VERSION ""

NS_ :

BS_:

BU_: HS_TESTER CPM AHU MFD IPC DSP _delete
VAL_TABLE_ _Shared_KeyCount 13 "Thirteen" 12 "Twelve" 11 "Eleven" 10 "Ten" 9 "Nine" 8 "Eight" 7 "Seven" 6 "Six" 5 "Five" 4 "Four" 3 "Three" 2 "Two" 1 "One" 0 "Zero" 15 "Invalid" 14 "Unlimited" ;
VAL_TABLE_ _Shared_LevelLow 3 "Invalid" 2 "Unknown" 1 "Low" 0 "OK" ;
VAL_TABLE_ _Shared_0_Disable_1_Enable 1 "Enable" 0 "Disable" ;
VAL_TABLE_ _Shared_PrkAidStat 3 "Faulted" 2 "Unused" 1 "Enabled" 0 "Disabled" ;
VAL_TABLE_ _Shared_PrkAidZone 15 "Zone_15" 14 "Zone_14" 13 "Zone_13" 12 "Zone_12" 11 "Zone_11" 10 "Zone_10" 9 "Zone_9" 8 "Zone_8" 7 "Zone_7" 6 "Zone_6" 5 "Zone_5" 4 "Zone_4" 3 "Zone_3" 2 "Zone_2" 1 "Zone_1" 0 "Off" ;
VAL_TABLE_ _Shared_PA_Chime 15 "Zone15_Chime" 14 "Zone14_Chime" 13 "Zone13_Chime" 12 "Zone12_Chime" 11 "Zone11_Chime" 10 "Zone10_Chime" 9 "Zone9_Chime" 8 "Zone8_Chime" 7 "Zone7_Chime" 6 "Zone6_Chime" 5 "Zone5_Chime" 4 "Zone4_Chime" 3 "Zone3_Chime" 2 "Zone2_Chime" 1 "Zone1_Chime" 0 "No_Chime" ;
VAL_TABLE_ _Shared_SeatFnChng2 15 "Fault" 14 "Not_Used8" 13 "Not_Used7" 12 "Not_Used6" 11 "Not_Used5" 10 "Not_Used4" 9 "Not_Used3" 8 "Not_Used2" 7 "Not_Used1" 6 "High" 5 "Low" 4 "Off" 3 "Decrease" 2 "Increase" 1 "Not_Used" 0 "Inactive" ;
VAL_TABLE_ _Shared_Chime 63 "Chime_62" 4 "Chime_3" 3 "Chime_2" 2 "Chime_1" 1 "NoChime" 0 "Inactive" ;
VAL_TABLE_ _Shared_AwdRnge 7 "Unknown" 6 "High_Range_2wd" 5 "High_Range_Auto" 4 "High_Range_Locked" 3 "Neutral" 2 "Low_Range_2wd" 1 "Low_Range_Auto" 0 "Low_Range_Locked" ;
VAL_TABLE_ _Shared_Pers 7 "Unused_3" 6 "Unused_2" 5 "Unused_1" 4 "Vehicle" 3 "PERS_4" 2 "PERS_3" 1 "PERS_2" 0 "PERS_1" ;
VAL_TABLE_ _Shared_AR_RUAudioSource_NA 15 "iPod" 14 "USB" 13 "BTAudio" 0 "AmfmRadio" 1 "FrontDisc" 2 "SDARS_DAB" 3 "InDashCdChanger" 4 "VoiceRecogniser" 5 "TelematicUnit" 6 "BluetoothPhone" 7 "RearDisc" 8 "APIM" 9 "FrontAuxInput" 10 "Navigation" 11 "RearAux" 12 "NotReq" ;
VAL_TABLE_ _Shared_PsgrMemory 8 "Recall_4" 7 "Recall_3" 6 "Recall_2" 5 "Recall_1" 4 "Store_4" 3 "Store_3" 2 "Store_2" 1 "Store_1" 0 "Inactive" ;
VAL_TABLE_ _Shared_Stms_Cshn_Lmbr 3 "High" 2 "Low" 1 "Off" 0 "Null" ;
VAL_TABLE_ _Shared_SeatFn_Null 7 "CushionMassage" 6 "LumbarMassage" 5 "UpperBolster" 4 "LowerBolster" 3 "UpperLumbar" 2 "MiddleLumbar" 1 "LowerLumbar" 0 "Null" ;
VAL_TABLE_ _Shared_0_NotUpdating_1_Updating 1 "Updating" 0 "NotUpdating" ;
VAL_TABLE_ _Shared_SeatFn_Inactive 7 "CushionMassage" 6 "LumbarMassage" 5 "UpperBolster" 4 "LowerBolster" 3 "UpperLumbar" 2 "MiddleLumbar" 1 "LowerLumbar" 0 "Inactive" ;
VAL_TABLE_ _Shared_SeatFnChng 2 "Decrease" 1 "Increase" 0 "Inactive" ;
VAL_TABLE_ _Shared_7F_Null 127 "Null" ;
VAL_TABLE_ _Shared_0_Invld_1_Vld 1 "Valid" 0 "Invalid" ;
VAL_TABLE_ _Shared_0_NotAvlble_1_Avlble 1 "Available" 0 "Not_Available" ;
VAL_TABLE_ _Shared_MonthReport 2 "Available" 1 "Unavailable" 0 "No_Data_Exists" ;
VAL_TABLE_ _Shared_0_NoReq_1_Req 1 "Request" 0 "NoRequest" ;
VAL_TABLE_ _Shared_TempDispDigit 2 "_5" 1 "_0" 0 "OFF" ;
VAL_TABLE_ _Shared_BlowInd 15 "Display_Blank" 14 "14_Indicators_On" 13 "13_Indicators_On" 12 "12_Indicators_On" 11 "11_Indicators_On" 10 "10_Indicators_On" 9 "9_Indicators_On" 8 "8_Indicators_On" 7 "7_Indicators_On" 6 "6_Indicators_On" 5 "5_Indicators_On" 4 "4_Indicators_On" 3 "3_Indicators_On" 2 "2_Indicators_On" 1 "1_Indicator_On" 0 "Indicators_Off" ;
VAL_TABLE_ _Shared_TempUnit 2 "Fahrenheit" 1 "Celsius" 0 "Off" ;
VAL_TABLE_ _Shared_CondSeat 7 "Unused" 6 "Level_3_Heating" 5 "Level_2_Heating" 4 "Level_1_Heating" 3 "Level_3_Cooling" 2 "Level_2_Cooling" 1 "Level_1_Cooling" 0 "Off" ;
VAL_TABLE_ _Shared_Btn_Stt 3 "Unused" 2 "Disabled" 1 "Active" 0 "Enabled_Inactive" ;
VAL_TABLE_ _Shared_E_Unlimited_F_NoDatEx 15 "NoDataExist" 14 "Unlimited" ;
VAL_TABLE_ _Shared_Speed 31 "mph90" 30 "mph85" 29 "mph80" 28 "mph75" 27 "mph70" 26 "mph65" 25 "mph60" 24 "mph55" 23 "mph50" 22 "mph45" 21 "mph40" 20 "Kmh165" 19 "Kmh160" 18 "Kmh155" 17 "Kmh150" 16 "Kmh145" 15 "Kmh140" 14 "Kmh135" 13 "Kmh130" 12 "Kmh125" 11 "Kmh120" 10 "Kmh115" 9 "Kmh110" 8 "Kmh105" 7 "Kmh100" 6 "kmh95" 5 "kmh90" 4 "kmh85" 3 "kmh80" 2 "kmh75" 1 "kmh70" 0 "Off" ;
VAL_TABLE_ _Shared_0_NoDatEx_1_Off_2_On_3_R 3 "Reserved" 2 "On" 1 "Off" 0 "NoDataExist" ;
VAL_TABLE_ _Shared_E_Unlimited_F_Inactive 15 "Inactive" 14 "Unlimited" ;
VAL_TABLE_ _Shared_0_No_Dat_Ex_1_Off_2_On 2 "On" 1 "Off" 0 "No_Data_Exists" ;
VAL_TABLE_ _Shared_TirePress 14 "Tires_not_trained" 13 "Training_Complete" 12 "Train_InsideLeftRear_tire" 11 "Train_OutsideLeftRear_tire" 10 "Train_LeftRear_tire" 9 "Train_InsideRtRear__tire" 8 "Train_OutsideRtRear_tire" 7 "Train_RightRear_tire" 6 "Train_RightFront_tire" 5 "Train_LeftFront_tire" 4 "Systm_Activ_Composite_Stat" 3 "Low_Composite_Stat" 2 "Sensr_Fault_Composite_Stat" 1 "Systm_Fault_Composite_Stat" 0 "Unknown_Composite_Stat" ;
VAL_TABLE_ _Shared_0_Inactive_1_Off_2_On 2 "On" 1 "Off" 0 "Inactive" ;
VAL_TABLE_ _Shared_Petal 7 "NoDataExist" 6 "NotUsed" 5 "petal_1_to_5" 4 "petal_1_to_4" 3 "petal_1_to_3" 2 "petal_1_to_2" 1 "petal_1" 0 "all_petals_off" ;
VAL_TABLE_ _Shared_WarningChime 1 "Chime_On" 0 "Chime_Off" ;
VAL_TABLE_ _Shared_0_NoDatEx_1_Off_2_On_3_r 3 "reserved" 2 "On" 1 "Off" 0 "NoDataExist" ;
VAL_TABLE_ _Shared_0_Inactive_1_Off_2_On_3_ 3 "reserved" 2 "On" 1 "Off" 0 "Inactive" ;
VAL_TABLE_ _Shared_0_Inctve_1_Enbl_2_Disbl 2 "Disable" 1 "Enable" 0 "Inactive" ;
VAL_TABLE_ _Shared_FE_Unknown_FF_Invalid 254 "Unknown" 255 "Invalid" ;
VAL_TABLE_ _Shared_1FE_Unknown_1FF_Invalid 511 "Invalid" 510 "Unknown" ;
VAL_TABLE_ _Shared_3FFE_Unknown_3FFF_Invali 16383 "Invalid" 16382 "Unknown" ;
VAL_TABLE_ _Shared_3E_Unknown_3F_Invalid 63 "Invalid" 62 "Unknown" ;
VAL_TABLE_ _Shared_1E_Unknown_1F_Invalid 31 "Invalid" 30 "Unknown" ;
VAL_TABLE_ _Shared_FF__invalid 255 "invalid" ;
VAL_TABLE_ _Shared_Closed_Ajar 1 "Ajar" 0 "Closed" ;
VAL_TABLE_ _Shared_MediaSrc 7 "Status7" 6 "Status6" 5 "Status5" 4 "Status4" 3 "Status3" 2 "Status2" 1 "Status1" 0 "NoDataExists" ;
VAL_TABLE_ _Shared_FF_Invalid 255 "Invalid" ;
VAL_TABLE_ _Shared_OffOnUnknownInvalid 1 "On" 0 "Off" 3 "Invalid" 2 "Unknown" ;
VAL_TABLE_ _Shared_0_Out_1_In 1 "In" 0 "Out" ;
VAL_TABLE_ _Shared_InactiveActive 1 "Active" 0 "Inactive" ;
VAL_TABLE_ _Shared_Off_On 1 "On" 0 "Off" ;
VAL_TABLE_ _Shared_QualityFactor 3 "OK" 2 "Not_Within_Specifications" 1 "No_Data_Exists" 0 "Fault" ;
VAL_TABLE_ _Shared_No_Yes 1 "Yes" 0 "No" ;
VAL_TABLE_ _Shared_1F_Fault 31 "Fault" ;
VAL_TABLE_ _Shared_DrvMde 7 "Faulty" 6 "NotUsed3" 5 "NotUsed2" 4 "NotUsed1" 3 "Track" 2 "Snow_Wet" 1 "Sport" 0 "Normal" ;
VAL_TABLE_ _Shared_3FE_Unknown_3FF_Fault 1023 "Fault" 1022 "Unknown" ;
VAL_TABLE_ _Shared_OffOnFlash 3 "Not_Used" 2 "Flash" 1 "On" 0 "Off" ;
VAL_TABLE_ _Shared_FE_Unknown_FF_Fault 255 "Fault" 254 "Unknown" ;
VAL_TABLE_ _Shared_FFFF_Invalid 65535 "Invalid" ;
VAL_TABLE_ _Shared_OffOn2Flash 3 "Fast_Flash" 2 "Slow_Flash" 1 "On" 0 "Off" ;
VAL_TABLE_ _Shared_FFE_Unknown_FFF_Fault 4095 "Fault" 4094 "Unknown" ;
VAL_TABLE_ _Shared_7E_NoDatExts_7F_Faulty 127 "Faulty" 126 "NoDataExists" ;
VAL_TABLE_ _Shared_F_ModColdBoot 15 "Mod_Cold_Boot" ;
VAL_TABLE_ _Shared_AudioSource 2 "Stereo_SNK" 1 "Mono_SNK" 0 "OFF" ;
VAL_TABLE_ _Shared_0_Discnnct_1_Cnnct 1 "Connect" 0 "Disconnect" ;
VAL_TABLE_ _Shared_0_Denied_1_Granted 1 "Granted" 0 "Denied" ;
VAL_TABLE_ _Shared_FocusBar 7 "Focus_Bar_NA_on_current_Pop_Up" 6 "Focus_Bar_on_List_Item_6" 5 "Focus_Bar_on_List_Item_5" 4 "Focus_Bar_on_List_Item_4" 3 "Focus_Bar_on_List_Item_3" 2 "Focus_Bar_on_List_Item_2" 1 "Focus_Bar_on_List_Item_1" 0 "No_visible_Focus_Bar" ;
VAL_TABLE_ _Shared_PrimaryAudioSource 5 "CPM_Stereo" 4 "CPM_Mono" 1 "Tuner_AM" 0 "OFF" ;
VAL_TABLE_ _Shared_Mute_Unmute 1 "Unmute" 0 "Mute" ;
VAL_TABLE_ _Shared_0_NOP_1_CPM 1 "CPM" 0 "NOP" ;
VAL_TABLE_ _Shared_Released_Pressed 2 "Button_Pressed" 1 "Button_Released" 0 "NOP" ;
VAL_TABLE_ _Shared_FFFE_Unkn_FFFF_Invld 65535 "Invalid" 65534 "Unknown" ;
VAL_TABLE_ _Shared_AR_RURquesterPriority 0 "EmergencyServ" 1 "TelService" 2 "AutoAnswer" 3 "Ta" 4 "PttMutevoice" 5 "NavUserVoiceCmd" 6 "NavSysVoiceCmd" 7 "Radio" 8 "Disc" 9 "Alarm" 10 "Ptynews" 11 "Aux_ExtSource" 12 "BT_BTNavAndTelMute" 13 "ManualAudioMute" 14 "NotReq" ;
VAL_TABLE_ _Shared_ComPlayDigit 15 "Invalid" 14 "CommandNotIssued" 13 "Reserved3" 12 "Reserved2" 11 "Reserved1" 10 "Reserved" ;
VAL_TABLE_ _Shared_ComPlayType 4 "Track" 3 "FordPlaylist" 2 "FordFolder" 1 "CommandNotIssued" 0 "Invalid" ;
VAL_TABLE_ _Shared_ComPlayMode 10 "RepeatOff" 9 "RepeatTrack" 8 "RepeatFolder" 7 "RepeatCD" 6 "ShuffleOff" 5 "ShuffleFolder" 4 "ShuffleList" 3 "ShuffleCD" 2 "ShuffleAll" 1 "CommandNotIssued" 0 "Invalid" ;
VAL_TABLE_ _Shared_ComPlaySource 7 "BTAudio" 6 "iPod" 5 "USB" 4 "SDCard" 3 "CDChanger" 2 "SingleCD" 1 "CommandNotIssued" 0 "Invalid" ;
VAL_TABLE_ _Shared_NoUpdate_Update 1 "Update" 0 "NoUpdate" ;
VAL_TABLE_ _Shared_0_Inactive_1_Cancel 1 "Cancel" 0 "Inactive" ;
VAL_TABLE_ _Shared_IncomingCall 2 "DeclineIncomingCall" 1 "AcceptIncomingCall" 0 "Inactive" ;
VAL_TABLE_ _Shared_MCChannel 7 "MCChannel7" 6 "MCChannel6" 5 "MCChannel5" 4 "MCChannel4" 3 "MCChannel3" 2 "MCChannel2" 1 "MCChannel1" 0 "Inactive" ;
VAL_TABLE_ _Shared_LangUpdate 2 "Language_Not_Supported" 1 "Language_Updated" 0 "Inactive" ;
VAL_TABLE_ _Shared_LangSel 30 "Slovak" 29 "Arabic" 28 "Taiwanese" 27 "Mandarin_Chinese" 26 "Korean" 25 "AU_English" 24 "Japanese" 23 "Braz_Portuguese" 22 "EU_Portuguese" 21 "Finish" 20 "Norwegian" 19 "Danish" 18 "Swedish" 17 "Hungarian" 16 "Greek" 15 "Czech" 14 "Polish" 13 "Flemish" 12 "Dutch" 11 "Russian" 10 "Turkish" 9 "Mex_Spanish" 8 "EU_Spanish" 7 "Cana_French" 6 "EU_French" 5 "Italian" 4 "German" 3 "NA_English" 2 "UK_English" 1 "Unknown" 0 "Invalid" ;
VAL_TABLE_ _Shared_TirePressStat 4 "Alert" 15 "Not_Supported" 3 "Fault" 2 "Low" 1 "Normal" 0 "Unknown" ;
VAL_TABLE_ _Shared_Not_Pressed_Pressed 1 "Pressed" 0 "Not_Pressed" ;
VAL_TABLE_ _Shared_0_Off 0 "Off" ;
VAL_TABLE_ _Shared_Enabled_Active_Disabled 2 "Disabled" 1 "Active" 0 "Enabled_Inactive" ;
VAL_TABLE_ _Shared_RVC_Zoom 7 "Unknown" 6 "Invalid" 5 "Zoom_Level_V" 4 "Zoom_Level_IV" 3 "Zoom_Level_III" 2 "Zoom_Level_II" 1 "Zoom_Level_I" 0 "Off" ;
VAL_TABLE_ _Shared_RVC_HMI 3 "Not_Used" 2 "Inactive" 1 "Active" 0 "Invalid" ;
VAL_TABLE_ _Shared_ButtonNotPressed_Pressed 1 "Button_Pressed" 0 "Button_Not_Pressed" ;
VAL_TABLE_ _Shared_QualityFactor_CMDB 3 "OK" 2 "Not_Within_Specifications" 1 "No_Data_Exists" 0 "Faulty" ;
VAL_TABLE_ _Shared_WhlDir 3 "Failed" 2 "Unknown" 1 "Backward" 0 "Forward" ;
VAL_TABLE_ _Shared_RearSystemMode 4 "Enabled_or_Auto" 3 "Floor" 2 "Panel_Floor" 1 "Panel" 0 "Off" ;
VAL_TABLE_ _Shared_Cond_Seat_Req 3 "RCCM_Is_Master" 2 "Heating_Requested" 1 "Cooling_Requested" 0 "Off" ;
VAL_TABLE_ _Shared_Cond_Seat_Lvl_RCCM 6 "Fault" 5 "Level_5_Most_Conditioning" 4 "Level_4" 3 "Level_3" 2 "Level_2" 1 "Level_1_Least_Conditioning" 0 "Off" ;
VAL_TABLE_ _Shared_Cond_Load_Shed 3 "Automatic_Override" 2 "HMI_Override" 1 "No_HMI_Override" 0 "No_Shed" ;
VAL_TABLE_ _Shared_UpdateBit 1 "Fresh_data" 0 "Unchanged_data" ;
VAL_TABLE_ _Shared_Fan_Bars_Disply 7 "Fan_Symbol__All_bars_ON" 6 "Fan_Symbol__1st_6_bars_ON" 5 "Fan_Symbol__1st_5_bars_ON" 4 "Fan_Symbol__1st_4_bars_ON" 3 "Fan_Symbol__1st_3_bars_ON" 2 "Fan_Symbol__1st_2_bars_ON" 1 "Fan_Symbol__1st_bar_ON" 0 "Fan_Symbol__All_bars_OFF" ;
VAL_TABLE_ _Shared_OpMode 7 "FastRewindSpeed2" 6 "FastRewindSpeed1" 5 "FastForwardSpeed2" 4 "FastForwardSpeed1" 3 "Pause" 2 "Play" 1 "Stop" 0 "Invalid" ;
VAL_TABLE_ _Shared_0_Invld_1_Inactv_2_Actv 0 "Invalid" 2 "Active" 1 "Inactive" ;
VAL_TABLE_ _Shared_MyKeyVolUp 2 "NotUpdated" 1 "Updated" 0 "Invalid" ;
VAL_TABLE_ _Shared_0_No_Req_1_Req 1 "Request" 0 "No_Request" ;
VAL_TABLE_ _Shared_AC_ManReq 2 "No_Man_Req" 1 "Man_Req_On" 0 "Man_Req_Off" ;
VAL_TABLE_ _Shared_Cond_Seat_Lvl 6 "Fault" 5 "Level_5_Most_Conditioning" 4 "Level_4_Most_Conditioning" 3 "Level_3_Most_Conditioning" 2 "Level_2_Most_Conditioning" 1 "Level_1_Most_Conditioning" 0 "Off" ;
VAL_TABLE_ _Shared_SeatSftBtnSt 7 "Disabled" 6 "Cl_Lo_Med_Hi_Ind_En_Active" 5 "Cl_Lo_Med_Ind_En_Active" 4 "Cl_Lo_Ind_En_Active" 3 "Ht_Lo_Med_Hi_Ind_En_Active" 2 "Ht_Lo_Med_Ind_En_Active" 1 "Ht_Lo_Ind_En_Active" 0 "No_Ind_Enabled_Active" ;
VAL_TABLE_ _Shared_0_EnbldInactve_1_Actve 1 "Active" 0 "Enabled_Inactive" ;
VAL_TABLE_ _Shared_ClmtCtrlSeat 128 "H3_High_Heat__MAX" 64 "H2_Medium_Heat" 32 "H1_Low_Heat" 16 "C3_High_Cool__MAX" 8 "C2_Medium_Cool" 4 "C1_Low_Cool" 2 "Off" ;
VAL_TABLE_ _Shared_Attenuation 7 "Unknown" 6 "Attenuation_6" 5 "Attenuation_5" 4 "Attenuation_4" 3 "Attenuation_3" 2 "Attenuation_2" 1 "Attenuation_1" 0 "Inactive" ;
VAL_TABLE_ _Shared_ChimeOccurence 15 "Continuous" 14 "14Repititions" 13 "13Repititions" 12 "12Repititions" 11 "11Repititions" 10 "10Repititions" 9 "9Repititions" 8 "8Repititions" 7 "7Repititions" 6 "6Repititions" 5 "5Repititions" 4 "4Repititions" 3 "3Repititions" 2 "2Repititions" 1 "PlayOnce" 0 "Inactive" ;
VAL_TABLE_ _Shared_ChimeTimeCriticality 2 "Low" 1 "High" 0 "Inactive" ;
VAL_TABLE_ _Shared_Directionality 3 "RearSpeakers" 2 "FrontSpeakers" 1 "ALL" 0 "Inactive" ;
VAL_TABLE_ _Shared_SetVolume 59 "+29Steps" 58 "+28Steps" 57 "+27Steps" 56 "+26Steps" 55 "+25Steps" 54 "+24Steps" 53 "+23Steps" 52 "+22Steps" 51 "+21Steps" 50 "+20Steps" 49 "+19Steps" 48 "+18Steps" 47 "+17Steps" 46 "+16Steps" 45 "+15Steps" 44 "+14Steps" 43 "+13Steps" 42 "+12Steps" 41 "+11Steps" 40 "+10Steps" 39 "+9Steps" 38 "+8Steps" 37 "+7Steps" 36 "+6Steps" 35 "+5Steps" 34 "+4Steps" 28 "-2Steps" 27 "-3Steps" 26 "-4Steps" 25 "-5Steps" 24 "-6Steps" 23 "-7Steps" 22 "-8Steps" 21 "-9Steps" 20 "-10Steps" 19 "-11Steps" 18 "-12Steps" 17 "-13Steps" 16 "-14Steps" 15 "-15Steps" 14 "-16Steps" 13 "-17Steps" 12 "-18Steps" 11 "-19Steps" 10 "-20Steps" 9 "-21Steps" 8 "-22Steps" 7 "-23Steps" 6 "-24Steps" 5 "-25Steps" 4 "-26Steps" 3 "-27Steps" 60 "+30Steps" 33 "+3Steps" 32 "+2Steps" 31 "+1Step" 30 "NotPressed_Inactive" 29 "-1Step" 2 "-28Steps" 1 "-29Steps" 0 "-30Steps" ;
VAL_TABLE_ _Shared_Sound 2 "Surround" 1 "Stereo" 0 "Inactive" ;
VAL_TABLE_ _Shared_SensorDist 1 "SensorDistDataValid" 0 "Invalid" ;
VAL_TABLE_ _Shared_ICIBtn 15 "Idle" 5 "Stuck" 4 "LongEvent" 3 "ShortElapsed" 2 "ShortEvent" 1 "Active" 0 "Inactive" ;
VAL_TABLE_ _Shared_DispUpdate 1 "HasRecentlyChanged" 0 "NoChange" ;
VAL_TABLE_ _Shared_TUPresetArea_Rq 13 "reserved" 12 "GetSAT3PresetData" 11 "GetSAT2PresetData" 15 "reserved_last" 10 "GetSAT1PresetData" 9 "GetDAB2PresetData" 8 "GetDAB1PresetData" 7 "GetDAB3PresetData" 6 "GetAmPresetData" 5 "GetAmAstPresetData" 4 "GetFmAstPresetData" 3 "GetFm3PresetData" 2 "GetFm2PresetData" 1 "GetFm1PresetData" 0 "Inactive" ;
VAL_TABLE_ _Shared_SetCurrTUBand 13 "reserved1" 12 "DAB3" 11 "SAT3" 10 "SAT2" 15 "reserved_last" 9 "SAT1" 8 "DAB2" 7 "DAB1" 6 "AmAst" 5 "Am" 4 "FmAst" 3 "Fm3" 2 "Fm2" 1 "Fm1" 0 "Inactive" ;
VAL_TABLE_ _Shared_TUServiceLink 3 "reserved" 2 "Inactive" 1 "Active" 0 "Invalid" ;
VAL_TABLE_ _Shared_ComTUSIDValid 1 "Validation" 0 "Invalid" ;
VAL_TABLE_ _Shared_0_Inactive_1_GetStatus 1 "Getstatus" 0 "Inactive" ;
VAL_TABLE_ _Shared_BTDeviceIndex 15 "BTDeviceIndex15" 14 "BTDeviceIndex14" 13 "BTDeviceIndex13" 12 "BTDeviceIndex12" 11 "BTDeviceIndex11" 10 "BTDeviceIndex10" 9 "BTDeviceIndex9" 8 "BTDeviceIndex8" 7 "BTDeviceIndex7" 6 "BTDeviceIndex6" 5 "BTDeviceIndex5" 4 "BTDeviceIndex4" 3 "BTDeviceIndex3" 2 "BTDeviceIndex2" 1 "BTDeviceIndex1" 0 "Inactive" ;
VAL_TABLE_ _Shared_BTFeatGroup 15 "Reserved_last" 8 "Reserved" 7 "Office" 6 "Video" 5 "Voice" 4 "MobileCom" 3 "Nav" 2 "MP" 1 "Radio" 0 "ALL" ;
VAL_TABLE_ _Shared_CutItem_Invalid 3 "ThreeQuarterFromTheBeginningOneQ" 2 "End" 1 "Beginning" 0 "Invalid" ;
VAL_TABLE_ _Shared_DB1Filter_10Bit 1023 "All" 1022 "SIIndex_1022" 1 "SIIndex_1" 0 "NotEngaged" ;
VAL_TABLE_ _Shared_DB1Filter_16Bit 65535 "All" 65534 "SIIndex_65534" 1 "SIIndex_1" 0 "NotEngaged" ;
VAL_TABLE_ _Shared_DSP_AlertChannel 3 "Initialized_for_chimes" 2 "Muted" 1 "Reserved" 0 "Inactive" ;
VAL_TABLE_ _Shared_Band 15 "Reserved1" 9 "Reserved" 8 "Amplitude_8" 7 "Amplitude_7" 6 "Amplitude_6" 4 "Amplitude_4" 2 "Amplitude_2" 5 "Amplitude_5" 3 "Amplitude_3" 1 "Amplitude_1" 0 "Amplitude_0" ;
VAL_TABLE_ _Shared_ChimeAlertChan 2 "Reserved" 1 "Mute" 0 "Inactive" ;
VAL_TABLE_ _Shared_ChimeSupprtd 2 "Not_Supported" 1 "Supported" 0 "Inactive" ;
VAL_TABLE_ _Shared_Chime_NotRecgnizd 0 "Inactive" 1 "Chime_Not_Recognized" ;
VAL_TABLE_ _Shared_InfotainmentVer_B 1 "B299" 0 "invalid" ;
VAL_TABLE_ _Shared_NotSupported_Supported 1 "Supported" 0 "Not_Supported" ;
VAL_TABLE_ _Shared_Skip 2 "Decrement" 1 "Increment" 0 "Inactive" ;
VAL_TABLE_ _Shared_IntScan_Shuffle_2 7 "Reserved4" 6 "Reserved3" 5 "Reserved2" 4 "Reserved1" 3 "OnTheFolderSelGroup" 2 "OnTheDevice" 1 "Off" 0 "Inactive" ;
VAL_TABLE_ _Shared_IntScan_Shuffle 3 "OnTheFolderSelGroup" 2 "OnTheDevice" 1 "Off" 0 "Invalid" ;
VAL_TABLE_ _Shared_MicMute 3 "Reserved" 2 "MicrophoneUnmute" 1 "MicrophoneMute" 0 "Inactive" ;
VAL_TABLE_ _Shared_AudioSource2 5 "SDCard" 4 "Reserved" 3 "USB" 2 "BTAudio" 1 "CD" 0 "Inactive" ;
VAL_TABLE_ _Shared_OpMode_0_Inactv 7 "FastRewind20" 6 "FastRewind10" 5 "FastForward20" 4 "FastForward10" 3 "Pause" 2 "Play" 1 "Stop" 0 "Inactive" ;
VAL_TABLE_ _Shared_ErrorSt 8 "NoDataInFolder" 7 "NoRespFromDevice" 6 "UnableToRead" 5 "NoDataOnDevice" 4 "FileSysNotSupported" 3 "DeviceNotSupported" 2 "InvalidFile" 1 "NoError" 0 "Invalid" ;
VAL_TABLE_ _Shared_FunctStatus 7 "Reserved2" 6 "Reserved1" 5 "Reserved" 4 "Reading" 3 "Ready" 2 "Initilization" 1 "Free" 0 "Invalid" ;
VAL_TABLE_ _Shared_OpMode_0_Invld 7 "FastRewind20" 6 "FastRewind10" 5 "FastForward20" 4 "FastForward10" 3 "Pause" 2 "Play" 1 "Stop" 0 "Invalid" ;
VAL_TABLE_ _Shared_Repeat 7 "Reserved2" 6 "Reserved1" 5 "Reserved" 4 "RepeatOnDevice" 3 "RepeatOnFolder" 2 "RepeatOnTrack" 1 "Off" 0 "Invalid" ;
VAL_TABLE_ _Shared_NbrOfItms 1 "OneItem" 0 "Standard" ;
VAL_TABLE_ _Shared_DB1SetConf 31 "UnknownActive" 30 "Reserved_last" 9 "Reserved" 8 "Podcast" 7 "Audiobook" 6 "Composer" 5 "Track" 4 "Genre" 3 "Album" 2 "Artist" 1 "Playlist" 0 "Root" ;
VAL_TABLE_ _Shared_VoiceCommand 2 "NotOk" 1 "Ok" 0 "Invalid" ;
VAL_TABLE_ _Shared_DSPProgram 7 "Reserved2" 6 "Reserved1" 5 "Voice" 4 "Rock" 0 "Invalid" 1 "Normal" 2 "Pop" 3 "Classical" ;
VAL_TABLE_ _Shared_CutItem_Inactive 3 "Inactive" 2 "ThreeQuarterFromTheBeginningOneQ" 1 "End" 0 "Beginning" ;
VAL_TABLE_ _Shared_FolderContent 2 "Inactive" 1 "RequestContentFromParentFolderOf" 0 "RequestContentFromParameterFolde" ;
VAL_TABLE_ _Shared_EndTelService 1 "EndOngoingTelephonyCall" 0 "Inactive" ;
VAL_TABLE_ _Shared_0_Invalid_FF_NoValidPres 255 "NoValidPreset" 0 "Invalid" ;
VAL_TABLE_ _Shared_SetCurrentStatOp 0 "Inactive" 1 "SetCurrentFrequency" 2 "SetCurrentPiCode" 3 "SetCurrentStation" ;
VAL_TABLE_ _Shared_CDSetRepeat 0 "Inactive" 1 "RepeatOnTrack" 2 "Off" 3 "OnFolder" ;
VAL_TABLE_ _Shared_0_Inactive_1_On_2_Off_3_ 0 "Inactive" 1 "On" 2 "Off" 3 "OnFolder" ;
VAL_TABLE_ _Shared_InfotainmentVer_C 0 "Invalid" 1 "C214Cd132My2003" 2 "C307My2004" ;
VAL_TABLE_ _Shared_FunctionStatus 7 "RemoveDisc" 0 "Invalid" 1 "Reading" 2 "Loading" 3 "Loaded" 4 "Insert" 5 "PreparingToEject" 6 "Ejecting" ;
VAL_TABLE_ _Shared_CD_On_Off_OnFolder 0 "Invalid" 1 "On" 2 "Off" 3 "OnFolder" ;
VAL_TABLE_ _Shared_0_Invalid_1_Off_2_On 0 "Invalid" 1 "Off" 2 "On" ;
VAL_TABLE_ _Shared_CDError 0 "Invalid" 1 "NoError" 2 "NoDiscs" 3 "UnableToReadDisc" ;
VAL_TABLE_ _Shared_VRM_ComSt 0 "Invalid" 1 "CommandNotIssued" 2 "On" 3 "Off" ;
VAL_TABLE_ _Shared_TripCompUnit 0 "TripComputer_metric" 1 "TripComputer_imperial" ;
VAL_TABLE_ _Shared_TempUnit2 0 "Temperature_deg_c" 1 "Temperature_deg_f" ;
VAL_TABLE_ _Shared_ModeSelect 3 "NotUsed" 2 "On" 1 "Off" 0 "NoModeSelected" ;
VAL_TABLE_ _Shared_EngExhMdeQuiet 3 "Faulty" 2 "QuietExhaust" 1 "LoudExhaust" 0 "Null" ;
VAL_TABLE_ _Shared_0_Inactive_1_On_2_Off 0 "Inactive" 1 "On" 2 "Off" ;
VAL_TABLE_ _Shared_IncCallOption 0 "Inactive" 1 "RejectAll" 2 "AcceptIncomingCall" 3 "Silent" ;
VAL_TABLE_ _Shared_PhoneIndex 0 "Inactive" 1 "PhoneIndex1" 2 "PhoneIndex2" 3 "PhoneIndex3" 4 "PhoneIndex4" 5 "PhoneIndex5" 6 "PhoneIndex6" ;
VAL_TABLE_ _Shared_ARReqstrSystem 0 "FrontRequester" 1 "RearRequester" ;
VAL_TABLE_ _Shared_AROperationType 0 "Inactive" 1 "Requestaudioresource" 2 "Releaseaudioresource" 3 "Releaseallaudioresouces" 4 "Getresourceupdate" 5 "Getallresourceupdates" ;
VAL_TABLE_ _Shared_SurndSndUpmix 4 "Audience" 3 "On_Stage" 2 "Surround" 1 "Stereo" 0 "Inactive" ;
VAL_TABLE_ _Shared_SidePrkSns 15 "NotUsed" 14 "NotFullyScannedYet" 13 "NoObjectInSector" 12 "Zone12" 11 "Zone11" 10 "Zone10" 9 "Zone9" 8 "Zone8" 7 "Zone7" 6 "Zone6" 5 "Zone5" 4 "Zone4" 3 "Zone3" 2 "Zone2" 1 "Zone1" 0 "Off" ;
VAL_TABLE_ _Shared_VRM_ModeReq 0 "Inactive" 1 "Off" 2 "Reserved" 3 "On" ;

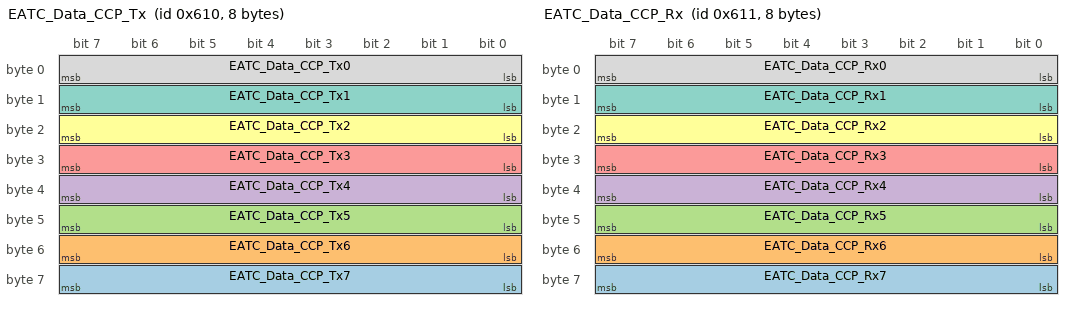
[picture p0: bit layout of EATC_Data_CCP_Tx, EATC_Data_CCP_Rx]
BO_ 1552 EATC_Data_CCP_Tx: 8 MFD
 SG_ EATC_Data_CCP_Tx7 : 63|8@0+ (1,0) [0|255] ""  HS_TESTER
 SG_ EATC_Data_CCP_Tx6 : 55|8@0+ (1,0) [0|255] ""  HS_TESTER
 SG_ EATC_Data_CCP_Tx5 : 47|8@0+ (1,0) [0|255] ""  HS_TESTER
 SG_ EATC_Data_CCP_Tx4 : 39|8@0+ (1,0) [0|255] ""  HS_TESTER
 SG_ EATC_Data_CCP_Tx3 : 31|8@0+ (1,0) [0|255] ""  HS_TESTER
 SG_ EATC_Data_CCP_Tx2 : 23|8@0+ (1,0) [0|255] ""  HS_TESTER
 SG_ EATC_Data_CCP_Tx1 : 15|8@0+ (1,0) [0|255] ""  HS_TESTER
 SG_ EATC_Data_CCP_Tx0 : 7|8@0+ (1,0) [0|255] ""  HS_TESTER

BO_ 1553 EATC_Data_CCP_Rx: 8 HS_TESTER
 SG_ EATC_Data_CCP_Rx7 : 63|8@0+ (1,0) [0|255] ""  MFD
 SG_ EATC_Data_CCP_Rx6 : 55|8@0+ (1,0) [0|255] ""  MFD
 SG_ EATC_Data_CCP_Rx5 : 47|8@0+ (1,0) [0|255] ""  MFD
 SG_ EATC_Data_CCP_Rx4 : 39|8@0+ (1,0) [0|255] ""  MFD
 SG_ EATC_Data_CCP_Rx3 : 31|8@0+ (1,0) [0|255] ""  MFD
 SG_ EATC_Data_CCP_Rx2 : 23|8@0+ (1,0) [0|255] ""  MFD
 SG_ EATC_Data_CCP_Rx1 : 15|8@0+ (1,0) [0|255] ""  MFD
 SG_ EATC_Data_CCP_Rx0 : 7|8@0+ (1,0) [0|255] ""  MFD

BO_ 597 AUDIO_RSE_WORD_Tx: 8 AHU
 SG_ AUDIO_RSE_WORD_Tx : 7|64@0+ (1,0) [0|1.84467440737096E+019] "unitless" Vector__XXX

BO_ 576 AUDIO_RDISP2_WORD_Tx: 8 AHU
 SG_ AUDIO_RDISP2_WORD_Tx : 7|64@0+ (1,0) [0|1.84467440737096E+019] "unitless" Vector__XXX

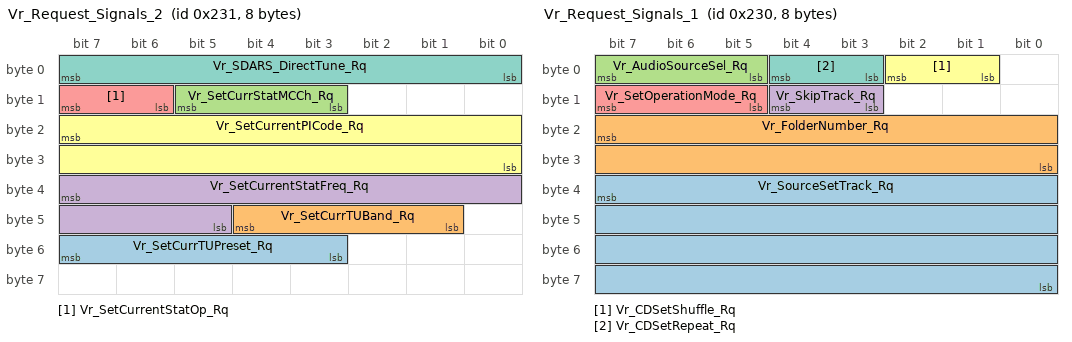
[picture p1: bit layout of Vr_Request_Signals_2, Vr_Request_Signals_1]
BO_ 561 Vr_Request_Signals_2: 8 CPM
 SG_ Vr_SetCurrTUPreset_Rq : 55|5@0+ (1,0) [0|0] "SED"  AHU
 SG_ Vr_SetCurrTUBand_Rq : 44|4@0+ (1,0) [0|0] ""  AHU
 SG_ Vr_SetCurrStatMCCh_Rq : 13|3@0+ (1,0) [0|0] ""  AHU
 SG_ Vr_SetCurrentStatFreq_Rq : 39|11@0+ (1,0) [0|1557] ""  AHU
 SG_ Vr_SetCurrentStatOp_Rq : 15|2@0+ (1,0) [0|0] ""  AHU
 SG_ Vr_SetCurrentPICode_Rq : 23|16@0+ (1,0) [0|65535] ""  AHU
 SG_ Vr_SDARS_DirectTune_Rq : 7|8@0+ (1,0) [0|0] ""  AHU

BO_ 560 Vr_Request_Signals_1: 8 CPM
 SG_ Vr_SourceSetTrack_Rq : 39|32@0+ (1,0) [0|4294967295] ""  AHU
 SG_ Vr_FolderNumber_Rq : 23|16@0+ (1,0) [0|65535] ""  AHU
 SG_ Vr_AudioSourceSel_Rq : 7|3@0+ (1,0) [0|0] ""  AHU
 SG_ Vr_SkipTrack_Rq : 12|2@0+ (1,0) [0|0] ""  AHU
 SG_ Vr_SetOperationMode_Rq : 15|3@0+ (1,0) [0|0] ""  AHU
 SG_ Vr_CDSetShuffle_Rq : 2|2@0+ (1,0) [0|0] ""  AHU
 SG_ Vr_CDSetRepeat_Rq : 4|2@0+ (1,0) [0|0] ""  AHU

BO_ 1210 SDARS_VR_WORD_Tx: 8 AHU
 SG_ SDARS_VR_WORD_Tx : 7|64@0+ (1,0) [0|1.84467440737096E+019] "unitless"  CPM

BO_ 1202 SDARS_VR_WORD_Rx: 8 CPM
 SG_ SDARS_VR_WORD_Rx : 7|64@0+ (1,0) [0|1.84467440737096E+019] "unitless"  AHU

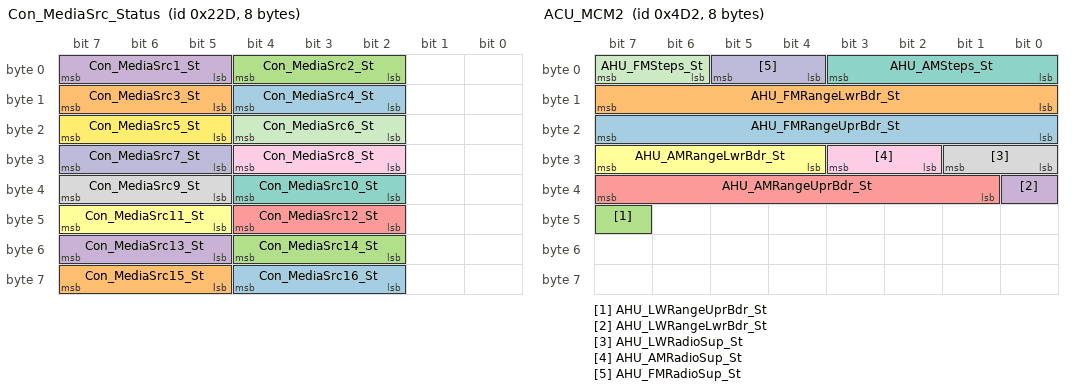
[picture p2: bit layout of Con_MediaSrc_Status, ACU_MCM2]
BO_ 557 Con_MediaSrc_Status: 8 CPM
 SG_ Con_MediaSrc16_St : 60|3@0+ (1,0) [0|0] ""  MFD
 SG_ Con_MediaSrc15_St : 63|3@0+ (1,0) [0|0] ""  MFD
 SG_ Con_MediaSrc14_St : 52|3@0+ (1,0) [0|0] ""  MFD
 SG_ Con_MediaSrc13_St : 55|3@0+ (1,0) [0|0] ""  MFD
 SG_ Con_MediaSrc12_St : 44|3@0+ (1,0) [0|0] ""  MFD
 SG_ Con_MediaSrc11_St : 47|3@0+ (1,0) [0|0] ""  MFD
 SG_ Con_MediaSrc10_St : 36|3@0+ (1,0) [0|0] ""  MFD
 SG_ Con_MediaSrc9_St : 39|3@0+ (1,0) [0|0] ""  MFD
 SG_ Con_MediaSrc8_St : 28|3@0+ (1,0) [0|0] ""  MFD
 SG_ Con_MediaSrc7_St : 31|3@0+ (1,0) [0|0] ""  MFD
 SG_ Con_MediaSrc6_St : 20|3@0+ (1,0) [0|0] ""  MFD
 SG_ Con_MediaSrc5_St : 23|3@0+ (1,0) [0|0] ""  MFD
 SG_ Con_MediaSrc4_St : 12|3@0+ (1,0) [0|0] ""  MFD
 SG_ Con_MediaSrc3_St : 15|3@0+ (1,0) [0|0] ""  MFD
 SG_ Con_MediaSrc2_St : 4|3@0+ (1,0) [0|0] ""  MFD
 SG_ Con_MediaSrc1_St : 7|3@0+ (1,0) [0|0] ""  MFD

BO_ 1234 ACU_MCM2: 8 AHU
 SG_ AHU_FMRangeUprBdr_St : 23|8@0+ (0.1,90) [90|115.5] "MHz"  MFD
 SG_ AHU_FMRangeLwrBdr_St : 15|8@0+ (0.1,76) [76|101.5] "MHz"  MFD
 SG_ AHU_LWRangeUprBdr_St : 47|1@0+ (1,279) [279|280] "kHz"  MFD
 SG_ AHU_LWRangeLwrBdr_St : 32|1@0+ (1,153) [153|154] "kHz"  MFD
 SG_ AHU_AMRangeUprBdr_St : 39|7@0+ (1,1620) [1620|1747] "kHz"  MFD
 SG_ AHU_AMRangeLwrBdr_St : 31|4@0+ (1,522) [522|537] "kHz"  MFD
 SG_ AHU_AMSteps_St : 3|4@0+ (1,0) [0|15] "kHz"  MFD
 SG_ AHU_LWRadioSup_St : 25|2@0+ (1,0) [0|0] "0"  MFD
 SG_ AHU_AMRadioSup_St : 27|2@0+ (1,0) [0|0] ""  MFD
 SG_ AHU_FMRadioSup_St : 5|2@0+ (1,0) [0|0] ""  MFD
 SG_ AHU_FMSteps_St : 7|2@0+ (50,50) [50|200] "kHz"  MFD

BO_ 531 DesiredTorqBrk_HS3: 8 IPC
 SG_ VehStop_D_Stat : 28|2@0+ (1,0) [0|3] "SED" Vector__XXX
 SG_ PrkBrkMsgTxt_D_Rq : 36|4@0+ (1,0) [0|0] "SED" Vector__XXX
 SG_ PrkBrkYwLamp_D_Rq : 38|2@0+ (1,0) [0|0] "SED" Vector__XXX
 SG_ PrkBrkStatus : 26|3@0+ (1,0) [0|0] "" Vector__XXX
 SG_ PrkBrkRedLamp_D_Rq : 30|2@0+ (1,0) [0|0] "SED" Vector__XXX
 SG_ CmbbBrkDis_B_Actl : 56|1@0+ (1,0) [0|0] "" Vector__XXX
 SG_ CmbbBaSensInc_B_Actl : 57|1@0+ (1,0) [0|0] "" Vector__XXX
 SG_ CmbbBrkDecel_B_Actl : 58|1@0+ (1,0) [0|0] "" Vector__XXX
 SG_ CmbbBrkPrchg_B_Actl : 59|1@0+ (1,0) [0|0] "" Vector__XXX
 SG_ CmbbDeny_B_ActlBrk : 60|1@0+ (1,0) [0|0] "" Vector__XXX
 SG_ AccBrkPrchgActv_B_Actl : 61|1@0+ (1,0) [0|0] "" Vector__XXX
 SG_ AccBrkTotTqMn_B_Actl : 62|1@0+ (1,0) [0|0] "" Vector__XXX
 SG_ AccBrkWarm_B_Actl : 63|1@0+ (1,0) [0|0] "" Vector__XXX
 SG_ VehLongOvrGnd_A_Est : 41|10@0+ (0.035,-17.9) [-17.9|17.835] "m/s^2" Vector__XXX
 SG_ AccBrkDeny_B_Actl : 42|1@0+ (1,0) [0|0] "" Vector__XXX
 SG_ AccBrkActv_B_Actl : 43|1@0+ (1,0) [0|0] "" Vector__XXX
 SG_ AccBrkDis_B_Actl : 44|1@0+ (1,0) [0|0] "" Vector__XXX
 SG_ AbsActv_B_Actl : 45|1@0+ (1,0) [0|0] "" Vector__XXX
 SG_ PrplDrgCtlActv_B_Actl : 46|1@0+ (1,0) [0|0] "" Vector__XXX
 SG_ CcDis_B_Cmd : 47|1@0+ (1,0) [0|0] "" Vector__XXX
 SG_ AccDis_B_ActlEpb : 32|1@0+ (1,0) [0|0] "" Vector__XXX
 SG_ VehicleStationary : 39|1@0+ (1,0) [0|0] "" Vector__XXX
 SG_ LscmbBrkPrchg_B_Actl : 16|1@0+ (1,0) [0|0] "" Vector__XXX
 SG_ LscmbbMntr_B_Err : 17|1@0+ (1,0) [0|0] "SED" Vector__XXX
 SG_ LscmbbDeny_B_ActlBrk : 18|1@0+ (1,0) [0|0] "" Vector__XXX
 SG_ LscmbbBrkDis_B_Actl : 19|1@0+ (1,0) [0|0] "" Vector__XXX
 SG_ LscmbbBrkDecel_B_Actl : 20|1@0+ (1,0) [0|0] "" Vector__XXX
 SG_ LscmbbBaSensInc_B_Actl : 21|1@0+ (1,0) [0|0] "" Vector__XXX
 SG_ AccStopActv_B_ActlBrk : 22|1@0+ (1,0) [0|0] "" Vector__XXX
 SG_ StabCtlBrkActv_B_Actl : 23|1@0+ (1,0) [0|0] "" Vector__XXX
 SG_ PrplWhlTot_Tq_RqMx : 7|16@0+ (4,-131072) [-131072|131068] "Nm" Vector__XXX
 SG_ TracCtlPtActv_B_Actl : 31|1@0+ (1,0) [0|0] "SED" Vector__XXX

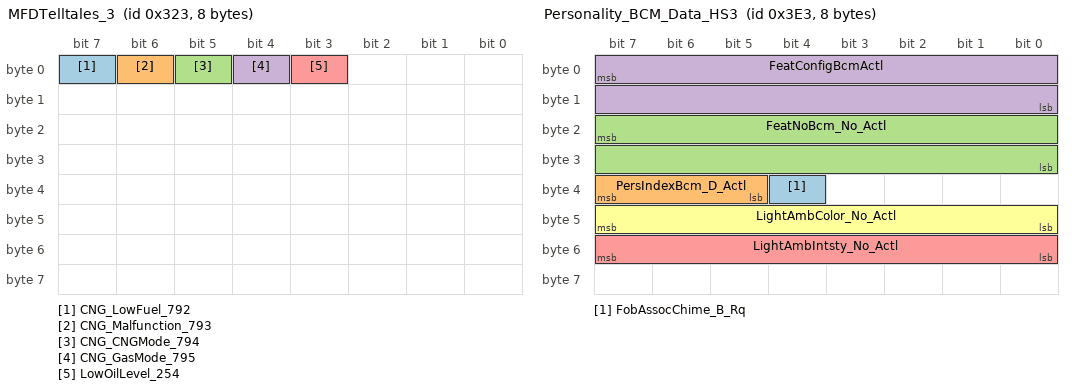
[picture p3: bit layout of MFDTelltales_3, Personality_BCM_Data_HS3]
BO_ 803 MFDTelltales_3: 8 IPC
 SG_ CNG_LowFuel_792 : 7|1@0+ (1,0) [0|0] ""  MFD
 SG_ CNG_Malfunction_793 : 6|1@0+ (1,0) [0|0] ""  MFD
 SG_ CNG_CNGMode_794 : 5|1@0+ (1,0) [0|0] ""  MFD
 SG_ CNG_GasMode_795 : 4|1@0+ (1,0) [0|0] ""  MFD
 SG_ LowOilLevel_254 : 3|1@0+ (1,0) [0|0] ""  MFD

BO_ 1591 DevID_IPC_FrTx2: 8 IPC
 SG_ DevID_IPC_Tx2_i : 7|64@0+ (1,0) [0|1.84467440737096E+019] "unitless" Vector__XXX

BO_ 1499 FCDIM_AutoSar_Network_Mgmt: 8 MFD
 SG_ FCDIM_AutoSar_NetworkMgmt : 7|64@0+ (1,0) [0|1.8446744074E+019] "unitless" Vector__XXX

BO_ 1537 DevID_IPC_FrTx1: 8 IPC
 SG_ DevID_IPC_Tx1_i : 7|64@0+ (1,0) [0|1.84467440737096E+019] "unitless" Vector__XXX

BO_ 697 AUDIO_MC_WORD_Rx: 8 IPC
 SG_ AUDIO_MC_WORD_Rx : 7|64@0+ (1,0) [0|1.84467440737096E+019] "unitless"  AHU

BO_ 995 Personality_BCM_Data_HS3: 8 IPC
 SG_ FobAssocChime_B_Rq : 36|1@0+ (1,0) [0|0] "SED" Vector__XXX
 SG_ PersIndexBcm_D_Actl : 39|3@0+ (1,0) [0|0] "SED" Vector__XXX
 SG_ FeatNoBcm_No_Actl : 23|16@0+ (1,0) [0|65535] "Number" Vector__XXX
 SG_ FeatConfigBcmActl : 7|16@0+ (1,0) [0|65535] "Undefined" Vector__XXX
 SG_ LightAmbIntsty_No_Actl : 55|8@0+ (1,0) [0|255] "unitless"  MFD
 SG_ LightAmbColor_No_Actl : 47|8@0+ (1,0) [0|255] "Discrete"  MFD

BO_ 906 Body_Info_1_HS3: 8 IPC
 SG_ CcdMsgTxt_D_RqDsply_UB : 47|1@0+ (1,0) [0|0] "SED" Vector__XXX
 SG_ CcdMsgTxt_D_RqDsply : 19|4@0+ (1,0) [0|0] "SED" Vector__XXX
 SG_ SlMde_D_RqDsply : 57|2@0+ (1,0) [0|3] "SED" Vector__XXX
 SG_ IsaOffst_D_Stat : 61|4@0+ (1,0) [0|15] "SED" Vector__XXX
 SG_ SlMde_D_Stat : 63|2@0+ (1,0) [0|3] "SED" Vector__XXX
 SG_ SlMde_D_RqDsply_UB : 24|1@0+ (1,0) [0|0] "" Vector__XXX
 SG_ ApaChime_D_Rq_UB : 25|1@0+ (1,0) [0|0] "" Vector__XXX
 SG_ ApaChime_D_Rq : 34|3@0+ (1,0) [0|7] "SED" Vector__XXX
 SG_ MemDrvDeny_B_Stat_UB : 35|1@0+ (1,0) [0|0] "" Vector__XXX
 SG_ MemDrvDeny_B_Stat : 36|1@0+ (1,0) [0|1] "SED" Vector__XXX
 SG_ BrkDrvMde_D_Stat_UB : 22|1@0+ (1,0) [0|0] "" Vector__XXX
 SG_ BrkDrvMde_D_Stat : 15|3@0+ (1,0) [0|7] "SED" Vector__XXX
 SG_ HeadLghtHiOn_B_StatHcm_UB : 12|1@0+ (1,0) [0|0] "" Vector__XXX
 SG_ HeadLghtHiOn_B_StatHcm : 5|1@0+ (1,0) [0|1] "SED" Vector__XXX
 SG_ Running_Board_Stat : 11|2@0+ (1,0) [0|3] "SED" Vector__XXX
 SG_ PrkLckCtlUnlck_D_Stat : 9|2@0+ (1,0) [0|3] "SED" Vector__XXX
 SG_ PrkLckCtlTow_B_Enbl : 4|1@0+ (1,0) [0|1] "SED" Vector__XXX
 SG_ DrTgateChime2_D_Rq : 39|3@0+ (1,0) [0|7] "SED" Vector__XXX
 SG_ TurnLghtSwtch_D_Stat_UB : 40|1@0+ (1,0) [0|1] "SED" Vector__XXX
 SG_ TurnLghtSwtch_D_Stat : 29|2@0+ (1,0) [0|3] "SED" Vector__XXX
 SG_ Adaptive_Hdlmp_Fault_UB : 26|1@0+ (1,0) [0|1] "SED" Vector__XXX
 SG_ Memory_Feedback_Rqst_UB : 21|1@0+ (1,0) [0|1] "SED" Vector__XXX
 SG_ PrkLckCtl_B_Enbl_UB : 42|1@0+ (1,0) [0|1] "SED" Vector__XXX
 SG_ PrkLckCtl_B_Enbl : 43|1@0+ (1,0) [0|1] "SED" Vector__XXX
 SG_ PrkLckCtlMsgTxt_D_Rq_UB : 41|1@0+ (1,0) [0|1] "SED" Vector__XXX
 SG_ PrkLckCtlMsgTxt_D_Rq : 45|2@0+ (1,0) [0|3] "SED" Vector__XXX
 SG_ PrkLckCtlAvail_T_Stat_UB : 46|1@0+ (1,0) [0|1] "SED" Vector__XXX
 SG_ PrkLckCtlAvail_T_Stat : 55|8@0+ (1,0) [0|255] "second" Vector__XXX
 SG_ DrTgateChime2_D_Rq_UB : 23|1@0+ (1,0) [0|1] "SED" Vector__XXX
 SG_ GearLvrPos_D_Actl_UB : 6|1@0+ (1,0) [0|1] "SED" Vector__XXX
 SG_ Power_Liftgate_Mode_Stt_UB : 20|1@0+ (1,0) [0|1] "SED" Vector__XXX
 SG_ Adaptive_Hdlmp_Fault : 27|1@0+ (1,0) [0|1] "SED" Vector__XXX
 SG_ Power_Liftgate_Mode_Stt : 31|2@0+ (1,0) [0|3] "SED" Vector__XXX
 SG_ Memory_Feedback_Rqst : 7|1@0+ (1,0) [0|1] "SED" Vector__XXX
 SG_ GearLvrPos_D_Actl : 3|4@0+ (1,0) [0|0] "SED" Vector__XXX

BO_ 991 Personality_VDM_Data_HS3: 8 IPC
 SG_ PersIndexVdm_D_Actl : 39|3@0+ (1,0) [0|0] "SED" Vector__XXX
 SG_ FeatNoVdmActl : 23|16@0+ (1,0) [0|65535] "Number" Vector__XXX
 SG_ FeatConfigVdmActl : 7|16@0+ (1,0) [0|65535] "Undefined" Vector__XXX

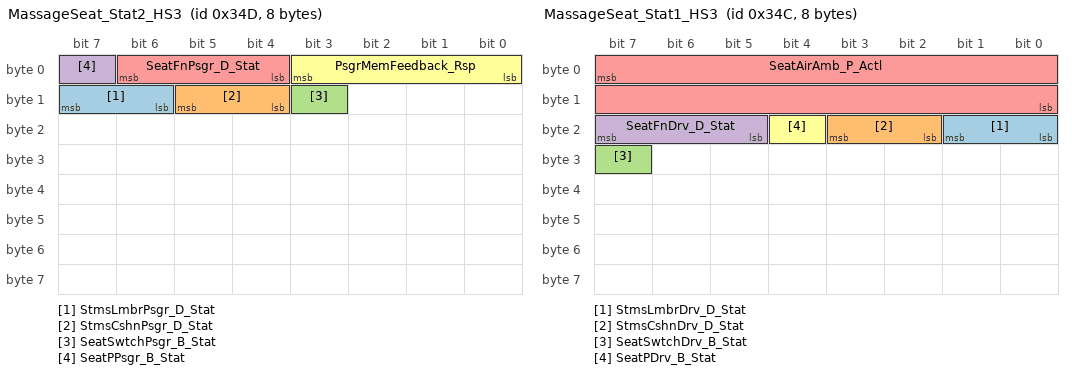
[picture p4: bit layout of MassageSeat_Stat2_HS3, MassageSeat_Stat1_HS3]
BO_ 845 MassageSeat_Stat2_HS3: 8 IPC
 SG_ StmsLmbrPsgr_D_Stat : 15|2@0+ (1,0) [0|0] "SED" Vector__XXX
 SG_ StmsCshnPsgr_D_Stat : 13|2@0+ (1,0) [0|0] "SED" Vector__XXX
 SG_ SeatSwtchPsgr_B_Stat : 11|1@0+ (1,0) [0|0] "SED" Vector__XXX
 SG_ SeatPPsgr_B_Stat : 7|1@0+ (1,0) [0|0] "SED" Vector__XXX
 SG_ SeatFnPsgr_D_Stat : 6|3@0+ (1,0) [0|0] "SED" Vector__XXX
 SG_ PsgrMemFeedback_Rsp : 3|4@0+ (1,0) [0|0] "SED" Vector__XXX

BO_ 844 MassageSeat_Stat1_HS3: 8 IPC
 SG_ StmsLmbrDrv_D_Stat : 17|2@0+ (1,0) [0|0] "SED" Vector__XXX
 SG_ StmsCshnDrv_D_Stat : 19|2@0+ (1,0) [0|0] "SED" Vector__XXX
 SG_ SeatSwtchDrv_B_Stat : 31|1@0+ (1,0) [0|0] "SED" Vector__XXX
 SG_ SeatFnDrv_D_Stat : 23|3@0+ (1,0) [0|0] "SED" Vector__XXX
 SG_ SeatAirAmb_P_Actl : 7|16@0+ (0.01,0) [0|655.35] "KiloPascal" Vector__XXX
 SG_ SeatPDrv_B_Stat : 20|1@0+ (1,0) [0|0] "SED" Vector__XXX

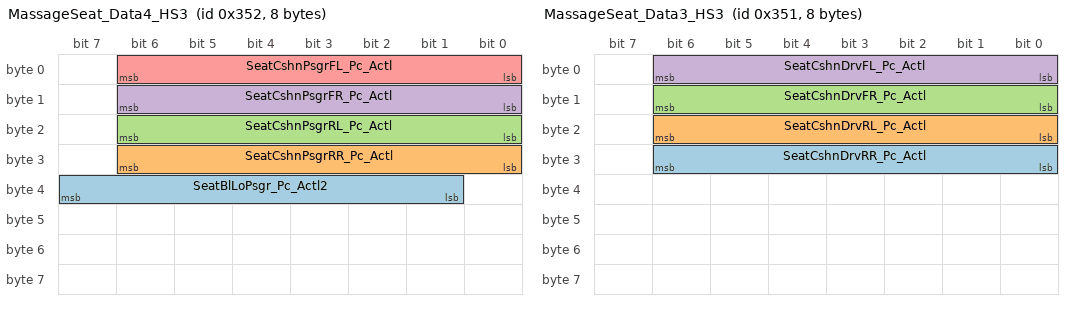
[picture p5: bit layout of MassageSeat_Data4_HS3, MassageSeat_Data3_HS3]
BO_ 850 MassageSeat_Data4_HS3: 8 IPC
 SG_ SeatBlLoPsgr_Pc_Actl2 : 39|7@0+ (1,0) [0|126] "Percent" Vector__XXX
 SG_ SeatCshnPsgrRR_Pc_Actl : 30|7@0+ (1,0) [0|126] "Percent" Vector__XXX
 SG_ SeatCshnPsgrRL_Pc_Actl : 22|7@0+ (1,0) [0|126] "Percent" Vector__XXX
 SG_ SeatCshnPsgrFR_Pc_Actl : 14|7@0+ (1,0) [0|126] "Percent" Vector__XXX
 SG_ SeatCshnPsgrFL_Pc_Actl : 6|7@0+ (1,0) [0|126] "Percent" Vector__XXX

BO_ 849 MassageSeat_Data3_HS3: 8 IPC
 SG_ SeatCshnDrvRR_Pc_Actl : 30|7@0+ (1,0) [0|126] "Percent" Vector__XXX
 SG_ SeatCshnDrvRL_Pc_Actl : 22|7@0+ (1,0) [0|126] "Percent" Vector__XXX
 SG_ SeatCshnDrvFR_Pc_Actl : 14|7@0+ (1,0) [0|126] "Percent" Vector__XXX
 SG_ SeatCshnDrvFL_Pc_Actl : 6|7@0+ (1,0) [0|126] "Percent" Vector__XXX

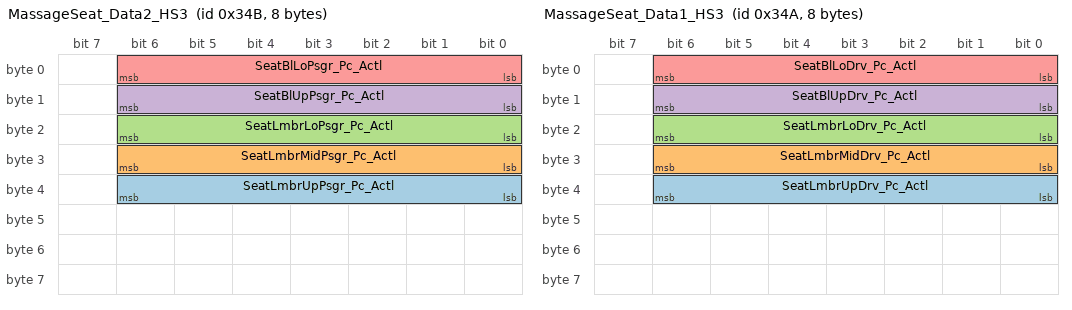
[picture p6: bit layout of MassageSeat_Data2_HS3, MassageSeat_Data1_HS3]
BO_ 843 MassageSeat_Data2_HS3: 8 IPC
 SG_ SeatLmbrUpPsgr_Pc_Actl : 38|7@0+ (1,0) [0|126] "Percent" Vector__XXX
 SG_ SeatLmbrMidPsgr_Pc_Actl : 30|7@0+ (1,0) [0|126] "Percent" Vector__XXX
 SG_ SeatLmbrLoPsgr_Pc_Actl : 22|7@0+ (1,0) [0|126] "Percent" Vector__XXX
 SG_ SeatBlUpPsgr_Pc_Actl : 14|7@0+ (1,0) [0|126] "Percent" Vector__XXX
 SG_ SeatBlLoPsgr_Pc_Actl : 6|7@0+ (1,0) [0|126] "Percent" Vector__XXX

BO_ 842 MassageSeat_Data1_HS3: 8 IPC
 SG_ SeatLmbrUpDrv_Pc_Actl : 38|7@0+ (1,0) [0|126] "Percent" Vector__XXX
 SG_ SeatLmbrMidDrv_Pc_Actl : 30|7@0+ (1,0) [0|126] "Percent" Vector__XXX
 SG_ SeatLmbrLoDrv_Pc_Actl : 22|7@0+ (1,0) [0|126] "Percent" Vector__XXX
 SG_ SeatBlUpDrv_Pc_Actl : 14|7@0+ (1,0) [0|126] "Percent" Vector__XXX
 SG_ SeatBlLoDrv_Pc_Actl : 6|7@0+ (1,0) [0|126] "Percent" Vector__XXX

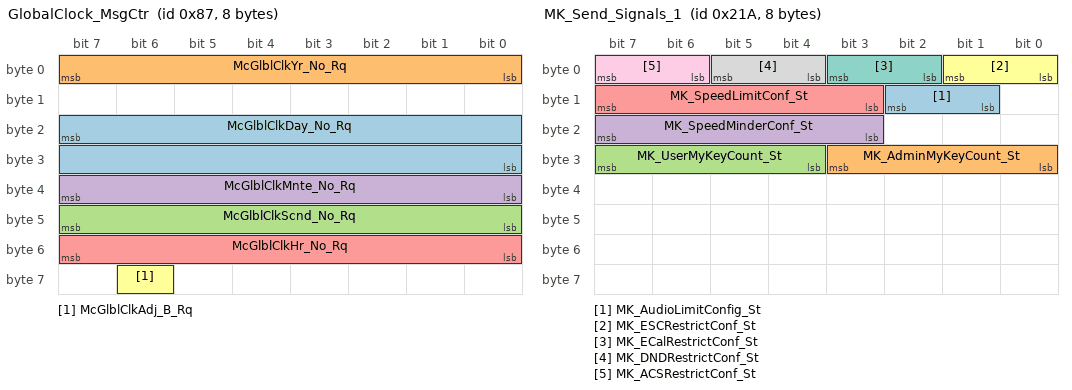
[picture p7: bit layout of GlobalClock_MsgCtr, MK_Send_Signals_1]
BO_ 135 GlobalClock_MsgCtr: 8 IPC
 SG_ McGlblClkDay_No_Rq : 23|16@0+ (1,0) [0|65535] "julian day" Vector__XXX
 SG_ McGlblClkYr_No_Rq : 7|8@0+ (1,2000) [2000|2255] "year" Vector__XXX
 SG_ McGlblClkScnd_No_Rq : 47|8@0+ (1,0) [0|255] "second" Vector__XXX
 SG_ McGlblClkMnte_No_Rq : 39|8@0+ (1,0) [0|255] "minute" Vector__XXX
 SG_ McGlblClkHr_No_Rq : 55|8@0+ (1,0) [0|255] "hour" Vector__XXX
 SG_ McGlblClkAdj_B_Rq : 62|1@0+ (1,0) [0|0] "SED" Vector__XXX

BO_ 1242 DimmingInfraStruct_MCM: 8 IPC
 SG_ DimmerHMISrcStatus : 5|2@0+ (1,0) [0|0] ""  MFD
 SG_ ALSCfgStatus : 7|2@0+ (1,0) [0|0] ""  MFD

BO_ 538 MK_Send_Signals_1: 8 IPC
 SG_ MK_AudioLimitConfig_St : 10|2@0+ (1,0) [0|0] ""  MFD
 SG_ MK_AdminMyKeyCount_St : 27|4@0+ (1,0) [0|13] ""  MFD
 SG_ MK_UserMyKeyCount_St : 31|4@0+ (1,0) [0|13] ""  MFD
 SG_ MK_SpeedMinderConf_St : 23|5@0+ (1,0) [0|0] ""  MFD
 SG_ MK_SpeedLimitConf_St : 15|5@0+ (1,0) [0|0] ""  MFD
 SG_ MK_ESCRestrictConf_St : 1|2@0+ (1,0) [0|0] ""  MFD
 SG_ MK_ECalRestrictConf_St : 3|2@0+ (1,0) [0|0] ""  MFD,CPM
 SG_ MK_DNDRestrictConf_St : 5|2@0+ (1,0) [0|0] ""  CPM,MFD
 SG_ MK_ACSRestrictConf_St : 7|2@0+ (1,0) [0|0] ""  MFD

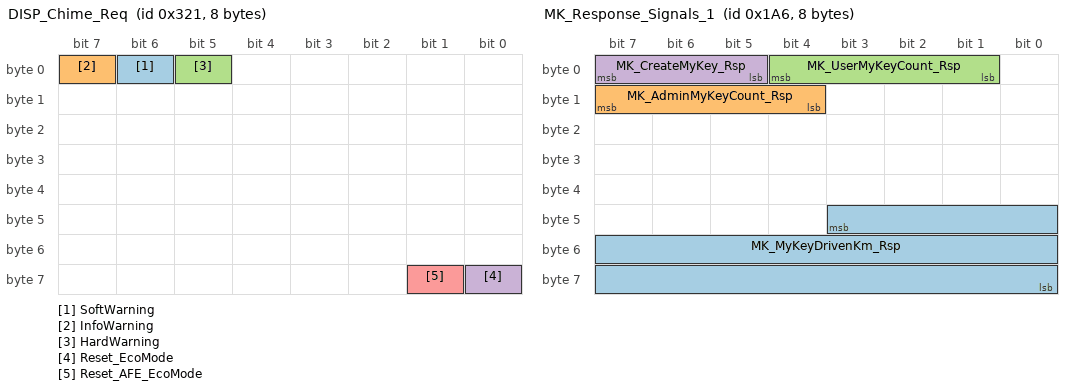
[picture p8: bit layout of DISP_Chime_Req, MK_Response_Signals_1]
BO_ 801 DISP_Chime_Req: 8 MFD
 SG_ SoftWarning : 6|1@0+ (1,0) [0|0] ""  IPC
 SG_ InfoWarning : 7|1@0+ (1,0) [0|0] ""  IPC
 SG_ HardWarning : 5|1@0+ (1,0) [0|0] ""  IPC
 SG_ Reset_EcoMode : 56|1@0+ (1,0) [0|0] ""  IPC
 SG_ Reset_AFE_EcoMode : 57|1@0+ (1,0) [0|0] ""  IPC

BO_ 422 MK_Response_Signals_1: 8 IPC
 SG_ MK_MyKeyDrivenKm_Rsp : 43|20@0+ (1,0) [0|1048574] "km"  MFD
 SG_ MK_AdminMyKeyCount_Rsp : 15|4@0+ (1,0) [0|13] ""  MFD
 SG_ MK_UserMyKeyCount_Rsp : 4|4@0+ (1,0) [0|13] ""  MFD
 SG_ MK_CreateMyKey_Rsp : 7|3@0+ (1,0) [0|0] ""  MFD

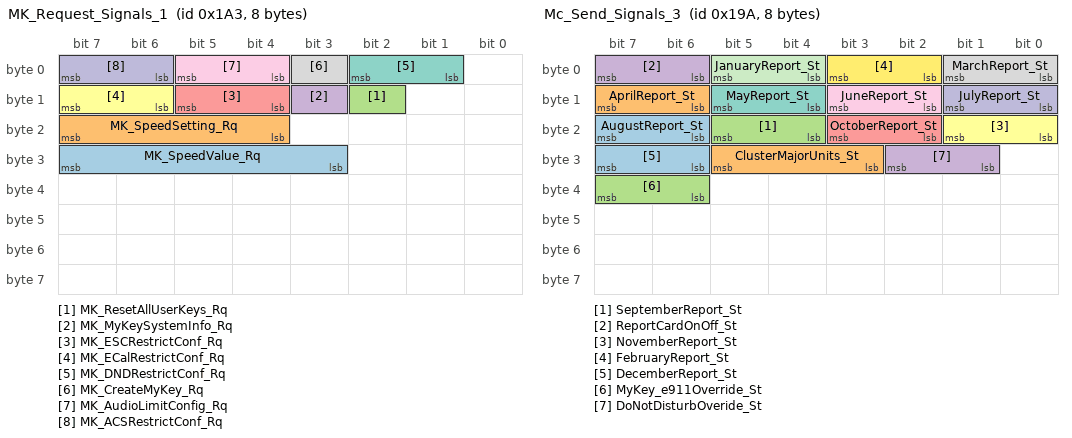
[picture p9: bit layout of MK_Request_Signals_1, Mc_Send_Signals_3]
BO_ 419 MK_Request_Signals_1: 8 MFD
 SG_ MK_SpeedValue_Rq : 31|5@0+ (1,0) [0|0] ""  IPC
 SG_ MK_SpeedSetting_Rq : 23|4@0+ (1,0) [0|0] ""  IPC
 SG_ MK_ResetAllUserKeys_Rq : 10|1@0+ (1,0) [0|0] ""  IPC
 SG_ MK_MyKeySystemInfo_Rq : 11|1@0+ (1,0) [0|0] ""  IPC
 SG_ MK_ESCRestrictConf_Rq : 13|2@0+ (1,0) [0|0] ""  IPC
 SG_ MK_ECalRestrictConf_Rq : 15|2@0+ (1,0) [0|0] ""  IPC
 SG_ MK_DNDRestrictConf_Rq : 2|2@0+ (1,0) [0|0] ""  IPC
 SG_ MK_CreateMyKey_Rq : 3|1@0+ (1,0) [0|0] ""  IPC
 SG_ MK_AudioLimitConfig_Rq : 5|2@0+ (1,0) [0|0] ""  IPC
 SG_ MK_ACSRestrictConf_Rq : 7|2@0+ (1,0) [0|0] ""  IPC

BO_ 410 Mc_Send_Signals_3: 8 IPC
 SG_ AugustReport_St : 23|2@0+ (1,0) [0|0] "" Vector__XXX
 SG_ AprilReport_St : 15|2@0+ (1,0) [0|0] "" Vector__XXX
 SG_ SeptemberReport_St : 21|2@0+ (1,0) [0|0] "" Vector__XXX
 SG_ ReportCardOnOff_St : 7|2@0+ (1,0) [0|0] "" Vector__XXX
 SG_ OctoberReport_St : 19|2@0+ (1,0) [0|0] "" Vector__XXX
 SG_ NovemberReport_St : 17|2@0+ (1,0) [0|0] "" Vector__XXX
 SG_ MayReport_St : 13|2@0+ (1,0) [0|0] "" Vector__XXX
 SG_ MarchReport_St : 1|2@0+ (1,0) [0|0] "" Vector__XXX
 SG_ JuneReport_St : 11|2@0+ (1,0) [0|0] "" Vector__XXX
 SG_ JulyReport_St : 9|2@0+ (1,0) [0|0] "" Vector__XXX
 SG_ JanuaryReport_St : 5|2@0+ (1,0) [0|0] "" Vector__XXX
 SG_ FebruaryReport_St : 3|2@0+ (1,0) [0|0] "" Vector__XXX
 SG_ DecemberReport_St : 31|2@0+ (1,0) [0|0] "" Vector__XXX
 SG_ ClusterMajorUnits_St : 29|3@0+ (1,0) [0|0] "" Vector__XXX
 SG_ MyKey_e911Override_St : 39|2@0+ (1,0) [0|0] ""  MFD,CPM
 SG_ DoNotDisturbOveride_St : 26|2@0+ (1,0) [0|0] ""  MFD

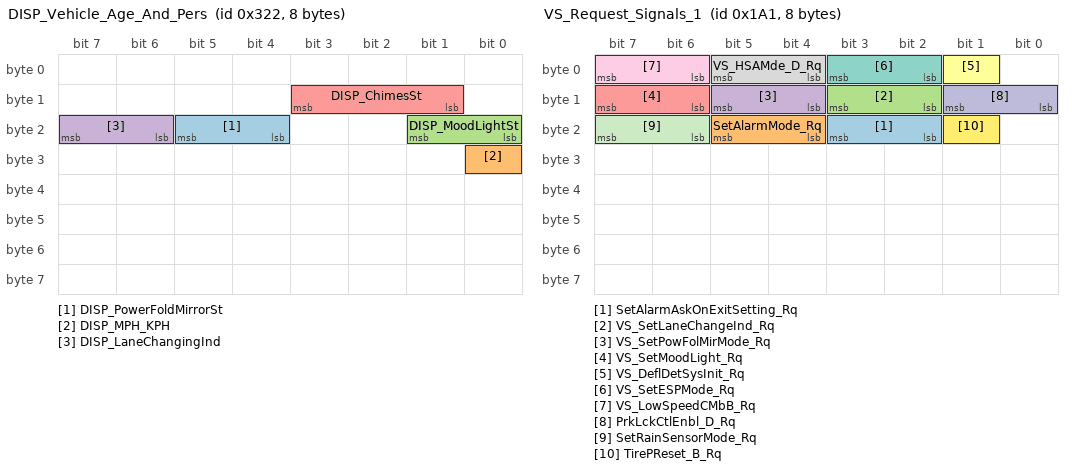
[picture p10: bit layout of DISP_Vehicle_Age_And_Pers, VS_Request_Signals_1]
BO_ 802 DISP_Vehicle_Age_And_Pers: 8 MFD
 SG_ DISP_PowerFoldMirrorSt : 21|2@0+ (1,0) [0|0] ""  IPC
 SG_ DISP_MPH_KPH : 24|1@0+ (1,0) [0|0] ""  IPC
 SG_ DISP_MoodLightSt : 17|2@0+ (1,0) [0|0] ""  IPC
 SG_ DISP_LaneChangingInd : 23|2@0+ (1,0) [0|0] ""  IPC
 SG_ DISP_ChimesSt : 11|3@0+ (1,0) [0|0] ""  IPC

BO_ 417 VS_Request_Signals_1: 8 MFD
 SG_ SetAlarmAskOnExitSetting_Rq : 19|2@0+ (1,0) [0|0] ""  IPC
 SG_ SetAlarmMode_Rq : 21|2@0+ (1,0) [0|0] ""  IPC
 SG_ VS_SetLaneChangeInd_Rq : 11|2@0+ (1,0) [0|0] ""  IPC
 SG_ VS_SetPowFolMirMode_Rq : 13|2@0+ (1,0) [0|0] ""  IPC
 SG_ VS_SetMoodLight_Rq : 15|2@0+ (1,0) [0|0] ""  IPC
 SG_ VS_DeflDetSysInit_Rq : 1|1@0+ (1,0) [0|0] ""  IPC
 SG_ VS_SetESPMode_Rq : 3|2@0+ (1,0) [0|0] ""  IPC
 SG_ VS_HSAMde_D_Rq : 5|2@0+ (1,0) [0|0] ""  IPC
 SG_ VS_LowSpeedCMbB_Rq : 7|2@0+ (1,0) [0|0] ""  IPC
 SG_ PrkLckCtlEnbl_D_Rq : 9|2@0+ (1,0) [0|0] ""  IPC
 SG_ SetRainSensorMode_Rq : 23|2@0+ (1,0) [0|0] ""  IPC
 SG_ TirePReset_B_Rq : 17|1@0+ (1,0) [0|0] "Discrete"  IPC

BO_ 793 MFDTelltales_2: 8 IPC
 SG_ EngineOn_98 : 8|1@0+ (1,0) [0|0] ""  MFD
 SG_ Soot_DPFSootLevel2_578 : 58|1@0+ (1,0) [0|0] ""  MFD
 SG_ Soot_DPFRegen_537 : 59|1@0+ (1,0) [0|0] ""  MFD
 SG_ Soot_DPFRegen_536 : 60|1@0+ (1,0) [0|0] ""  MFD
 SG_ TopSpeedInfo_666 : 61|1@0+ (1,0) [0|0] ""  MFD
 SG_ Headlamp_Failure_430 : 62|1@0+ (1,0) [0|0] ""  MFD
 SG_ ParkBrake_Hard_626 : 63|1@0+ (1,0) [0|0] ""  MFD
 SG_ ParkBrake_Soft_625 : 48|1@0+ (1,0) [0|0] ""  MFD
 SG_ TPMS_NotTraiRepeat_969 : 49|1@0+ (1,0) [0|0] ""  MFD
 SG_ TPMS_TrainingCompl_968 : 50|1@0+ (1,0) [0|0] ""  MFD
 SG_ TPMS_TraiInLeRear_967 : 51|1@0+ (1,0) [0|0] ""  MFD
 SG_ TPMS_TraiOutLeRear_966 : 52|1@0+ (1,0) [0|0] ""  MFD
 SG_ TPMS_TrainLeftRear_965 : 53|1@0+ (1,0) [0|0] ""  MFD
 SG_ TPMS_TraiInRiRear_964 : 54|1@0+ (1,0) [0|0] ""  MFD
 SG_ TPMS_TraiOutRiRear_963 : 55|1@0+ (1,0) [0|0] ""  MFD
 SG_ TPMS_TraiRiRear_962 : 40|1@0+ (1,0) [0|0] ""  MFD
 SG_ TPMS_TraiRiFront_961 : 41|1@0+ (1,0) [0|0] ""  MFD
 SG_ TPMS_TraiLeftFront_960 : 42|1@0+ (1,0) [0|0] ""  MFD
 SG_ TPMS_GlobalWarning_493 : 43|1@0+ (1,0) [0|0] ""  MFD
 SG_ TPMS_NoSensors_474 : 44|1@0+ (1,0) [0|0] ""  MFD
 SG_ TPMS_Malfunction_400 : 45|1@0+ (1,0) [0|0] ""  MFD
 SG_ PAHWSwitchOffIn_671 : 24|1@0+ (1,0) [0|0] ""  MFD
 SG_ ESCHWSwitchOffIn_676 : 25|1@0+ (1,0) [0|0] ""  MFD
 SG_ SpeedMinder_665 : 16|1@0+ (1,0) [0|0] ""  MFD
 SG_ MyKeyActive_660 : 9|1@0+ (1,0) [0|0] ""  MFD
 SG_ SpeedLimitIndic_661 : 10|1@0+ (1,0) [0|0] ""  MFD
 SG_ SpeedLimitInfo_667 : 11|1@0+ (1,0) [0|0] ""  MFD
 SG_ Point_Highspeed : 34|1@0+ (1,0) [0|0] ""  MFD
 SG_ Point_Gearshift : 35|1@0+ (1,0) [0|0] ""  MFD
 SG_ Point_Anticip : 36|1@0+ (1,0) [0|0] ""  MFD
 SG_ I_highspeed : 39|3@0+ (1,0) [0|0] ""  MFD
 SG_ I_gearshift : 28|3@0+ (1,0) [0|0] ""  MFD
 SG_ I_anticip : 31|3@0+ (1,0) [0|0] ""  MFD
 SG_ Pcnt_EngineColdTrips : 23|7@0+ (1,0) [0|100] "%"  MFD
 SG_ OTIS_PressBAndC_657 : 0|1@0+ (1,0) [0|0] ""  MFD
 SG_ OTIS_PressBrake_655 : 1|1@0+ (1,0) [0|0] ""  MFD
 SG_ OTIS_PressClutch_656 : 2|1@0+ (1,0) [0|0] ""  MFD
 SG_ LSSS_PostIncident_710 : 3|1@0+ (1,0) [0|0] ""  MFD
 SG_ LSSS_Malfunction_712 : 4|1@0+ (1,0) [0|0] ""  MFD
 SG_ LSSS_CleanSensor_711 : 5|1@0+ (1,0) [0|0] ""  MFD
 SG_ DDS_PressureWarning_512 : 6|1@0+ (1,0) [0|0] ""  MFD
 SG_ DDS_Unavailable_513 : 7|1@0+ (1,0) [0|0] ""  MFD
 SG_ ECOADVICE4 : 12|1@0+ (1,0) [0|0] ""  MFD
 SG_ ECOADVICE3 : 13|1@0+ (1,0) [0|0] ""  MFD
 SG_ ECOADVICE2 : 14|1@0+ (1,0) [0|0] ""  MFD
 SG_ ECOADVICE1 : 15|1@0+ (1,0) [0|0] ""  MFD
 SG_ BTSI_MORShiftNotIP_752 : 46|1@0+ (1,0) [0|0] ""  MFD
 SG_ BTSI_MORShiftUnloc_751 : 47|1@0+ (1,0) [0|0] ""  MFD
 SG_ BTSI_MORPreBraToUn_750 : 32|1@0+ (1,0) [0|0] ""  MFD
 SG_ OTIS_StartOvrheat_658 : 33|1@0+ (1,0) [0|0] ""  MFD
 SG_ ECSS_StartPdgWait_790 : 57|1@0+ (1,0) [0|0] ""  MFD
 SG_ ECSS_PendingStart_791 : 56|1@0+ (1,0) [0|0] ""  MFD

BO_ 753 VS_Send_Signals_1: 8 IPC
 SG_ AlarmPopUp_St : 4|2@0+ (1,0) [0|0] ""  MFD
 SG_ AlarmMode_St : 36|2@0+ (1,0) [0|0] ""  MFD
 SG_ AlarmAskOnExitSetting_St : 34|2@0+ (1,0) [0|0] ""  MFD
 SG_ VS_WiperStalkRotat_St : 39|3@0+ (1,0) [0|0] ""  MFD
 SG_ VS_WiperStalkPos_St : 26|3@0+ (1,0) [0|0] ""  MFD
 SG_ VS_RainSensorMode_St : 28|2@0+ (1,0) [0|0] ""  MFD
 SG_ VS_LaneChangIndMode_St : 17|2@0+ (1,0) [0|0] ""  MFD
 SG_ VS_HSAMde_D_Mem_St : 19|2@0+ (1,0) [0|0] ""  MFD
 SG_ VS_PowFolMirMode_St : 9|2@0+ (1,0) [0|0] ""  MFD
 SG_ VS_LscmbbOnOff_D_St : 11|2@0+ (1,0) [0|0] ""  MFD
 SG_ VS_MoodLightMode_St : 13|2@0+ (1,0) [0|0] ""  MFD
 SG_ VS_StabilityControl_St : 15|2@0+ (1,0) [0|0] ""  MFD
 SG_ StopStartMsg_OnDemand_St : 23|4@0+ (1,0) [0|0] ""  MFD
 SG_ DeflDetSysStatus : 2|3@0+ (1,0) [0|0] ""  MFD
 SG_ VS_ESPLongPress_St : 29|1@0+ (1,0) [0|0] ""  MFD
 SG_ PrkLckCtl_B_Enbl_St : 30|1@0+ (1,0) [0|0] ""  MFD
 SG_ PrkLckCtl_B_Allow_St : 31|1@0+ (1,0) [0|0] ""  MFD
 SG_ TirePReset_D_Stat : 47|2@0+ (1,0) [0|0] "Discrete"  MFD

BO_ 752 MFDTelltales: 8 IPC
 SG_ TransmDIWarnMsg3 : 63|4@0+ (1,0) [0|0] ""  MFD
 SG_ HillStartAssistOffWOChime_428 : 22|1@0+ (1,0) [0|0] ""  MFD
 SG_ HillStartAssistOffWChime_582 : 15|1@0+ (1,0) [0|0] ""  MFD
 SG_ HillStartAssistNotAvailable_429 : 7|1@0+ (1,0) [0|0] ""  MFD
 SG_ HillStartAssistActive_427 : 0|1@0+ (1,0) [0|0] ""  MFD
 SG_ PJB_TriggCause_419 : 59|4@0+ (1,0) [0|0] ""  MFD
 SG_ AlarmServicerequired_476 : 36|1@0+ (1,0) [0|0] ""  MFD
 SG_ PassengerDoorStatus2_214 : 30|1@0+ (1,0) [0|0] ""  MFD
 SG_ DriverDoorStatus2_212 : 31|1@0+ (1,0) [0|0] ""  MFD
 SG_ EpasFailed_258 : 14|1@0+ (1,0) [0|0] ""  MFD
 SG_ ToStartPressBrake_485 : 50|1@0+ (1,0) [0|0] ""  MFD
 SG_ ToStartPressNeutral_744 : 49|1@0+ (1,0) [0|0] ""  MFD
 SG_ ToStartPressBrake_749 : 48|1@0+ (1,0) [0|0] ""  MFD
 SG_ NotInPark_745 : 52|1@0+ (1,0) [0|0] ""  MFD
 SG_ DoorOpenNotInPark_488 : 53|1@0+ (1,0) [0|0] ""  MFD
 SG_ KVM_Service_567 : 55|1@0+ (1,0) [0|0] ""  MFD
 SG_ CloseBootUseSpareKey_501 : 41|1@0+ (1,0) [0|0] ""  MFD
 SG_ SCLFailureIndTorqued_500 : 42|1@0+ (1,0) [0|0] ""  MFD
 SG_ SCLFailureIndStop_495 : 43|1@0+ (1,0) [0|0] ""  MFD
 SG_ SCLFailureIndSERVICE_494 : 44|1@0+ (1,0) [0|0] ""  MFD
 SG_ PKOutOfVehicle_498 : 45|1@0+ (1,0) [0|0] ""  MFD
 SG_ PKNotDetected_496 : 46|1@0+ (1,0) [0|0] ""  MFD
 SG_ HigherPowerMode_497 : 47|1@0+ (1,0) [0|0] ""  MFD
 SG_ PressClutch_502 : 32|1@0+ (1,0) [0|0] ""  MFD
 SG_ PressBrake_499 : 33|1@0+ (1,0) [0|0] ""  MFD
 SG_ ExchangePKBattery_522 : 34|1@0+ (1,0) [0|0] ""  MFD
 SG_ DisplayRequest_522 : 37|1@0+ (1,0) [0|0] ""  MFD
 SG_ ISS_StatusDspReq_207 : 38|1@0+ (1,0) [0|0] ""  MFD
 SG_ AutoLRainSSensorFail_729 : 39|1@0+ (1,0) [0|0] ""  MFD
 SG_ LeftDIFailure_703 : 24|1@0+ (1,0) [0|0] ""  MFD
 SG_ RightDIFailure_704 : 25|1@0+ (1,0) [0|0] ""  MFD
 SG_ BonnetLidStatus2_217 : 26|1@0+ (1,0) [0|0] ""  MFD
 SG_ BootLidStatus_216 : 27|1@0+ (1,0) [0|0] ""  MFD
 SG_ PassengerSideRearDoorStatus2_215 : 28|1@0+ (1,0) [0|0] ""  MFD
 SG_ DriverSideRearDoorStatus2_213 : 29|1@0+ (1,0) [0|0] ""  MFD
 SG_ BootLidStatus_520 : 16|1@0+ (1,0) [0|0] ""  MFD
 SG_ BonnetStatus_521 : 17|1@0+ (1,0) [0|0] ""  MFD
 SG_ PassengerSideRearDoorStatus_519 : 18|1@0+ (1,0) [0|0] ""  MFD
 SG_ DriverSideRearDoorStatus_518 : 19|1@0+ (1,0) [0|0] ""  MFD
 SG_ DriverDoorStatus_516 : 21|1@0+ (1,0) [0|0] ""  MFD
 SG_ BrakeWarningTelltale_746 : 9|1@0+ (1,0) [0|0] ""  MFD
 SG_ ABS_Telltale_523 : 11|1@0+ (1,0) [0|0] ""  MFD
 SG_ StabilityControlSt_218b : 12|1@0+ (1,0) [0|0] ""  MFD
 SG_ StabilityControlTel_218c : 13|1@0+ (1,0) [0|0] ""  MFD
 SG_ TransmDIWarnMsg_484 : 1|1@0+ (1,0) [0|0] ""  MFD
 SG_ TransmissionFailure_483 : 2|1@0+ (1,0) [0|0] ""  MFD
 SG_ DPFSootOverload_535 : 4|1@0+ (1,0) [0|0] ""  MFD
 SG_ ChangeOilNow_469 : 5|1@0+ (1,0) [0|0] ""  MFD
 SG_ PassengerDoorStatus_517 : 20|1@0+ (1,0) [0|0] ""  MFD
 SG_ RIL_RequestStatus_530 : 8|1@0+ (1,0) [0|0] ""  MFD
 SG_ BrakeFluidLevel_515 : 10|1@0+ (1,0) [0|0] ""  MFD
 SG_ EngineCheck_440 : 3|1@0+ (1,0) [0|0] ""  MFD
 SG_ EngOilPressureTelltale_526 : 6|1@0+ (1,0) [0|0] ""  MFD
 SG_ SS_TurnIgnitionOff_643 : 54|1@0+ (1,0) [0|0] ""  MFD
 SG_ SS_SelectNeutral_644 : 51|1@0+ (1,0) [0|0] ""  MFD
 SG_ SS_PressClutch_641 : 35|1@0+ (1,0) [0|0] ""  MFD
 SG_ SS_StartEngineManually_642 : 40|1@0+ (1,0) [0|0] ""  MFD
 SG_ SS_EngineStarting_640 : 23|1@0+ (1,0) [0|0] ""  MFD

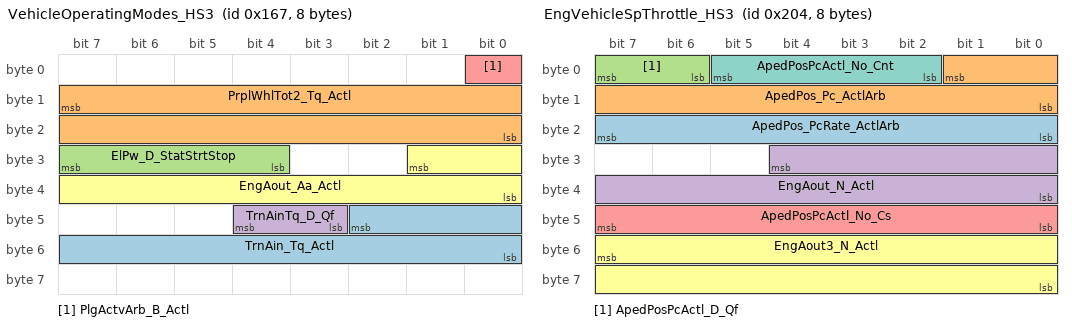
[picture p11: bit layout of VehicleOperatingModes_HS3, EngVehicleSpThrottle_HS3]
BO_ 359 VehicleOperatingModes_HS3: 8 IPC
 SG_ TrnAin_Tq_Actl : 42|11@0+ (1,-500) [-500|1547] "Nm"  CPM,AHU
 SG_ PrplWhlTot2_Tq_Actl : 15|16@0+ (4,-131072) [-131072|131060] "Nm" Vector__XXX
 SG_ ElPw_D_StatStrtStop : 31|4@0+ (1,0) [0|0] "SED" Vector__XXX
 SG_ TrnAinTq_D_Qf : 44|2@0+ (1,0) [0|0] "SED"  AHU
 SG_ PlgActvArb_B_Actl : 0|1@0+ (1,0) [0|0] "SED" Vector__XXX
 SG_ EngAout_Aa_Actl : 25|10@0+ (0.05,-25.6) [-25.6|25.55] "rpm/ms" Vector__XXX

BO_ 516 EngVehicleSpThrottle_HS3: 8 IPC
 SG_ ApedPos_PcRate_ActlArb : 23|8@0+ (0.04,-5) [-5|5.12] "%/ms" Vector__XXX
 SG_ ApedPos_Pc_ActlArb : 1|10@0+ (0.1,0) [0|102.3] "%"  CPM,AHU
 SG_ ApedPosPcActl_D_Qf : 7|2@0+ (1,0) [0|0] "SED"  AHU
 SG_ EngAout_N_Actl : 28|13@0+ (2,0) [0|16382] "rpm" Vector__XXX
 SG_ ApedPosPcActl_No_Cs : 47|8@0+ (1,0) [0|255] "Unitless" Vector__XXX
 SG_ EngAout3_N_Actl : 55|16@0+ (0.25,0) [0|16383.5] "RPM" Vector__XXX
 SG_ ApedPosPcActl_No_Cnt : 5|4@0+ (1,0) [0|15] "Unitless" Vector__XXX

BO_ 687 CD_MC_WORD_Rx: 8 IPC
 SG_ CD_MC_WORD_Rx_ : 7|64@0+ (1,0) [0|1.84467440737096E+019] "unitless" Vector__XXX

BO_ 754 ACU_Send_Signals_14: 8 AHU
 SG_ ACU_ActChimeType_St : 23|3@0+ (1,0) [0|0] ""  IPC,DSP
 SG_ ACU_ActChimeTypeDat_St : 5|14@0+ (1,0) [0|16383] ""  IPC,DSP

BO_ 711 MyKeySrvr_MyKeyClient_Word_Tx: 8 IPC
 SG_ MyKeySrvr_MyKeyClient_Word_Tx : 7|64@0+ (1,0) [0|1.84467440737096E+019] "unitless" Vector__XXX

BO_ 391 ACU_Request_Signals_3: 8 AHU
 SG_ ACU_CtrlChimeChan_Rq : 7|2@0+ (1,0) [0|0] ""  DSP

BO_ 393 CPM_Audio_Response: 8 CPM
 SG_ CPM_Audio_Source_RSP : 6|2@0+ (1,0) [0|0] ""  MFD
 SG_ CPM_Audio_State_RSP : 7|1@0+ (1,0) [0|0] ""  MFD

BO_ 406 ACM_Audio_Source_Command: 8 MFD
 SG_ Audio_Source_Target_Cmd : 23|1@0+ (1,0) [0|0] ""  CPM
 SG_ Primary_Audio_Source_Target : 7|8@0+ (1,0) [0|0] ""  CPM

BO_ 409 CPM_Audio_Bus_Request: 8 CPM
 SG_ CPM_Audio_Source_REQ : 6|2@0+ (1,0) [0|0] ""  MFD
 SG_ Audio_Bus_Request_CPM : 7|1@0+ (1,0) [0|0] ""  MFD

BO_ 717 CPM_Display_Data: 8 CPM
 SG_ Display_Data_Stream_CPM : 7|64@0+ (1,0) [0|0] ""  MFD

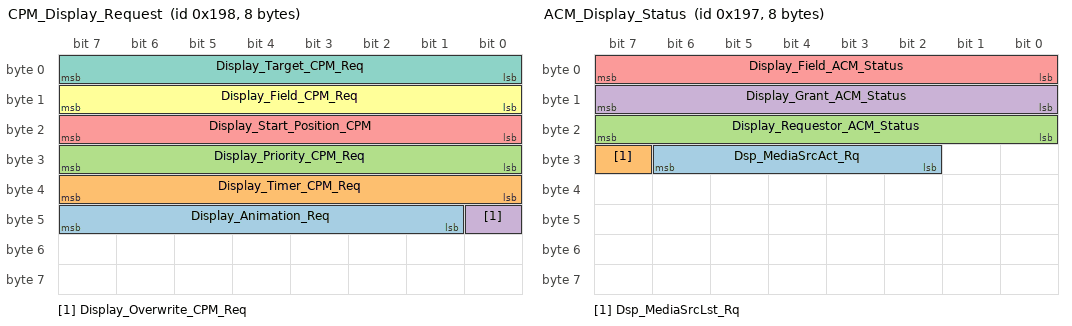
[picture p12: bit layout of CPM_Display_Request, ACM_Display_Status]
BO_ 408 CPM_Display_Request: 8 CPM
 SG_ Display_Animation_Req : 47|7@0+ (1,0) [0|0] ""  MFD
 SG_ Display_Timer_CPM_Req : 39|8@0+ (1,0) [0|255] ""  MFD
 SG_ Display_Priority_CPM_Req : 31|8@0+ (1,0) [0|255] ""  MFD
 SG_ Display_Overwrite_CPM_Req : 40|1@0+ (1,0) [0|0] ""  MFD
 SG_ Display_Start_Position_CPM : 23|8@0+ (1,0) [0|0] ""  MFD
 SG_ Display_Field_CPM_Req : 15|8@0+ (1,0) [0|255] ""  MFD
 SG_ Display_Target_CPM_Req : 7|8@0+ (1,0) [0|0] ""  MFD

BO_ 407 ACM_Display_Status: 8 MFD
 SG_ Dsp_MediaSrcAct_Rq : 30|5@0+ (1,0) [0|0] ""  CPM
 SG_ Dsp_MediaSrcLst_Rq : 31|1@0+ (1,0) [0|0] ""  CPM
 SG_ Display_Requestor_ACM_Status : 23|8@0+ (1,0) [0|0] ""  CPM
 SG_ Display_Grant_ACM_Status : 15|8@0+ (1,0) [0|0] ""  CPM
 SG_ Display_Field_ACM_Status : 7|8@0+ (1,0) [0|255] ""  CPM

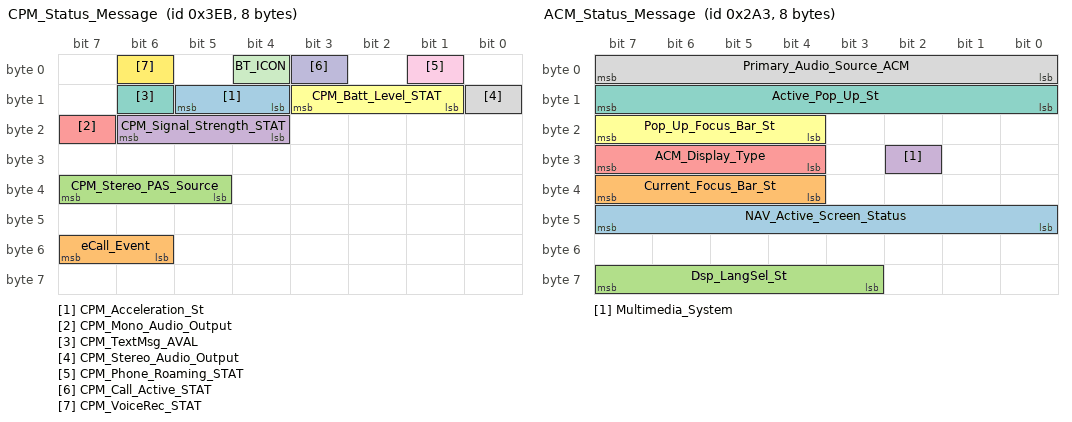
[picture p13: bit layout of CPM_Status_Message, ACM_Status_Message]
BO_ 1003 CPM_Status_Message: 8 CPM
 SG_ CPM_Acceleration_St : 13|2@0+ (1,0) [0|0] ""  MFD
 SG_ eCall_Event : 55|2@0+ (1,0) [0|0] ""  MFD,DSP,AHU
 SG_ CPM_Stereo_PAS_Source : 39|3@0+ (1,0) [0|0] ""  MFD
 SG_ CPM_Signal_Strength_STAT : 22|3@0+ (1,0) [0|0] ""  MFD
 SG_ CPM_Mono_Audio_Output : 23|1@0+ (1,0) [0|0] ""  MFD
 SG_ CPM_Batt_Level_STAT : 11|3@0+ (1,0) [0|0] ""  MFD
 SG_ CPM_TextMsg_AVAL : 14|1@0+ (1,0) [0|0] ""  MFD
 SG_ CPM_Stereo_Audio_Output : 8|1@0+ (1,0) [0|0] ""  MFD
 SG_ CPM_Phone_Roaming_STAT : 1|1@0+ (1,0) [0|0] ""  MFD
 SG_ CPM_Call_Active_STAT : 3|1@0+ (1,0) [0|0] ""  MFD
 SG_ BT_ICON : 4|1@0+ (1,0) [0|0] ""  MFD
 SG_ CPM_VoiceRec_STAT : 6|1@0+ (1,0) [0|0] ""  MFD

BO_ 675 ACM_Status_Message: 8 MFD
 SG_ NAV_Active_Screen_Status : 47|8@0+ (1,0) [0|0] ""  CPM
 SG_ Current_Focus_Bar_St : 39|4@0+ (1,0) [0|0] ""  CPM
 SG_ Dsp_LangSel_St : 63|5@0+ (1,0) [0|0] ""  CPM
 SG_ Multimedia_System : 26|1@0+ (1,0) [0|0] ""  CPM
 SG_ ACM_Display_Type : 31|4@0+ (1,0) [0|0] ""  CPM
 SG_ Pop_Up_Focus_Bar_St : 23|4@0+ (1,0) [0|0] ""  CPM
 SG_ Active_Pop_Up_St : 15|8@0+ (1,0) [0|0] ""  CPM
 SG_ Primary_Audio_Source_ACM : 7|8@0+ (1,0) [0|0] ""  CPM

BO_ 263 ACM_CPM_Command: 8 MFD
 SG_ PrsnlCnnctReset_D_Rq : 1|2@0+ (1,0) [0|0] ""  CPM
 SG_ ACM_CPM_VR_CMND : 3|2@0+ (1,0) [0|0] ""  CPM
 SG_ ACM_CPM_Stereo_Audio_CMND : 5|1@0+ (1,0) [0|0] ""  CPM
 SG_ ACM_CPM_Mono_Audio_CMND : 6|1@0+ (1,0) [0|0] ""  CPM

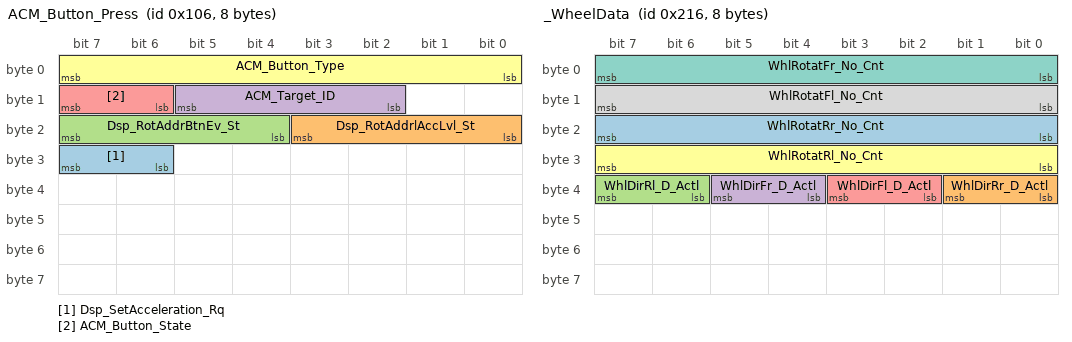
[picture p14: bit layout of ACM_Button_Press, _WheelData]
BO_ 262 ACM_Button_Press: 8 MFD
 SG_ Dsp_SetAcceleration_Rq : 31|2@0+ (1,0) [0|0] ""  CPM
 SG_ Dsp_RotAddrlAccLvl_St : 19|4@0+ (1,0) [0|0] ""  CPM
 SG_ Dsp_RotAddrBtnEv_St : 23|4@0+ (1,-7) [-7|8] ""  CPM
 SG_ ACM_Target_ID : 13|4@0+ (1,0) [0|0] ""  CPM
 SG_ ACM_Button_State : 15|2@0+ (1,0) [0|0] ""  CPM
 SG_ ACM_Button_Type : 7|8@0+ (1,0) [0|255] ""  CPM

BO_ 534 _WheelData: 8 IPC
 SG_ WhlRotatRr_No_Cnt : 23|8@0+ (1,0) [0|255] "" Vector__XXX
 SG_ WhlDirRr_D_Actl : 33|2@0+ (1,0) [0|0] "" Vector__XXX
 SG_ WhlDirRl_D_Actl : 39|2@0+ (1,0) [0|0] "" Vector__XXX
 SG_ WhlDirFr_D_Actl : 37|2@0+ (1,0) [0|0] "" Vector__XXX
 SG_ WhlDirFl_D_Actl : 35|2@0+ (1,0) [0|0] "" Vector__XXX
 SG_ WhlRotatRl_No_Cnt : 31|8@0+ (1,0) [0|255] "" Vector__XXX
 SG_ WhlRotatFr_No_Cnt : 7|8@0+ (1,0) [0|255] "" Vector__XXX
 SG_ WhlRotatFl_No_Cnt : 15|8@0+ (1,0) [0|255] "" Vector__XXX

BO_ 656 Ill_Send_Signals: 8 MFD
 SG_ HMI_DimmingLevelStatus : 13|5@0+ (1,0) [0|0] ""  IPC
 SG_ HMI_DimmingModeStatus : 15|2@0+ (1,0) [0|0] ""  IPC
 SG_ Ill_BEZZone_St : 7|8@0+ (1,0) [0|255] ""  IPC

BO_ 1008 APIM_Send_Signals: 8 CPM
 SG_ CPM_MediaPlayerSrc_St : 39|5@0+ (1,0) [0|0] ""  MFD
 SG_ APIM_TrackPlaytime_St : 23|16@0+ (1,-100) [-100|65434] "second"  MFD,IPC
 SG_ APIM_TotalPlayTime_St : 7|16@0+ (1,-100) [-100|65434] "second"  IPC

BO_ 404 Dsp_Response_Signals: 8 MFD
 SG_ Dsp_LangUpdate_Rsp : 7|2@0+ (1,0) [0|0] "unitless"  IPC

BO_ 291 HEC_Response_Signals: 8 IPC
 SG_ LangUpdate_Rsp : 7|2@0+ (1,0) [0|0] "unitless"  MFD

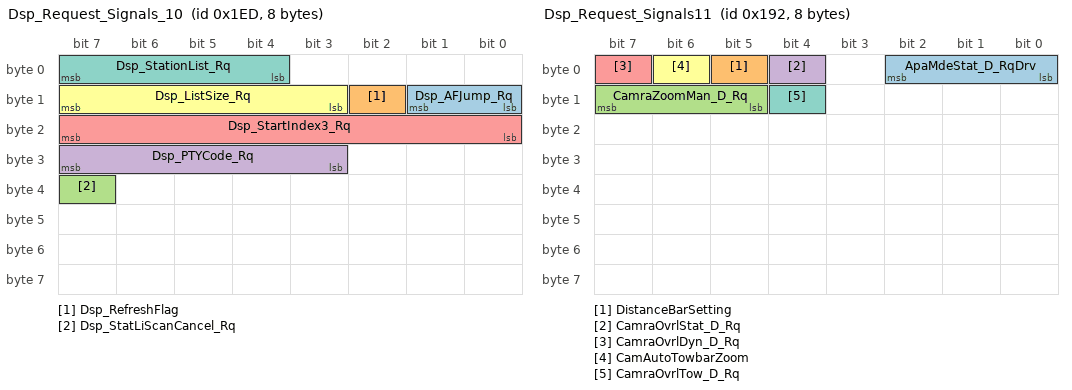
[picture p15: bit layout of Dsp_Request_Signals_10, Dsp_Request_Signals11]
BO_ 493 Dsp_Request_Signals_10: 8 MFD
 SG_ Dsp_AFJump_Rq : 9|2@0+ (1,0) [0|0] ""  AHU
 SG_ Dsp_RefreshFlag : 10|1@0+ (1,0) [0|0] ""  AHU
 SG_ Dsp_StatLiScanCancel_Rq : 39|1@0+ (1,0) [0|0] ""  AHU
 SG_ Dsp_PTYCode_Rq : 31|5@0+ (1,0) [0|31] ""  AHU
 SG_ Dsp_StartIndex3_Rq : 23|8@0+ (1,0) [0|255] ""  AHU
 SG_ Dsp_ListSize_Rq : 15|5@0+ (1,0) [0|31] ""  AHU
 SG_ Dsp_StationList_Rq : 7|4@0+ (1,0) [0|0] ""  AHU

BO_ 708 TMCSrvr_TMCClient_WORD_Tx: 8 AHU
 SG_ TMCSrvr_TMCClient_WORD_Tx : 7|64@0+ (1,0) [0|1.84467440737096E+019] "unitless"  MFD

BO_ 1959 TesterPhysicalReqFCIM: 8 IPC
 SG_ TesterPhysicalReqFCIM : 7|64@0+ (1,0) [0|1.84467440737096E+019] "unitless" Vector__XXX

BO_ 402 Dsp_Request_Signals11: 8 MFD
 SG_ ApaMdeStat_D_RqDrv : 2|3@0+ (1,0) [0|0] "SED"  IPC
 SG_ DistanceBarSetting : 5|1@0+ (1,0) [0|0] ""  IPC
 SG_ CamraZoomMan_D_Rq : 15|3@0+ (1,0) [0|0] ""  IPC
 SG_ CamraOvrlStat_D_Rq : 4|1@0+ (1,0) [0|0] ""  IPC
 SG_ CamraOvrlDyn_D_Rq : 7|1@0+ (1,0) [0|0] ""  IPC
 SG_ CamAutoTowbarZoom : 6|1@0+ (1,0) [0|0] ""  IPC
 SG_ CamraOvrlTow_D_Rq : 12|1@0+ (1,0) [0|0] ""  IPC

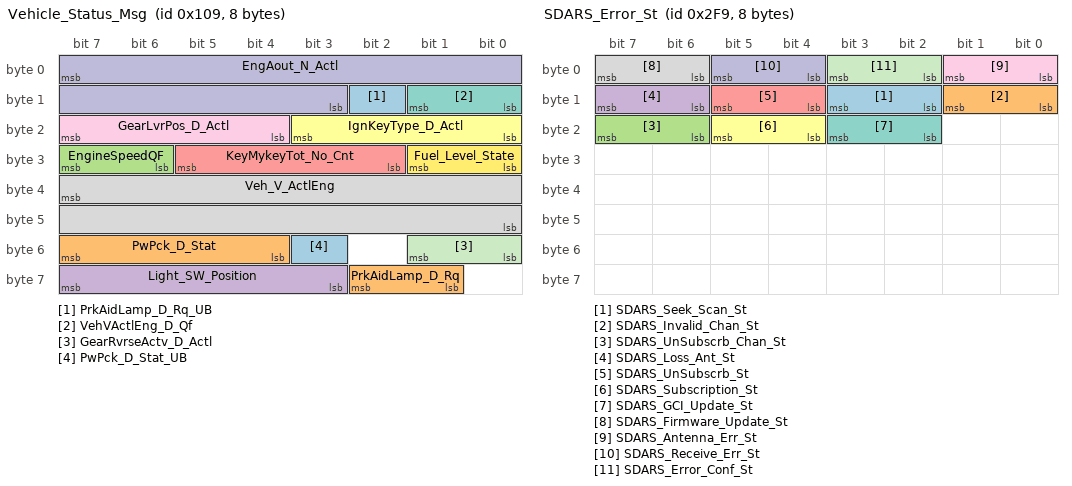
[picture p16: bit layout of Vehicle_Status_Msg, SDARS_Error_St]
BO_ 265 Vehicle_Status_Msg: 8 IPC
 SG_ PrkAidLamp_D_Rq_UB : 10|1@0+ (1,0) [0|1] "SED" Vector__XXX
 SG_ PrkAidLamp_D_Rq : 58|2@0+ (1,0) [0|3] "SED" Vector__XXX
 SG_ EngineSpeedQF : 31|2@0+ (1,0) [0|0] "SED"  AHU
 SG_ Light_SW_Position : 63|5@0+ (1,0) [0|0] ""  MFD
 SG_ KeyMykeyTot_No_Cnt : 29|4@0+ (1,0) [0|0] "Counts"  MFD,AHU
 SG_ IgnKeyType_D_Actl : 19|4@0+ (1,0) [0|0] "SED"  CPM,DSP,MFD,AHU
 SG_ VehVActlEng_D_Qf : 9|2@0+ (1,0) [0|0] "SED"  AHU,DSP,MFD,CPM
 SG_ Veh_V_ActlEng : 39|16@0+ (0.01,0) [0|655.35] "kilometers / hr"  CPM,AHU,MFD,DSP
 SG_ GearLvrPos_D_Actl : 23|4@0+ (1,0) [0|0] "SED"  AHU,MFD,CPM,DSP
 SG_ EngAout_N_Actl : 7|13@0+ (2,0) [0|16382] "rpm"  AHU,CPM,MFD,DSP
 SG_ GearRvrseActv_D_Actl : 49|2@0+ (1,0) [0|0] ""  MFD
 SG_ Fuel_Level_State : 25|2@0+ (1,0) [0|0] ""  CPM
 SG_ PwPck_D_Stat_UB : 51|1@0+ (1,0) [0|0] "" Vector__XXX
 SG_ PwPck_D_Stat : 55|4@0+ (1,0) [0|0] "" Vector__XXX

BO_ 709 DSPAMP_RDISP_WORD_Tx: 8 DSP
 SG_ DSPAMP_RDISP_WORD_Tx : 7|64@0+ (1,0) [0|1.84467440737096E+019] "unitless"  MFD

BO_ 706 SDARS_MC_WORD_Tx: 8 AHU
 SG_ SDARS_MC_WORD_Tx : 7|64@0+ (1,0) [0|1.84467440737096E+019] "unitless"  IPC

BO_ 713 SDARS_RDISP_WORD_Rx: 8 MFD
 SG_ SDARS_RDISP_WORD_Rx : 7|64@0+ (1,0) [0|1.84467440737096E+019] "unitless"  AHU

BO_ 705 SDARS_RDISP_WORD_Tx: 8 AHU
 SG_ SDARS_RDISP_WORD_Tx : 7|64@0+ (1,0) [0|1.84467440737096E+019] "unitless"  MFD

BO_ 707 SSPClnt_SSPSrv_WORD_Tx: 8 AHU
 SG_ SSPClnt_SSPSrv_WORD_Tx : 7|64@0+ (1,0) [0|1.84467440737096E+019] "unitless" Vector__XXX

BO_ 1923 TesterPhysicalReqDSP: 8 IPC
 SG_ TesterPhysicalReqDSP : 7|64@0+ (1,0) [0|1.84467440737096E+019] "unitless"  DSP

BO_ 758 SDARS_Status_Msg_1: 8 AHU
 SG_ SDARS_OpMode_St : 5|3@0+ (1,0) [0|0] "unitless"  MFD,IPC
 SG_ SDARS_SetCategory_St : 31|8@0+ (1,0) [0|255] "unitless"  MFD
 SG_ SDARS_GCI_Update_Prg_St : 23|8@0+ (1,0) [0|255] "unitless"  MFD
 SG_ SDARS_Factory_Reset_St : 7|2@0+ (1,0) [0|0] "unitless"  MFD

BO_ 761 SDARS_Error_St: 8 AHU
 SG_ SDARS_Seek_Scan_St : 11|2@0+ (1,0) [0|0] "unitless"  MFD,IPC
 SG_ SDARS_Invalid_Chan_St : 9|2@0+ (1,0) [0|0] "SED"  CPM,MFD,IPC
 SG_ SDARS_UnSubscrb_Chan_St : 23|2@0+ (1,0) [0|0] "SED"  CPM,MFD,IPC
 SG_ SDARS_Loss_Ant_St : 15|2@0+ (1,0) [0|0] "SED"  MFD,IPC
 SG_ SDARS_UnSubscrb_St : 13|2@0+ (1,0) [0|0] "SED"  CPM,MFD,IPC
 SG_ SDARS_Subscription_St : 21|2@0+ (1,0) [0|0] "SED"  CPM,MFD,IPC
 SG_ SDARS_GCI_Update_St : 19|2@0+ (1,0) [0|0] "SED"  CPM,MFD
 SG_ SDARS_Firmware_Update_St : 7|2@0+ (1,0) [0|0] "SED"  MFD
 SG_ SDARS_Antenna_Err_St : 1|2@0+ (1,0) [0|0] "SED"  MFD,IPC
 SG_ SDARS_Receive_Err_St : 5|2@0+ (1,0) [0|0] "SED"  MFD,IPC
 SG_ SDARS_Error_Conf_St : 3|2@0+ (1,0) [0|0] "unitless"  MFD,IPC

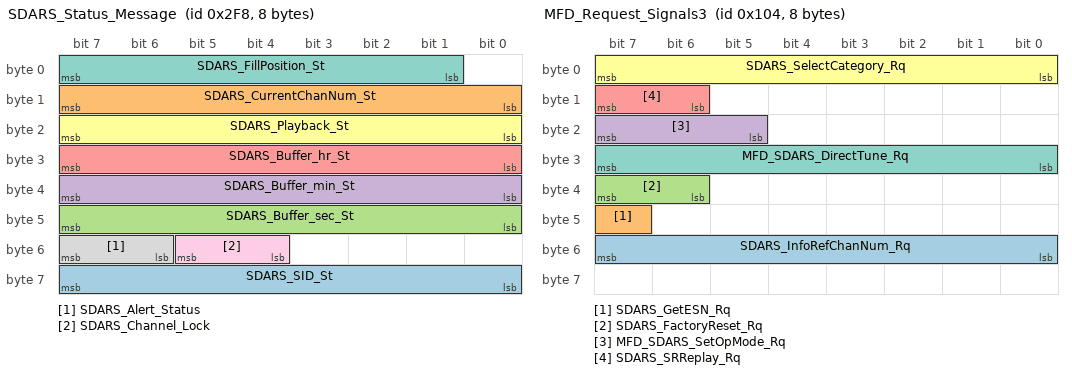
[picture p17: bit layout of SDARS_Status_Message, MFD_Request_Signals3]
BO_ 760 SDARS_Status_Message: 8 AHU
 SG_ SDARS_SID_St : 63|8@0+ (1,0) [0|0] ""  CPM
 SG_ SDARS_CurrentChanNum_St : 15|8@0+ (1,0) [0|255] "unitless"  CPM,MFD,IPC
 SG_ SDARS_Buffer_sec_St : 47|8@0+ (1,0) [0|255] "unitless"  MFD
 SG_ SDARS_Buffer_min_St : 39|8@0+ (1,0) [0|255] "unitless"  MFD
 SG_ SDARS_Buffer_hr_St : 31|8@0+ (1,0) [0|255] "unitless"  MFD
 SG_ SDARS_Playback_St : 23|8@0+ (1,0) [0|255] "unitless"  MFD
 SG_ SDARS_FillPosition_St : 7|7@0+ (1,0) [0|127] "unitless"  MFD
 SG_ SDARS_Alert_Status : 55|2@0+ (1,0) [0|0] "unitless"  MFD
 SG_ SDARS_Channel_Lock : 53|2@0+ (1,0) [0|0] "unitless"  CPM,MFD,IPC

BO_ 260 MFD_Request_Signals3: 8 MFD
 SG_ SDARS_InfoRefChanNum_Rq : 55|8@0+ (1,0) [0|0] ""  AHU
 SG_ SDARS_GetESN_Rq : 47|1@0+ (1,0) [0|0] ""  AHU
 SG_ SDARS_FactoryReset_Rq : 39|2@0+ (1,0) [0|0] ""  AHU
 SG_ MFD_SDARS_SetOpMode_Rq : 23|3@0+ (1,0) [0|0] ""  AHU
 SG_ SDARS_SRReplay_Rq : 15|2@0+ (1,0) [0|0] ""  AHU
 SG_ SDARS_SelectCategory_Rq : 7|8@0+ (1,0) [0|0] ""  AHU
 SG_ MFD_SDARS_DirectTune_Rq : 31|8@0+ (1,0) [0|0] ""  AHU

BO_ 259 MFD_Request_Signals2: 8 MFD
 SG_ SDARS_CurrCATlistSize_Rq : 15|8@0+ (1,0) [0|0] ""  AHU
 SG_ SDARS_CurrCATlistInd_Rq : 7|8@0+ (1,0) [0|0] ""  AHU
 SG_ SDARS_AlertStatus_Rq : 23|2@0+ (1,0) [0|0] ""  AHU

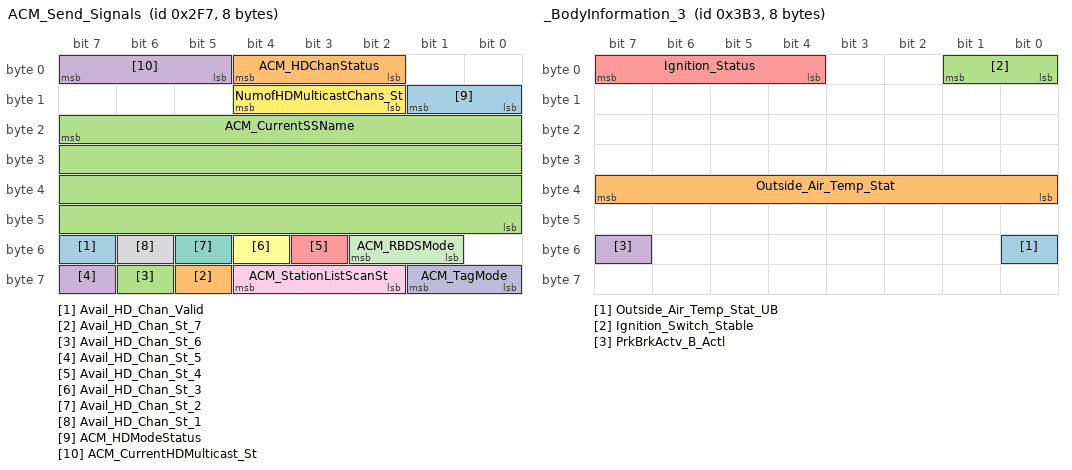
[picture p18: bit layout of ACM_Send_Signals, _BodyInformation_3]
BO_ 759 ACM_Send_Signals: 8 AHU
 SG_ Avail_HD_Chan_Valid : 55|1@0+ (1,0) [0|0] ""  MFD
 SG_ Avail_HD_Chan_St_7 : 61|1@0+ (1,0) [0|0] ""  MFD
 SG_ Avail_HD_Chan_St_6 : 62|1@0+ (1,0) [0|0] ""  MFD
 SG_ Avail_HD_Chan_St_5 : 63|1@0+ (1,0) [0|0] ""  MFD
 SG_ Avail_HD_Chan_St_4 : 51|1@0+ (1,0) [0|0] ""  MFD
 SG_ Avail_HD_Chan_St_3 : 52|1@0+ (1,0) [0|0] ""  MFD
 SG_ Avail_HD_Chan_St_2 : 53|1@0+ (1,0) [0|0] ""  MFD
 SG_ Avail_HD_Chan_St_1 : 54|1@0+ (1,0) [0|0] ""  MFD
 SG_ ACM_StationListScanSt : 60|3@0+ (1,0) [0|0] "unitless"  MFD
 SG_ ACM_TagMode : 57|2@0+ (1,0) [0|0] "unitless"  MFD
 SG_ ACM_RBDSMode : 50|2@0+ (1,0) [0|0] "unitless"  CPM,MFD
 SG_ NumofHDMulticastChans_St : 12|3@0+ (1,0) [0|0] "unitless"  CPM,MFD
 SG_ ACM_HDModeStatus : 9|2@0+ (1,0) [0|0] "unitless"  CPM,MFD
 SG_ ACM_HDChanStatus : 4|3@0+ (1,0) [0|0] "unitless"  CPM,MFD,IPC
 SG_ ACM_CurrentSSName : 23|32@0+ (1,0) [0|4294967295] "unitless"  MFD,IPC
 SG_ ACM_CurrentHDMulticast_St : 7|3@0+ (1,0) [0|0] "unitless"  CPM,MFD,IPC

BO_ 947 _BodyInformation_3: 8 IPC
 SG_ Outside_Air_Temp_Stat_UB : 48|1@0+ (1,0) [0|0] "SED"  CPM,MFD,DSP
 SG_ Outside_Air_Temp_Stat : 39|8@0+ (0.5,-40) [-40|86.5] "degC"  MFD,CPM,DSP
 SG_ Ignition_Switch_Stable : 1|2@0+ (1,0) [0|0] ""  MFD,CPM,AHU,DSP
 SG_ PrkBrkActv_B_Actl : 55|1@0+ (1,0) [0|0] "SED"  CPM
 SG_ Ignition_Status : 7|4@0+ (1,0) [0|0] "SED"  MFD,CPM,AHU,DSP

BO_ 129 _Steering_Wheel_Data2: 8 IPC
 SG_ SuspDampInc_B_RqDrv : 15|1@0+ (1,0) [0|1] "SED" Vector__XXX
 SG_ SteEffortInc_B_RqDrv : 5|1@0+ (1,0) [0|1] "SED" Vector__XXX
 SG_ SelDrvMdeInc_B_RqDrv : 6|1@0+ (1,0) [0|1] "SED" Vector__XXX
 SG_ SelDrvMdeDec_B_RqDrv : 7|1@0+ (1,0) [0|1] "SED" Vector__XXX
 SG_ SteWhlSwtchUp_B_Stat : 3|1@0+ (1,0) [0|1] "SED" Vector__XXX
 SG_ SteWhlSwtchRght_B_Stat : 2|1@0+ (1,0) [0|1] "SED" Vector__XXX
 SG_ SteWhlSwtchOk_B_Stat : 4|1@0+ (1,0) [0|1] "SED" Vector__XXX
 SG_ SteWhlSwtchLeft_B_Stat : 1|1@0+ (1,0) [0|1] "SED" Vector__XXX
 SG_ SteWhlSwtchDown_B_Stat : 0|1@0+ (1,0) [0|1] "SED" Vector__XXX
 SG_ SteWhlCtl_Phone_UB : 32|1@0+ (1,0) [0|0] ""  MFD
 SG_ SteWhlCtl_Phone : 28|1@0+ (1,0) [0|0] ""  MFD
 SG_ SteWhlCtl_Mute_UB : 27|1@0+ (1,0) [0|0] ""  MFD
 SG_ SteWhlCtl_Mute : 26|1@0+ (1,0) [0|0] ""  MFD
 SG_ SteWhlCtl_Volume_Up_UB : 31|1@0+ (1,0) [0|0] ""  AHU,DSP
 SG_ SteWhlCtl_Volume_Down_UB : 30|1@0+ (1,0) [0|0] ""  AHU,DSP
 SG_ SteWhlCtl_Voice_PTT_UB : 29|1@0+ (1,0) [0|0] ""  MFD
 SG_ SteWhlCtl_Seek_Right_UB : 23|1@0+ (1,0) [0|0] ""  MFD
 SG_ SteWhlCtl_Seek_Left_UB : 22|1@0+ (1,0) [0|0] ""  MFD
 SG_ SteWhlCtl_RSideCursLeft_UB : 21|1@0+ (1,0) [0|0] ""  MFD
 SG_ SteWhlCtl_RSideCursDown_UB : 20|1@0+ (1,0) [0|0] ""  MFD
 SG_ SteWhlCtl_RSide_OK_UB : 19|1@0+ (1,0) [0|0] ""  MFD
 SG_ SteWhlCtl_RSide_CursUp_UB : 18|1@0+ (1,0) [0|0] ""  MFD
 SG_ SteWhlCtl_RSide_CursRt_UB : 17|1@0+ (1,0) [0|0] ""  MFD
 SG_ SteWhlCtl_Mode_UB : 16|1@0+ (1,0) [0|0] ""  MFD
 SG_ SteWhlCtl_Volume_Up : 15|1@0+ (1,0) [0|0] ""  AHU,DSP
 SG_ SteWhlCtl_Volume_Down : 14|1@0+ (1,0) [0|0] ""  AHU,DSP
 SG_ SteWhlCtl_Voice_PTT : 13|1@0+ (1,0) [0|0] ""  MFD
 SG_ SteWhlCtl_Seek_Right : 12|1@0+ (1,0) [0|0] ""  MFD
 SG_ SteWhlCtl_Seek_Left : 11|1@0+ (1,0) [0|0] ""  MFD
 SG_ SteWhlCtl_Mode : 10|1@0+ (1,0) [0|0] ""  MFD
 SG_ SteWhlCtl_RSide_OK : 9|1@0+ (1,0) [0|0] ""  MFD
 SG_ SteWhlCtl_RSide_CursorUp : 8|1@0+ (1,0) [0|0] ""  MFD
 SG_ SteWhlCtl_RSide_CursorRt : 7|1@0+ (1,0) [0|0] ""  MFD
 SG_ SteWhlCtl_RSide_CursorLeft : 6|1@0+ (1,0) [0|0] ""  MFD
 SG_ SteWhlCtl_RSide_CursorDown : 5|1@0+ (1,0) [0|0] ""  MFD
 SG_ SteWhlCtl_Media_UB : 25|1@0+ (1,0) [0|0] ""  MFD
 SG_ SteWhlCtl_Media : 24|1@0+ (1,0) [0|0] ""  MFD

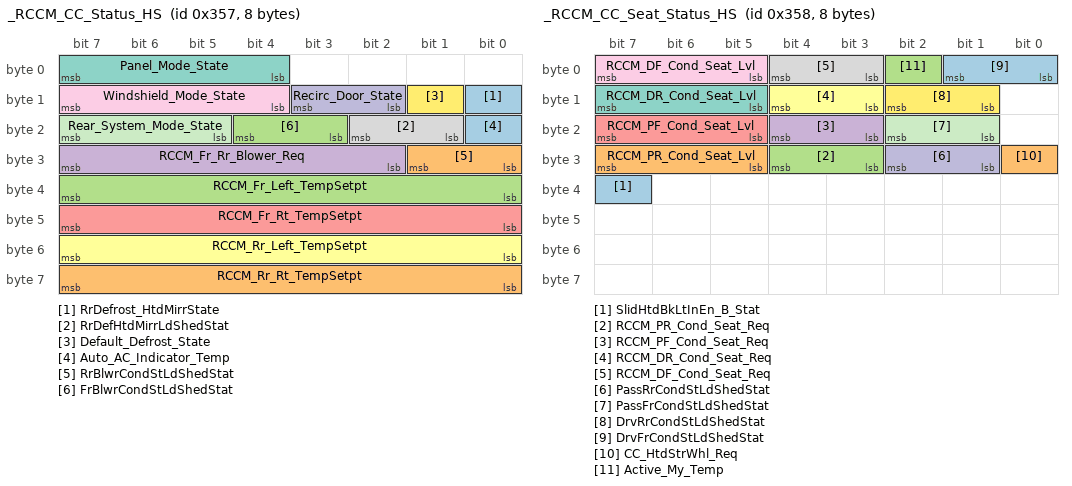
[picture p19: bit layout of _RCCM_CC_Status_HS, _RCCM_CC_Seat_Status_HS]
BO_ 855 _RCCM_CC_Status_HS: 8 IPC
 SG_ RrDefrost_HtdMirrState : 8|1@0+ (1,0) [0|0] "" Vector__XXX
 SG_ RCCM_Rr_Rt_TempSetpt : 63|8@0+ (1,0) [0|0] "Mixed" Vector__XXX
 SG_ RCCM_Fr_Left_TempSetpt : 39|8@0+ (1,0) [0|0] "Mixed" Vector__XXX
 SG_ RCCM_Fr_Rr_Blower_Req : 31|6@0+ (1,0) [0|63] "" Vector__XXX
 SG_ RCCM_Fr_Rt_TempSetpt : 47|8@0+ (1,0) [0|0] "Mixed" Vector__XXX
 SG_ RCCM_Rr_Left_TempSetpt : 55|8@0+ (1,0) [0|0] "Mixed" Vector__XXX
 SG_ Panel_Mode_State : 7|4@0+ (8.33,0) [0|100] "Percent" Vector__XXX
 SG_ RrDefHtdMirrLdShedStat : 18|2@0+ (1,0) [0|0] "" Vector__XXX
 SG_ Windshield_Mode_State : 15|4@0+ (8.33,0) [0|100] "Percent" Vector__XXX
 SG_ Recirc_Door_State : 11|2@0+ (1,0) [0|0] "" Vector__XXX
 SG_ Rear_System_Mode_State : 23|3@0+ (1,0) [0|0] "" Vector__XXX
 SG_ Default_Defrost_State : 9|1@0+ (1,0) [0|0] "SED" Vector__XXX
 SG_ Auto_AC_Indicator_Temp : 16|1@0+ (1,0) [0|0] "" Vector__XXX
 SG_ RrBlwrCondStLdShedStat : 25|2@0+ (1,0) [0|0] "" Vector__XXX
 SG_ FrBlwrCondStLdShedStat : 20|2@0+ (1,0) [0|0] "" Vector__XXX

BO_ 856 _RCCM_CC_Seat_Status_HS: 8 IPC
 SG_ SlidHtdBkLtInEn_B_Stat : 39|1@0+ (1,0) [0|0] "SED" Vector__XXX
 SG_ RCCM_PR_Cond_Seat_Lvl : 31|3@0+ (1,0) [0|0] "" Vector__XXX
 SG_ RCCM_PR_Cond_Seat_Req : 28|2@0+ (1,0) [0|0] "" Vector__XXX
 SG_ RCCM_PF_Cond_Seat_Req : 20|2@0+ (1,0) [0|0] "" Vector__XXX
 SG_ RCCM_PF_Cond_Seat_Lvl : 23|3@0+ (1,0) [0|0] "" Vector__XXX
 SG_ RCCM_DR_Cond_Seat_Req : 12|2@0+ (1,0) [0|0] "" Vector__XXX
 SG_ RCCM_DR_Cond_Seat_Lvl : 15|3@0+ (1,0) [0|0] "" Vector__XXX
 SG_ RCCM_DF_Cond_Seat_Req : 4|2@0+ (1,0) [0|0] "" Vector__XXX
 SG_ RCCM_DF_Cond_Seat_Lvl : 7|3@0+ (1,0) [0|0] "" Vector__XXX
 SG_ PassRrCondStLdShedStat : 26|2@0+ (1,0) [0|0] "" Vector__XXX
 SG_ PassFrCondStLdShedStat : 18|2@0+ (1,0) [0|0] "" Vector__XXX
 SG_ DrvRrCondStLdShedStat : 10|2@0+ (1,0) [0|0] "" Vector__XXX
 SG_ DrvFrCondStLdShedStat : 1|2@0+ (1,0) [0|0] "" Vector__XXX
 SG_ CC_HtdStrWhl_Req : 24|1@0+ (1,0) [0|0] "" Vector__XXX
 SG_ Active_My_Temp : 2|1@0+ (1,0) [0|0] "" Vector__XXX

CM_ "Node specific file; utilized by MFD4 [Yukawa Blue] w/ Asr";
CM_ BU_ CPM "Internal acronym for Sync Level 1";
CM_ BU_ AHU "Legacy acronym";
CM_ BU_ MFD "Legacy acronym";
CM_ BU_ IPC "GMRDB acronym";
CM_ BU_ DSP "GMRDB acronym";
CM_ SG_ 597 AUDIO_RSE_WORD_Tx "MM ISO 15765-2 Message Catalogue AUDIO - RSE";
CM_ SG_ 576 AUDIO_RDISP2_WORD_Tx "MM ISO 15765-2 Message Catalogue AUDIO - RDISP2";
CM_ SG_ 561 Vr_SetCurrTUPreset_Rq "Object Tuner.GetTUPresetInfo.SetCurrentTUPreset
Object DAB.GetTUPresetInfo.SetCurrentTUPreset
Object SDARS.GetTUPresetInfo.SetCurrentTUPreset

$1-$1E: Preset 1 to 30";
CM_ SG_ 561 Vr_SetCurrTUBand_Rq "Object Tuner.SetCurrTUBand
Object DAB.SetCurrTUBand
Object SDARS.SetCurrTUBand
";
CM_ SG_ 561 Vr_SetCurrStatMCCh_Rq "Object Tuner.SetCurrentStation.MCChannel";
CM_ SG_ 561 Vr_SetCurrentStatFreq_Rq "Object Tuner.SetCurrentStat.Request.Frequency

AM: Freq = 153+ Offset kHz.
Offset 0..1557

FM: Freq = 76+ Offset*0.05 MHz. Offset 0..640
Selected tuned band determine frequency (kHz or MHz).";
CM_ SG_ 561 Vr_SetCurrentStatOp_Rq "Object Tuner.SetCurrentStat.Request.Operation";
CM_ SG_ 561 Vr_SetCurrentPICode_Rq "Object Tuner.SetCurrentStat.Request.PI Code

16 bit hex coded PI Code

";
CM_ SG_ 561 Vr_SDARS_DirectTune_Rq "Object Tuner.SDARS Tuner.DirectTune
$0: Channel_0
$1: Channel_1
$2: Channel_2
$FE: Channel_254
$FF: Inactive";
CM_ SG_ 560 Vr_SourceSetTrack_Rq "Object Media Player BTAudio.SetTrack
Object Media Player USB.SetTrack
Object Single CD.SetTrack.AudioSource
";
CM_ SG_ 560 Vr_FolderNumber_Rq "Object Media Player BTAudio.GetFolderName.FolderNumber
Object Media Player USB.GetFolderName.FolderNumber
Object Single CD.GetFolderName.FolderNumber";
CM_ SG_ 560 Vr_AudioSourceSel_Rq "Object Media Player 
{ BTAudio.GetFolderName, 
SDCard.GetFolderName,
USB.GetFolderName,
BTAudio.SetTrack,
SD Card.SetTrack}.AudioSource
USB.SetTrack.AudioSource
Object Single CD.GetFolderName.AudioSource
Object Single CD.SetTrack.AudioSource";
CM_ SG_ 560 Vr_SkipTrack_Rq "Object Rear CD Changer.SkipTrack
Object Indash CD Changer.SkipTrack
Object Single CD.SkipTrack
Object.SDARSClient.SkipTrack";
CM_ SG_ 560 Vr_SetOperationMode_Rq "Object Rear CD Changer.SetOperationMode
Object Indash CD Changer.SetOperationMode
Object Single CD.SetOperationMode";
CM_ SG_ 560 Vr_CDSetShuffle_Rq "Object Single CD.SetShuffle";
CM_ SG_ 560 Vr_CDSetRepeat_Rq "Object Single CD.SetRepeat";
CM_ SG_ 557 Con_MediaSrc16_St "Object AtlanticWizard.AudioManagement.MediaSourceStatus_St";
CM_ SG_ 557 Con_MediaSrc15_St "Object AtlanticWizard.AudioManagement.MediaSourceStatus_St";
CM_ SG_ 557 Con_MediaSrc14_St "Object AtlanticWizard.AudioManagement.MediaSourceStatus_St";
CM_ SG_ 557 Con_MediaSrc13_St "Object AtlanticWizard.AudioManagement.MediaSourceStatus_St";
CM_ SG_ 557 Con_MediaSrc12_St "Object AtlanticWizard.AudioManagement.MediaSourceStatus_St";
CM_ SG_ 557 Con_MediaSrc11_St "Object AtlanticWizard.AudioManagement.MediaSourceStatus_St";
CM_ SG_ 557 Con_MediaSrc10_St "Object AtlanticWizard.AudioManagement.MediaSourceStatus_St";
CM_ SG_ 557 Con_MediaSrc9_St "Object AtlanticWizard.AudioManagement.MediaSourceStatus_St";
CM_ SG_ 557 Con_MediaSrc8_St "Object AtlanticWizard.AudioManagement.MediaSourceStatus_St";
CM_ SG_ 557 Con_MediaSrc7_St "Object AtlanticWizard.AudioManagement.MediaSourceStatus_St";
CM_ SG_ 557 Con_MediaSrc6_St "Object AtlanticWizard.AudioManagement.MediaSourceStatus_St";
CM_ SG_ 557 Con_MediaSrc5_St "Object AtlanticWizard.AudioManagement.MediaSourceStatus_St";
CM_ SG_ 557 Con_MediaSrc4_St "Object AtlanticWizard.AudioManagement.MediaSourceStatus_St";
CM_ SG_ 557 Con_MediaSrc3_St "Object AtlanticWizard.AudioManagement.MediaSourceStatus_St";
CM_ SG_ 557 Con_MediaSrc2_St "Object AtlanticWizard.AudioManagement.MediaSourceStatus_St";
CM_ SG_ 557 Con_MediaSrc1_St "Object AtlanticWizard.AudioManagement.MediaSourceStatus_St";
CM_ SG_ 1234 AHU_FMRangeUprBdr_St "Object Configuration Management.ACU_Configuration.FMFrequencyBand.FMFrequencyRangeUpperBorder.St";
CM_ SG_ 1234 AHU_FMRangeLwrBdr_St "Object Configuration Management.ACU_Configuration.FMFrequencyBand.FMFrequencyRangeLowerBorder.St";
CM_ SG_ 1234 AHU_LWRangeUprBdr_St "Object Configuration Management.ACU_Configuration.LWFrequencyBand.LWFrequencyRangeUpperBorder.St";
CM_ SG_ 1234 AHU_LWRangeLwrBdr_St "Object Configuration Management.ACU_Configuration.LWFrequencyBand.LWFrequencyRangeLowerBorder.St";
CM_ SG_ 1234 AHU_AMRangeUprBdr_St "Object Configuration Management.ACU_Configuration.AMFrequencyBand.AMFrequencyRangeUpperBorder.St";
CM_ SG_ 1234 AHU_AMRangeLwrBdr_St "Object Configuration Management.ACU_Configuration.AMFrequencyBand.AMFrequencyRangeLowerBorder.St";
CM_ SG_ 1234 AHU_AMSteps_St "Object Configuration Management.ACU_Configuration.AMFrequencyBand.AMFrequencyStepWidth.St

Object Configuration Management.ACU_Configuration.LWFrequencyBand.LWFrequencyStepWidth.St";
CM_ SG_ 1234 AHU_LWRadioSup_St "Object Configuration Management.ACU_Configuration.LWFrequencyBand.LWFrequencyBandSupported.St";
CM_ SG_ 1234 AHU_AMRadioSup_St "Object Configuration Management.ACU_Configuration.AMFrequencyBand.AMFrequencyBandSupported.St";
CM_ SG_ 1234 AHU_FMRadioSup_St "Object Configuration Management.ACU_Configuration.FMFrequencyBand.FMFrequencyBandSupported.St";
CM_ SG_ 1234 AHU_FMSteps_St "Object Configuration Management.ACU_Configuration.FMFrequencyBand.FMFrequencyStepWidth.St";
CM_ SG_ 803 CNG_LowFuel_792 "Object.BodyInformation.MessageCenter.CNGPopUpMsg.LowCNGStatus";
CM_ SG_ 803 CNG_Malfunction_793 "Object.BodyInformation.MessageCenter.CNGPopUpMsg.CNGMalfunctionStatus";
CM_ SG_ 803 CNG_CNGMode_794 "Object.BodyInformation.MessageCenter.CNGPopUpMsg.CNGModeStatus";
CM_ SG_ 803 CNG_GasMode_795 "Object.BodyInformation.MessageCenter.CNGPopUpMsg.GasModeStatus";
CM_ SG_ 803 LowOilLevel_254 "Object.BodyInformation.MessageCenter.LowOilLevelPoUpMsg_St";
CM_ SG_ 697 AUDIO_MC_WORD_Rx "MM ISO 15765-2 Message Catalogue
Section MC - Audio";
CM_ SG_ 995 LightAmbIntsty_No_Actl "Object.VehicleSettings.LightAmbIntsty_No_Actl";
CM_ SG_ 995 LightAmbColor_No_Actl "Object.VehicleSettings.LightAmbColor_No_Actl";
CM_ SG_ 906 Running_Board_Stat "Update msg. $115 to Event @ INIT in CMDB v4.06, 5/27/05.";
CM_ SG_ 906 Memory_Feedback_Rqst "Updated to 1 bit for CGEA, Not backwards compatible";
CM_ SG_ 906 GearLvrPos_D_Actl "Object:BezelDiagnostics. PRNDL.St

Sync Gen2 only";
CM_ BO_ 1242 "This message is a Module Configuration message issued by the dimming Master in the BCM every 1sec. It defines the presence of an ambient light sensor for cockpit illumination and the available dimming HMI.";
CM_ SG_ 538 MK_AudioLimitConfig_St "Object MyKey.AudioLimitConfig_St";
CM_ SG_ 538 MK_AdminMyKeyCount_St "Object MyKey.SystemKeyCount_St
[Parameter2]";
CM_ SG_ 538 MK_UserMyKeyCount_St "Object MyKey.SystemKeyCount_St
[Parameter1]";
CM_ SG_ 538 MK_SpeedMinderConf_St "Object MyKey.SpeedMinderConfig_St";
CM_ SG_ 538 MK_SpeedLimitConf_St "Object MyKey.SpeedLimitConfig_St";
CM_ SG_ 538 MK_ESCRestrictConf_St "Object MyKey.ESCRestrictionConfig_St";
CM_ SG_ 538 MK_ECalRestrictConf_St "Object MyKey.ECallRestrictionConfig_St";
CM_ SG_ 538 MK_DNDRestrictConf_St "Object MyKey.DNDRestrictionConfig_St";
CM_ SG_ 538 MK_ACSRestrictConf_St "Object MyKey.ACSRestrictionConfig_St";
CM_ SG_ 422 MK_MyKeyDrivenKm_Rsp "Object MyKey.MyKeySystemInfo_Rsp.MyKeyDrivenKm [Parameter4]";
CM_ SG_ 422 MK_AdminMyKeyCount_Rsp "Object MyKey.MyKeySystemInfo_Rsp.AdminMyKeyCount [Parameter2]";
CM_ SG_ 422 MK_UserMyKeyCount_Rsp "Object MyKey.MyKeySystemInfo_Rsp.UserMyKeyCount [Parameter1]";
CM_ SG_ 422 MK_CreateMyKey_Rsp "Object MyKey.CreateMyKey_Rsp";
CM_ SG_ 419 MK_SpeedValue_Rq "Object MyKey.1 SpeedSettingConfig_Rq.SpeedValue (Parameter2)";
CM_ SG_ 419 MK_SpeedSetting_Rq "Object MyKey.1 SpeedSettingConfig_Rq.SpeedSetting (Parameter1)";
CM_ SG_ 419 MK_ResetAllUserKeys_Rq "Object MyKey.ResetAllKeys_Rq";
CM_ SG_ 419 MK_MyKeySystemInfo_Rq "Object MyKey.MyKeySystemInfo_Rq";
CM_ SG_ 419 MK_ESCRestrictConf_Rq "Object MyKey.ESCRestrictionConfig_Rq";
CM_ SG_ 419 MK_ECalRestrictConf_Rq "Object MyKey.ECallRestrictionConfig_Rq";
CM_ SG_ 419 MK_DNDRestrictConf_Rq "Object MyKey.DNDRestrictionConfig_Rq";
CM_ SG_ 419 MK_CreateMyKey_Rq "Object MyKey.CreateMyKey_Rq";
CM_ SG_ 419 MK_AudioLimitConfig_Rq "Object MyKey.AudioLimitConfig_Rq";
CM_ SG_ 419 MK_ACSRestrictConf_Rq "Object MyKey.ACSRestrictionConfig_Rq";
CM_ SG_ 410 AugustReport_St "Object.ReportAvailability";
CM_ SG_ 410 AprilReport_St "Object.ReportAvailability";
CM_ SG_ 410 SeptemberReport_St "Object.ReportAvailability";
CM_ SG_ 410 ReportCardOnOff_St "Object.ReportCardStatus
";
CM_ SG_ 410 OctoberReport_St "Object.ReportAvailability";
CM_ SG_ 410 NovemberReport_St "Object.ReportAvailability";
CM_ SG_ 410 MayReport_St "Object.ReportAvailability";
CM_ SG_ 410 MarchReport_St "Object.ReportAvailability";
CM_ SG_ 410 JuneReport_St "Object.ReportAvailability";
CM_ SG_ 410 JulyReport_St "Object.ReportAvailability";
CM_ SG_ 410 JanuaryReport_St "Object.ReportAvailability";
CM_ SG_ 410 FebruaryReport_St "Object.ReportAvailability";
CM_ SG_ 410 DecemberReport_St "Object.ReportAvailability";
CM_ SG_ 410 ClusterMajorUnits_St "Object.Units
";
CM_ SG_ 410 MyKey_e911Override_St "Object MyKey.MyKey_e911Override_St";
CM_ SG_ 410 DoNotDisturbOveride_St "Object MyKey.DoNotDisturbOverride_St 
";
CM_ SG_ 417 SetAlarmAskOnExitSetting_Rq "Object.BodyInformation.VehicleSettings.SetAlarmAskOnExitSetting_Rq";
CM_ SG_ 417 SetAlarmMode_Rq "Object.BodyInformation.VehicleSettings.SetAlarmMode_Rq";
CM_ SG_ 417 VS_SetLaneChangeInd_Rq "Object.BodyInterface.VehicleSettings.SetLaneChangeIndicatorMode_Rq";
CM_ SG_ 417 VS_SetPowFolMirMode_Rq "Object.BodyInterface.VehicleSettings.SetPowerFoldMirrorMode_Rq";
CM_ SG_ 417 VS_SetMoodLight_Rq "Object.BodyInterface.VehicleSettings.SetMoodLightMode_Rq";
CM_ SG_ 417 VS_DeflDetSysInit_Rq "Object.BodyInterface.VehicleSettings.DDSSysInit_Rq";
CM_ SG_ 417 VS_SetESPMode_Rq "Object.BodyInterface.VehicleSettings.SetESPMode_Rq";
CM_ SG_ 417 VS_HSAMde_D_Rq "Object.BodyInterface.VehicleSettings.HSAOperationMode_Rq";
CM_ SG_ 417 VS_LowSpeedCMbB_Rq "Object.BodyInterface.VehicleSettings.SetLSSSMode_Rq";
CM_ SG_ 417 PrkLckCtlEnbl_D_Rq "Object.BodyInformation.VehicleSettings.ParkLockControlEnable_Rq";
CM_ SG_ 417 SetRainSensorMode_Rq "Object.BodyInformation.VehicleSettings.SetRainSensorMode_Rq";
CM_ SG_ 417 TirePReset_B_Rq "Object.BodyInformation.VehicleSettings.TPMSReset_Rq";
CM_ SG_ 793 EngineOn_98 "Object.MBodyInformation.MessageCenter.EngineOnPopUpMsg_St";
CM_ SG_ 793 Soot_DPFSootLevel2_578 "Object.BodyInformation.MessageCenter.SootOverloadPopupMsg_St.DPFSootLevel2Status";
CM_ SG_ 793 Soot_DPFRegen_537 "Object.BodyInformation.MessageCenter.SootOverloadPopupMsg_St.DPFSootRegeneration2Status";
CM_ SG_ 793 Soot_DPFRegen_536 "Object.BodyInformation.MessageCenter.SootOverloadPopupMsg_St.DPFSootRegeneration1Status";
CM_ SG_ 793 TopSpeedInfo_666 "Object MyKey.MyKeyInformation_St.NearTopSpeedInfo ";
CM_ SG_ 793 Headlamp_Failure_430 "Object.BodyInformation.MessageCenter.HeadlampPopupMsg_St";
CM_ SG_ 793 ParkBrake_Hard_626 "Object.BodyInforation.MessageCenter.ParkBrakePopupMsg_St.ParkBrake_AppliedHard";
CM_ SG_ 793 ParkBrake_Soft_625 "Object.BodyInforation.MessageCenter.ParkBrakePopupMsg_St.ParkBrake_AppliedSoft";
CM_ SG_ 793 TPMS_NotTraiRepeat_969 "Object.BodyInformation.MessageCenter.TPMS_NotTrainedRepeat";
CM_ SG_ 793 TPMS_TrainingCompl_968 "Object.BodyInformation.MessageCenter.TPMS_TrainingComplete";
CM_ SG_ 793 TPMS_TraiInLeRear_967 "Object.BodyInformation.MessageCenter.TPMS_TrainInLeftRear";
CM_ SG_ 793 TPMS_TraiOutLeRear_966 "Object.BodyInformation.MessageCenter.TPMS_TrainOutLeftRear";
CM_ SG_ 793 TPMS_TrainLeftRear_965 "Object.BodyInformation.MessageCenter.TPMS_TrainLeftRear";
CM_ SG_ 793 TPMS_TraiInRiRear_964 "Object.BodyInformation.MessageCenter.TPMS_TrainInRightRear";
CM_ SG_ 793 TPMS_TraiOutRiRear_963 "Object.BodyInformation.MessageCenter.TPMS_TrainOutRightRear";
CM_ SG_ 793 TPMS_TraiRiRear_962 "Object.BodyInformation.MessageCenter.TPMS_TrainRightRear";
CM_ SG_ 793 TPMS_TraiRiFront_961 "Object.BodyInformation.MessageCenter.TPMS_TrainRightFront";
CM_ SG_ 793 TPMS_TraiLeftFront_960 "Object.BodyInformation.MessageCenter.TPMS_TrainLeftFront";
CM_ SG_ 793 TPMS_GlobalWarning_493 "Object.BodyInformation.MessageCenter.TPMS_GlobalWarning";
CM_ SG_ 793 TPMS_NoSensors_474 "Object.BodyInformation.MessageCenter.TPMS_NoSensors";
CM_ SG_ 793 TPMS_Malfunction_400 "Object.BodyInformation.MessageCenter.TPMS_Malfunction";
CM_ SG_ 793 PAHWSwitchOffIn_671 "Object MyKey.MyKeyInformation_St.ParkAidHWSwitchOffInfo ";
CM_ SG_ 793 ESCHWSwitchOffIn_676 "Object MyKey.MyKeyInformation_St.EscHWSwitchOffInfo";
CM_ SG_ 793 SpeedMinder_665 "Object MyKey.MyKeyInformation_St.SpeedMinder ";
CM_ SG_ 793 MyKeyActive_660 "MyKey.MyKeyInformation_St.MyKeyActive";
CM_ SG_ 793 SpeedLimitIndic_661 "Object MyKey.MyKeyInformation_St.SpeedLimitIndication ";
CM_ SG_ 793 SpeedLimitInfo_667 "Object MyKey.MyKeyInformation_St.SpeedLimitInfo ";
CM_ SG_ 793 Point_Highspeed "Object.BodyInformation.MessageCenter.EcoMode";
CM_ SG_ 793 Point_Gearshift "Object.BodyInformation.MessageCenter.EcoMode";
CM_ SG_ 793 Point_Anticip "Object.BodyInformation.MessageCenter.EcoMode";
CM_ SG_ 793 I_highspeed "Object.BodyInformation.MessageCenter.EcoMode";
CM_ SG_ 793 I_gearshift "Object.BodyInformation.MessageCenter.EcoMode";
CM_ SG_ 793 I_anticip "Object.BodyInformation.MessageCenter.EcoMode";
CM_ SG_ 793 Pcnt_EngineColdTrips "Object.BodyInformation.MessageCenter.EcoMode";
CM_ SG_ 793 OTIS_PressBAndC_657 "Object.BodyInformation.MessageCenter.OTISPopupMsg.OTIS_BrakeAndClutch";
CM_ SG_ 793 OTIS_PressBrake_655 "Object.BodyInformation.MessageCenter.OTISPopupMsg.OTIS_PressBrake";
CM_ SG_ 793 OTIS_PressClutch_656 "Object.BodyInformation.MessageCenter.OTISPopupMsg.OTIS_PressClutch";
CM_ SG_ 793 LSSS_PostIncident_710 "Object.BodyInformation.Message Center.LSSSPopupMsg.LSSS_PostIncident.parameter3";
CM_ SG_ 793 LSSS_Malfunction_712 "Object.BodyInformation.Message Center.LSSSPopupMsg.LSSS_Unavailable.parameter2";
CM_ SG_ 793 LSSS_CleanSensor_711 "Object.BodyInformation.Message Center.LSSSPopupMsg_St.LSSS_CleanSensor.parameter1";
CM_ SG_ 793 DDS_PressureWarning_512 "Object.BodyInformation.Message Center.DDSPopupMsg.DDS_TyrePressure.parameter2";
CM_ SG_ 793 DDS_Unavailable_513 "Object.BodyInformation.Message Center.DDSPopupMsg.DDS_SysFail.parameter1";
CM_ SG_ 793 BTSI_MORShiftNotIP_752 "Object.BodyInformation.MessageCenter.ParkLockControlPopupMsg_St.ShifterNotInP";
CM_ SG_ 793 BTSI_MORShiftUnloc_751 "Object.BodyInformation.MessageCenter.ParkLockControlPopupMsg_St.ShifterUnlocked";
CM_ SG_ 793 BTSI_MORPreBraToUn_750 "Object.BodyInformation.MessageCenter.ParkLockControlPopupMsg_St.PressBrakeToUnlock";
CM_ SG_ 793 OTIS_StartOvrheat_658 "Object.BodyInformation.MessageCenter.OTISPopupMsg.OTIS_StarterOverheated";
CM_ SG_ 793 ECSS_StartPdgWait_790 "Object.BodyInformation.MessageCenter.EngineColdStartPopUpMsg_St.StartPendingWaitStatus";
CM_ SG_ 793 ECSS_PendingStart_791 "Object.BodyInformation.MessageCenter.EngineColdStartPopUpMsg_St.PendingStartStatus";
CM_ SG_ 753 AlarmPopUp_St "Object.BodyInformation.VehicleSettings.AlarmPopUp_St";
CM_ SG_ 753 AlarmMode_St "Object.BodyInformation.VehicleSettings.AlarmMode_St";
CM_ SG_ 753 AlarmAskOnExitSetting_St "Object.BodyInformation.VehicleSettings.AlarmAskOnExitSetting_St";
CM_ SG_ 753 VS_WiperStalkRotat_St "Object.BodyInformation.VehicleSettings.WiperStalkRotator_St";
CM_ SG_ 753 VS_WiperStalkPos_St "Object.BodyInformation.VehicleSettings.WiperStalkPosition_St";
CM_ SG_ 753 VS_RainSensorMode_St "Object.BodyInformation.VehicleSettings.RainSensorMode_St";
CM_ SG_ 753 VS_LaneChangIndMode_St "Object.BodyInformation.VehicleSettings.LaneChangeIndicatorMode_St";
CM_ SG_ 753 VS_HSAMde_D_Mem_St "Object.BodyInformation.VehicleSettings.HSAFunction_St";
CM_ SG_ 753 VS_PowFolMirMode_St "Object.BodyInformation.VehicleSettings.PowerFoldMirrorMode_St";
CM_ SG_ 753 VS_LscmbbOnOff_D_St "Object.BodyInformation.VehicleSettings.LSSSMode_St";
CM_ SG_ 753 VS_MoodLightMode_St "Object.BodyInformation.VehicleSettings.MoodLightMode_St";
CM_ SG_ 753 VS_StabilityControl_St "Object.BodyInformation.VehicleSettings.ESPMode_St";
CM_ SG_ 753 StopStartMsg_OnDemand_St "Object.BodyInformation.VehicleSettings.StopStartInfoMsg_St";
CM_ SG_ 753 DeflDetSysStatus "For vehicles with DDS only. Always set to $0 for other vehicles.

Object.BodyInformation.VehicleSettings.DDSSysMode_St";
CM_ SG_ 753 VS_ESPLongPress_St "Object.BodyInformation.VehicleSettings.ESP_Longpress_St";
CM_ SG_ 753 PrkLckCtl_B_Enbl_St "Object.BodyInformation.VehicleSettings.ParkLockControlEnable_St";
CM_ SG_ 753 PrkLckCtl_B_Allow_St "Object.BodyInformation.VehicleSettings.ParkLockControlAllow_St";
CM_ SG_ 753 TirePReset_D_Stat "Object.BodyInformation.VehicleSettings.TPMSReset_St";
CM_ SG_ 752 HillStartAssistOffWOChime_428 "Sub-system: Hill Start Assist";
CM_ SG_ 752 HillStartAssistOffWChime_582 "Sub-system: Hill Start Assist";
CM_ SG_ 752 HillStartAssistNotAvailable_429 "Sub-system: Hill Start Assist";
CM_ SG_ 752 HillStartAssistActive_427 "Sub-system: Hill Start Assist";
CM_ SG_ 752 PJB_TriggCause_419 "Inform MFD of alarm events.";
CM_ SG_ 752 PassengerDoorStatus2_214 "Sub-system: Locking / Unlocking
E/E Function: Door Ajar Indication

Information from the PJB if the passenger door is open or closed.";
CM_ SG_ 752 DriverDoorStatus2_212 "Sub-system: Locking / Unlocking
E/E Function: Door Ajar Indication

Information from the PJB if the driver door is open or closed.";
CM_ SG_ 752 EpasFailed_258 "E/E Function: Parking / reversing Aid
Sub-System: Parking Assistance";
CM_ SG_ 752 DisplayRequest_522 "Sub-System: Remote/Control Entry
E/E Function: Remote Control

Detection of low battery of Remote Key.Inform customer or service to change battery";
CM_ SG_ 752 ISS_StatusDspReq_207 "After deactivation of the  ISS the driver shall be informed by a chimer and a text message from the Cluster.

PJB_ISS_StatusDspReq.";
CM_ SG_ 752 AutoLRainSSensorFail_729 "Sub-system: Glass Cleaning
E/E Function: Rain Detection Windscreen Wiping";
CM_ SG_ 752 LeftDIFailure_703 "Sub-system: Exterior Lighting
E/E Function: Bulb Failure Warning Indication
";
CM_ SG_ 752 RightDIFailure_704 "Sub-system: Exterior Lighting
E/E Function: Bulb Failure Warning Indication
";
CM_ SG_ 752 BonnetLidStatus2_217 "Sub-system: Locking / Unlocking
E/E Function: Door Ajar Indication

Information from the PJB if the hood is open or closed.";
CM_ SG_ 752 BootLidStatus_216 "Sub-system: Locking / Unlocking
E/E Function: Door Ajar Indication

Information from the PJB if the hood is open or closed.";
CM_ SG_ 752 PassengerSideRearDoorStatus2_215 "Sub-system: Locking / Unlocking
E/E Function: Door Ajar Indication

Information from PJB if the rear left door is open or closed.";
CM_ SG_ 752 DriverSideRearDoorStatus2_213 "Sub-system: Locking / Unlocking
E/E Function: Door Ajar Indication

Information from the PJB if the rear right door is open or closed.";
CM_ SG_ 752 BootLidStatus_520 "Sub-system: Locking / Unlocking
E/E Function: Door Ajar Indication

Information from the PJB if the hood is open or closed.";
CM_ SG_ 752 BonnetStatus_521 "Sub-system: Locking / Unlocking
E/E Function: Door Ajar Indication

Information from the PJB if the hood is open or closed.";
CM_ SG_ 752 PassengerSideRearDoorStatus_519 "Sub-system: Locking / Unlocking
E/E Function: Door Ajar Indication

Information from PJB if the rear left door is open or closed.";
CM_ SG_ 752 DriverSideRearDoorStatus_518 "Sub-system: Locking / Unlocking
E/E Function: Door Ajar Indication

Information from the PJB if the rear right door is open or closed.";
CM_ SG_ 752 DriverDoorStatus_516 "Sub-system: Locking / Unlocking
E/E Function: Door Ajar Indication

Information from the PJB if the driver door is open or closed.";
CM_ SG_ 752 StabilityControlSt_218b "StabilityControlStatus_218b";
CM_ SG_ 752 StabilityControlTel_218c "Object.BodyInformation.Message Center.StabilityControlTelltale_218c";
CM_ SG_ 752 TransmDIWarnMsg_484 "additional warning messages in HEC (Gear cannot be engaged fast enough due to low out side temp.) 
Only CFT 23 is supporting; FN will send \"0\" (Off)";
CM_ SG_ 752 PassengerDoorStatus_517 "Sub-system: Locking / Unlocking
E/E Function: Door Ajar Indication

Information from the PJB if the passenger door is open or closed.";
CM_ SG_ 752 RIL_RequestStatus_530 "Invalid value:   
RCM requests Restraint indicator light to be OFF|FLASH|ON 
FLASH/Plant mode: is initiated until RCM is configured correctly in plant. The Display mode will be 5Hz Flashing.";
CM_ SG_ 752 SS_TurnIgnitionOff_643 "Displayed message for MFD: Further message: Switch ignition off";
CM_ SG_ 752 SS_SelectNeutral_644 "Displayed message for MFD: Put gear into neutral";
CM_ SG_ 752 SS_PressClutch_641 "Displayed message for MFD: Press clutch to start engine";
CM_ SG_ 752 SS_StartEngineManually_642 "Displayed message for MFD: Start engine manually";
CM_ SG_ 752 SS_EngineStarting_640 "Displayed message for MFD: Engine Starting";
CM_ SG_ 359 TrnAin_Tq_Actl "Object.Object.Electrical Engine Sound Enhancement.TorqueAssyIn";
CM_ SG_ 359 PlgActvArb_B_Actl "Object:PlugStatus_St";
CM_ SG_ 516 ApedPos_Pc_ActlArb "Object.Electrical Engine Sound Enhancement.AcceleratorPedalPosition";
CM_ SG_ 516 EngAout_N_Actl "Engine Speed
Object.Electrical Engine Sound Enhancement.EngineSpeedAOut";
CM_ SG_ 687 CD_MC_WORD_Rx_ "MM ISO 15765-2 Message Catalogue
Section MC - Audio";
CM_ SG_ 754 ACU_ActChimeType_St "Object BodyInterface.StdChimeIF.ActiveChime.Type.St";
CM_ SG_ 754 ACU_ActChimeTypeDat_St "Object BodyInterface.StdChimeIF.ActiveChime.TypeData.St

0x00: NoChime

ChimeType==Sine: 
Range: 0x01-0x3FF (1Hz - 16383Hz)

ChimeType==Sample: 
Range: 0x01-0x40  (Sample 1 - Sample 63)
Range: 0x41-0x3FFF (Reserved)";
CM_ SG_ 711 MyKeySrvr_MyKeyClient_Word_Tx "TP-LOG-GTPC-201379-SID-7C";
CM_ SG_ 391 ACU_CtrlChimeChan_Rq "Object BodyInterface.StdChimeIF.ControlChimeChannel.Rq";
CM_ SG_ 393 CPM_Audio_Source_RSP "Object AtlanticWizard.AudioManagement.CPM_Audio_Response.CPM_Audio_Source_RSP";
CM_ SG_ 393 CPM_Audio_State_RSP "Object AtlanticWizard.AudioManagement.CPM_Audio_Response.CPM_Audio_State_RSP";
CM_ SG_ 406 Audio_Source_Target_Cmd "Object AtlanticWizard.AudioManagement.ACM_Audio_Source_Command.Audio_Source_Target_Cmd";
CM_ SG_ 406 Primary_Audio_Source_Target "Object AtlanticWizard.AudioManagement.ACM_Audio_Source_Command.Primary_Audio_Source_Target";
CM_ SG_ 409 CPM_Audio_Source_REQ "Object AtlanticWizard.AudioManagement.CPM_Audio_Bus_Request.CPM_Audio_Source_REQ";
CM_ SG_ 409 Audio_Bus_Request_CPM "Object AtlanticWizard.AudioManagement.CPM_Audio_Bus_Request.Audio_Bus_Request_CPM";
CM_ SG_ 717 Display_Data_Stream_CPM "MM ISO 15765-2 Message Catalogue
Section CPM - RDISP";
CM_ SG_ 408 Display_Animation_Req "Object AtlanticWizard. TerminalDisplayManagement. Peripheral Display Animation Request.Display_Animation_Req";
CM_ SG_ 408 Display_Timer_CPM_Req "Object AtlanticWizard.TerminalDisplayManagement.CPM_Display_Request.Display_Timer_CPM_Req
";
CM_ SG_ 408 Display_Priority_CPM_Req "Object AtlanticWizard.TerminalDisplayManagement.CPM_Display_Request.Display_Priority_CPM_Req";
CM_ SG_ 408 Display_Overwrite_CPM_Req "Object AtlanticWizard.TerminalDisplayManagement.CPM_Display_Request.Display_Overwrite_CPM_Req";
CM_ SG_ 408 Display_Start_Position_CPM "Object AtlanticWizard.TerminalDisplayManagement.CPM_Display_Request.Display_Start_Position_CPM";
CM_ SG_ 408 Display_Field_CPM_Req "Object AtlanticWizard.TerminalDisplayManagement.CPM_Display_Request.Display_Field_CPM_Req";
CM_ SG_ 408 Display_Target_CPM_Req "Object AtlanticWizard.TerminalDisplayManagement.CPM_Display_Request.Display_Target_CPM_Req";
CM_ SG_ 407 Dsp_MediaSrcAct_Rq "Object AtlanticWizard.AudioManagement.MediaSourceActivationRequest_Rq";
CM_ SG_ 407 Dsp_MediaSrcLst_Rq "Object AtlanticWizard.AudioManagement.MediaSourceListRequest_Rq";
CM_ SG_ 407 Display_Requestor_ACM_Status "Object AtlanticWizard.TerminalDisplayManagement.ACM_Display_Status.Display_Requestor_ACM_Status";
CM_ SG_ 407 Display_Grant_ACM_Status "Object AtlanticWizard.TerminalDisplayManagement.ACM_Display_Status.Display_Grant_ACM_Status";
CM_ SG_ 407 Display_Field_ACM_Status "Object AtlanticWizard.TerminalDisplayManagement.ACM_Display_Status.Display_Field_ACM_Status";
CM_ SG_ 1003 CPM_Acceleration_St "Object. MediaSettings.Accleration.St";
CM_ SG_ 1003 CPM_Stereo_PAS_Source "Object AtlanticWizard.TerminalDisplayManagement.CPM_Stereo_PAS_Source.Status";
CM_ SG_ 1003 CPM_Signal_Strength_STAT "Object AtlanticWizard.TerminalDisplayManagement.CPM_Signal_Strength_STAT .Status";
CM_ SG_ 1003 CPM_Mono_Audio_Output "Object AtlanticWizard.AudioManagement.CPM_Mono_Audio_Output.Status";
CM_ SG_ 1003 CPM_Batt_Level_STAT "Object AtlanticWizard.TerminalDisplayManagement.CPM_Batt_Level_STAT.Status";
CM_ SG_ 1003 CPM_TextMsg_AVAL "Object AtlanticWizard.TerminalDisplayManagement.CPM_TextMsg_AVAL .Status";
CM_ SG_ 1003 CPM_Stereo_Audio_Output "Object AtlanticWizard.AudioManagement.CPM_Stereo_Audio_Output.Status";
CM_ SG_ 1003 CPM_Phone_Roaming_STAT "Object AtlanticWizard.TerminalDisplayManagement.CPM_Phone_Roaming_STAT.Staus";
CM_ SG_ 1003 CPM_Call_Active_STAT "Object AtlanticWizard.TerminalDisplayManagement.CPM_Call_Active_STAT.Status";
CM_ SG_ 1003 BT_ICON "Object AtlanticWizard.TerminalDisplayManagement.BT_Icon.Status";
CM_ SG_ 1003 CPM_VoiceRec_STAT "Object AtlanticWizard.AudioManagement.CPM_VoiceRec_STAT.Status";
CM_ SG_ 675 NAV_Active_Screen_Status "Object AtlanticWizard.TerminalDisplayManagement.NAV_Active_Screen.St.Status
Refer also to Functional Requirement for Active Screen Status";
CM_ SG_ 675 Current_Focus_Bar_St "Object AtlanticWizard.TerminalDisplayManagement.Current_Focus_Bar.St.Status";
CM_ SG_ 675 Dsp_LangSel_St "Object.VehicleSettings.Disp_LangSel.St";
CM_ SG_ 675 Multimedia_System "Object AtlanticWizard.PowerManagement.Multimedia_System.Status";
CM_ SG_ 675 ACM_Display_Type "Object AtlanticWizard.TerminalDisplayManagement.ACM_Display_Type.Status";
CM_ SG_ 675 Pop_Up_Focus_Bar_St "Object AtlanticWizard.TerminalDisplayManagement.Pop_Up_Focus_Bar.St.Status";
CM_ SG_ 675 Active_Pop_Up_St "Object AtlanticWizard.TerminalDisplayManagement.Active_Pop_Up.St.Status
Refer also to Functional Requirement for Active_Pop_Up Status";
CM_ SG_ 675 Primary_Audio_Source_ACM "Object AtlanticWizard.AudioManagement.Primary_Audio_Source_ACM.Status";
CM_ SG_ 263 PrsnlCnnctReset_D_Rq "Object:PeripheralResetPhase";
CM_ SG_ 263 ACM_CPM_VR_CMND "Object AtlanticWizard.AudioManagement.ACM_CPM_VR_CMND.Command";
CM_ SG_ 263 ACM_CPM_Stereo_Audio_CMND "Object AtlanticWizard.AudioManagement.ACM_CPM_Stereo_Audio_CMND.Command";
CM_ SG_ 263 ACM_CPM_Mono_Audio_CMND "Object AtlanticWizard.AudioManagement.ACM_CPM_Mono_Audio_CMND.Command";
CM_ SG_ 262 Dsp_SetAcceleration_Rq "Object MediaSettings.SetAcceleration.Rq";
CM_ SG_ 262 Dsp_RotAddrlAccLvl_St "Object AtlanticWizard.ButtonInputManagement.RotaryButtonSelectItem.DetectedAccelerationLevel";
CM_ SG_ 262 Dsp_RotAddrBtnEv_St "Object AtlanticWizard.ButtonInputManagement.RotaryButtonSelectItem.ButtonEvents

LIN/CAN gateway interface";
CM_ SG_ 262 ACM_Target_ID "Object AtlanticWizard.ButtonInputManagement.ACM_Button_Press.ACM_Target_ID";
CM_ SG_ 262 ACM_Button_State "Object AtlanticWizard.ButtonInputManagement.ACM_Button_Press.ACM_Button_State";
CM_ SG_ 262 ACM_Button_Type "Object AtlanticWizard.ButtonInputManagement.ACM_Button_Press.ACM_Button_Type
0x00 - 0xFF reference button function matrix.";
CM_ SG_ 534 WhlRotatRr_No_Cnt "Signal not in use; APIM will receive this information from a non-infotainment network. Signal could not be removed due to issues during generating the APIM target file onto supplier side.";
CM_ SG_ 534 WhlDirRr_D_Actl "Signal not in use; APIM will receive this information from a non-infotainment network. Signal could not be removed due to issues during generating the APIM target file onto supplier side.";
CM_ SG_ 534 WhlDirRl_D_Actl "Signal not in use; APIM will receive this information from a non-infotainment network. Signal could not be removed due to issues during generating the APIM target file onto supplier side.";
CM_ SG_ 534 WhlDirFr_D_Actl "Signal not in use; APIM will receive this information from a non-infotainment network. Signal could not be removed due to issues during generating the APIM target file onto supplier side.";
CM_ SG_ 534 WhlDirFl_D_Actl "Signal not in use; APIM will receive this information from a non-infotainment network. Signal could not be removed due to issues during generating the APIM target file onto supplier side.";
CM_ SG_ 534 WhlRotatRl_No_Cnt "Signal not in use; APIM will receive this information from a non-infotainment network. Signal could not be removed due to issues during generating the APIM target file onto supplier side.";
CM_ SG_ 534 WhlRotatFr_No_Cnt "Signal not in use; APIM will receive this information from a non-infotainment network. Signal could not be removed due to issues during generating the APIM target file onto supplier side.";
CM_ SG_ 534 WhlRotatFl_No_Cnt "Signal not in use; APIM will receive this information from a non-infotainment network. Signal could not be removed due to issues during generating the APIM target file onto supplier side.";
CM_ SG_ 656 HMI_DimmingLevelStatus "Dimming Level HMI Menu in the MFD. Moved content from C-car instrument cluster to MFD / DM6 of B232 and B299 MCA.";
CM_ SG_ 656 HMI_DimmingModeStatus "Dimming Mode Menu is moved from instrument cluster on C-Car to MFD / DM6 on B232 and B299MCA. The MFD has to distribute the dimming mode status.";
CM_ SG_ 656 Ill_BEZZone_St "Object Illumination.IlluminationZone
0: not pressed
1: pressed

Bit 0:  0: invalid, 1: valid
Bit 1: VolumeKnob
Bit 2: HazardWarning_Doorlock
Bit 3: CD_Slot
Bit 4: Zone2
Bit 5: Zone1
Bit 6: HaloAroundToggle
Bit 7: Reserved1";
CM_ SG_ 1008 CPM_MediaPlayerSrc_St "Object AtlanticWizard.AudioManagement.PeripheralMediaPlayerAudioSourceStatus_St";
CM_ SG_ 1008 APIM_TrackPlaytime_St "Object.Mediaplayer.TotalPlayTime";
CM_ SG_ 1008 APIM_TotalPlayTime_St "Object.Mediaplayer.TotalPlayTime";
CM_ SG_ 404 Dsp_LangUpdate_Rsp "Object. LanguageUpdate.Rsp";
CM_ SG_ 291 LangUpdate_Rsp "Object. LanguageUpdate.Rsp";
CM_ SG_ 493 Dsp_AFJump_Rq "Object Tuner.AFJump.Rq";
CM_ SG_ 493 Dsp_RefreshFlag "Object Tuner.GetStationList(StationList)
(Parameter5)";
CM_ SG_ 493 Dsp_StatLiScanCancel_Rq "Object Tuner.StationListScan";
CM_ SG_ 493 Dsp_PTYCode_Rq "Object Tuner.GetStationList(PTYCode)
(Parramater4)

$0: Invalid
$1: PTY 1 (News)
..
$1F: PTY 31 (Alarm)";
CM_ SG_ 493 Dsp_StartIndex3_Rq "Object TunerGetStationList(StartingIndex)
(Parameter3)";
CM_ SG_ 493 Dsp_ListSize_Rq "Object Tuner.GetStationList(ListSize)
(Parameter2)";
CM_ SG_ 493 Dsp_StationList_Rq "Object Tuner.GetStationList(StationList)
(Parameter1)";
CM_ SG_ 708 TMCSrvr_TMCClient_WORD_Tx "MM ISO 15765-2 Message Catalogue
Section: TMCServer - TMCClient";
CM_ SG_ 402 ApaMdeStat_D_RqDrv "Object.FAS Parking Aid.ApaMdeStat_D_RqDrv.Type";
CM_ SG_ 402 DistanceBarSetting "Object.RVCClient. DistanceBar";
CM_ SG_ 402 CamraZoomMan_D_Rq "Obejct: RVC Client.RVC Zoom";
CM_ SG_ 402 CamraOvrlStat_D_Rq "Obejct: RVC Client.StaticGuideline";
CM_ SG_ 402 CamraOvrlDyn_D_Rq "Obejct: RVC Client.DynamicGuideline";
CM_ SG_ 402 CamAutoTowbarZoom "Obejct: RVC Client.AutoZoom";
CM_ SG_ 402 CamraOvrlTow_D_Rq "Object:CamraOvrlTow_D_Rq";
CM_ BO_ 265 "$230 & $201 on the Body Bus";
CM_ SG_ 265 Light_SW_Position "This signal is a mirror of the accumulated pushbutton dimmer or actual debounced rotary dimmer state. Signal is used as dimmer stuts indication in MFD dimming menu on ICAN. Signal name is VCC heritage and might be misleading.";
CM_ SG_ 265 KeyMykeyTot_No_Cnt "Object MyKey.NumberOfMyKeys_St";
CM_ SG_ 265 IgnKeyType_D_Actl "Object MyKey.IgnKeyType_D_Actl";
CM_ SG_ 265 VehVActlEng_D_Qf "Vehicle_Speed_QF";
CM_ SG_ 265 Veh_V_ActlEng "Method: Vehicle_Speed.St.VehicleSpeed_St
{CGEA}";
CM_ SG_ 265 GearLvrPos_D_Actl "Object:BezelDiagnostics. PRNDL.St

Sync Gen2 only";
CM_ SG_ 265 EngAout_N_Actl "Engine Speed
Object.Electrical Engine Sound Enhancement.EngineSpeedAOut";
CM_ SG_ 265 GearRvrseActv_D_Actl "Object BodyInterface.ReverseGearStatus
{CGEA}

Legacy signals: Not to be used for Reverse Gear information after C1mca #J1 timing:
PJB_ReverseGearSwitch
GearLvrPos_D_Actl";
CM_ SG_ 709 DSPAMP_RDISP_WORD_Tx "Object:BezelDiagnostics.DSP_Bezel_Diag_Data";
CM_ SG_ 758 SDARS_OpMode_St "Object Tuner.SDARS Tuner.OperationMode";
CM_ SG_ 758 SDARS_SetCategory_St "Object.ExternalPersonalization.SDARS_SetCategory.St.Category
0x00: All
0x01: Category1
0x02: Category2
....
0xF9: Category249
0xFA: Reserved
....
0xFE: Reserved
0xFF: Invalid 
";
CM_ SG_ 758 SDARS_GCI_Update_Prg_St "Object Tuner.SDARS Tuner.GCIUpdateProgress
0-100%";
CM_ SG_ 758 SDARS_Factory_Reset_St "Object Tuner.SDARS Tuner.FactoryReset";
CM_ SG_ 761 SDARS_Seek_Scan_St "Method SDARS_Error_Msg
Int Seek/Scan No Channels Available

0x1: No Channel Available
Object Tuner.SDARS Tuner.";
CM_ SG_ 761 SDARS_Invalid_Chan_St "Object Tuner.SDARS Tuner.";
CM_ SG_ 761 SDARS_UnSubscrb_Chan_St "Object Tuner.SDARS Tuner.Unsubscribed Channel ";
CM_ SG_ 761 SDARS_Loss_Ant_St "Object Tuner.SDARS Tuner.Loss of Antenna Signal ";
CM_ SG_ 761 SDARS_UnSubscrb_St "Object Tuner.SDARS Tuner.Unsubscribed Receiver ";
CM_ SG_ 761 SDARS_Subscription_St "Object Tuner.SDARS Tuner.Subscription Update ";
CM_ SG_ 761 SDARS_GCI_Update_St "Object Tuner.SDARS Tuner.GCI Update ";
CM_ SG_ 761 SDARS_Firmware_Update_St "Object Tuner.SDARS Tuner.FirmwareUpdate";
CM_ SG_ 761 SDARS_Antenna_Err_St "Object Tuner.SDARS Tuner.Antenna Error";
CM_ SG_ 761 SDARS_Receive_Err_St "Object Tuner.SDARS Tuner.Receiver Error";
CM_ SG_ 761 SDARS_Error_Conf_St "Object Tuner.SDARS Tuner.Configuration Status";
CM_ SG_ 760 SDARS_SID_St "Object Tuner.SDARS.ServiceID
$0: SID_0
$1: SID_1
$2: SID_2
$FE: SID_254
$FF: SID_255

";
CM_ SG_ 760 SDARS_CurrentChanNum_St "Object Tuner.SDARS Tuner.CurrentChanNum.ChanNum 
$0: Channel_0
$1: Channel_1
$2: Channel_2
$FE: Channel_254
$FF: Inactive";
CM_ SG_ 760 SDARS_Buffer_sec_St "Object Tuner.SDARS Tuner.BufferStatus.Second
(Parameter5)
";
CM_ SG_ 760 SDARS_Buffer_min_St "Object Tuner.SDARS Tuner.BufferStatus.Minute
(Parameter4)
";
CM_ SG_ 760 SDARS_Buffer_hr_St "Object Tuner.SDARS Tuner.BufferStatus.Hour
(Parameter3)
";
CM_ SG_ 760 SDARS_Playback_St "Method SDARS_BufferStatus
0-100%
Object Tuner.SDARS Tuner.BufferStatus.PlaybackPosition
(Parameter2)";
CM_ SG_ 760 SDARS_FillPosition_St "Method SDARS_BufferStatus
0-100%
Object Tuner.SDARS Tuner.BufferStatus.FillPosition
(Parameter1)";
CM_ SG_ 760 SDARS_Alert_Status "Object.Tuner.SDARS.AlertStatus";
CM_ SG_ 760 SDARS_Channel_Lock "Method SDARS_Channel_Lock";
CM_ SG_ 260 SDARS_InfoRefChanNum_Rq "Object Tuner.SDARS Tuner.InfoRefresh.Rq
$0: Channel_0
$1: Channel_1
$2: Channel_2
$FE: Channel_254
$FF: Inactive";
CM_ SG_ 260 SDARS_GetESN_Rq "Object Tuner.SDARS Tuner.GetESN";
CM_ SG_ 260 SDARS_FactoryReset_Rq "Object Tuner.SDARS Tuner.FactoryReset";
CM_ SG_ 260 MFD_SDARS_SetOpMode_Rq "Object Tuner.SDARS Tuner.SetOperationMode";
CM_ SG_ 260 SDARS_SRReplay_Rq "Object Tuner.SDARS Tuner.SR-ReplayStatus";
CM_ SG_ 260 SDARS_SelectCategory_Rq "Object Tuner.SDARS Tuner.SetCategory
0x00: All
0x01: Category1
0x02: Category2
....
0xF9: Category249
0xFA: Reserved
....
0xFE: Reserved
0xFF: Invalid
";
CM_ SG_ 260 MFD_SDARS_DirectTune_Rq "Object Tuner.SDARS Tuner.DirectTune
$0: Channel_0
$1: Channel_1
$2: Channel_2
$FE: Channel_254
$FF: Inactive";
CM_ SG_ 259 SDARS_CurrCATlistSize_Rq "Object:SDARSClient.CurrentCatList.Rq.NumberOfItems 

0x00: Invalid
0x01: List Size 1
0x02: List Size 2
....
0x1E: List Size 30
0xFF: No Entry
";
CM_ SG_ 259 SDARS_CurrCATlistInd_Rq "ObjectTuner.SDARSTuner.CurrentCATList
$0: Inactive
$FF:No_Entry";
CM_ SG_ 259 SDARS_AlertStatus_Rq "Object.SDARSClient.AlertStatus.Rq.Status";
CM_ SG_ 759 Avail_HD_Chan_Valid "Object. AvailableHDChannel.St";
CM_ SG_ 759 Avail_HD_Chan_St_7 "Object. AvailableHDChannel.St";
CM_ SG_ 759 Avail_HD_Chan_St_6 "Object. AvailableHDChannel.St";
CM_ SG_ 759 Avail_HD_Chan_St_5 "Object. AvailableHDChannel.St";
CM_ SG_ 759 Avail_HD_Chan_St_4 "Object. AvailableHDChannel.St";
CM_ SG_ 759 Avail_HD_Chan_St_3 "Object. AvailableHDChannel.St";
CM_ SG_ 759 Avail_HD_Chan_St_2 "Object. AvailableHDChannel.St";
CM_ SG_ 759 Avail_HD_Chan_St_1 "Object. AvailableHDChannel.St";
CM_ SG_ 759 ACM_StationListScanSt "Object.AMFMSlave.StationListScan
$0:Invalid";
CM_ SG_ 759 ACM_TagMode "Object.AMFMSlave.TagMode";
CM_ SG_ 759 ACM_RBDSMode "Object.AMFMSlave.RBDSMode";
CM_ SG_ 759 NumofHDMulticastChans_St "Object. AMFMSlave.NumofHDMulticastChans";
CM_ SG_ 759 ACM_HDModeStatus "Object.AMFMSlave.HDMode";
CM_ SG_ 759 ACM_HDChanStatus "Object. AMFMSlave.HDChanStatus
$0:Inactive";
CM_ SG_ 759 ACM_CurrentSSName "Object.AMFMSlave.Method CurrentSSName";
CM_ SG_ 759 ACM_CurrentHDMulticast_St "Object.AMFMSlave.CurrentHDMulticast";
CM_ BO_ 947 "On C34x, this messages will be sent out as Fixed Periodic with 120ms cycle time.";
CM_ SG_ 947 Outside_Air_Temp_Stat "Note this is the Filtered value, i.e. same as displyed for the customer.";
CM_ SG_ 947 Ignition_Switch_Stable "Interface used to enable diagnostic feature for FNA legacy nodes.";
CM_ SG_ 947 PrkBrkActv_B_Actl "Method: Park_Brake";
CM_ SG_ 947 Ignition_Status "Object Power Management.IgnitionStatus_St
Object My Car Info.IgnitionStatus_St
Object Remote Administration.IgnitionStatus_St
";
CM_ SG_ 129 SteWhlCtl_Phone_UB "Refer Input Translation Matrix for Button Mapping in the SPSS";
CM_ SG_ 129 SteWhlCtl_Phone "Refer Input Translation Matrix for Button Mapping in the SPSS";
CM_ SG_ 129 SteWhlCtl_Mute_UB "Refer Input Translation Matrix for Button Mapping in the SPSS";
CM_ SG_ 129 SteWhlCtl_Mute "Refer Input Translation Matrix for Button Mapping in the SPSS";
CM_ SG_ 129 SteWhlCtl_Volume_Up_UB "Refer Input Translation Matrix for Button Mapping in the SPSS";
CM_ SG_ 129 SteWhlCtl_Volume_Down_UB "Refer Input Translation Matrix for Button Mapping in the SPSS";
CM_ SG_ 129 SteWhlCtl_Voice_PTT_UB "Refer Input Translation Matrix for Button Mapping in the SPSS";
CM_ SG_ 129 SteWhlCtl_Seek_Right_UB "Refer Input Translation Matrix for Button Mapping in the SPSS";
CM_ SG_ 129 SteWhlCtl_Seek_Left_UB "Refer Input Translation Matrix for Button Mapping in the SPSS";
CM_ SG_ 129 SteWhlCtl_RSideCursLeft_UB "Refer Input Translation Matrix for Button Mapping in the SPSS";
CM_ SG_ 129 SteWhlCtl_RSideCursDown_UB "Refer Input Translation Matrix for Button Mapping in the SPSS";
CM_ SG_ 129 SteWhlCtl_RSide_OK_UB "Refer Input Translation Matrix for Button Mapping in the SPSS";
CM_ SG_ 129 SteWhlCtl_RSide_CursUp_UB "Refer Input Translation Matrix for Button Mapping in the SPSS";
CM_ SG_ 129 SteWhlCtl_RSide_CursRt_UB "Refer Input Translation Matrix for Button Mapping in the SPSS";
CM_ SG_ 129 SteWhlCtl_Mode_UB "Refer Input Translation Matrix for Button Mapping in the SPSS";
CM_ SG_ 129 SteWhlCtl_Volume_Up "Refer Input Translation Matrix for Button Mapping in the SPSS";
CM_ SG_ 129 SteWhlCtl_Volume_Down "Refer Input Translation Matrix for Button Mapping in the SPSS";
CM_ SG_ 129 SteWhlCtl_Voice_PTT "Refer Input Translation Matrix for Button Mapping in the SPSS";
CM_ SG_ 129 SteWhlCtl_Seek_Right "Refer Input Translation Matrix for Button Mapping in the SPSS";
CM_ SG_ 129 SteWhlCtl_Seek_Left "Refer Input Translation Matrix for Button Mapping in the SPSS";
CM_ SG_ 129 SteWhlCtl_Mode "Refer Input Translation Matrix for Button Mapping in the SPSS";
CM_ SG_ 129 SteWhlCtl_RSide_OK "Refer Input Translation Matrix for Button Mapping in the SPSS";
CM_ SG_ 129 SteWhlCtl_RSide_CursorUp "Refer Input Translation Matrix for Button Mapping in the SPSS";
CM_ SG_ 129 SteWhlCtl_RSide_CursorRt "Refer Input Translation Matrix for Button Mapping in the SPSS";
CM_ SG_ 129 SteWhlCtl_RSide_CursorLeft "Refer Input Translation Matrix for Button Mapping in the SPSS";
CM_ SG_ 129 SteWhlCtl_RSide_CursorDown "Refer Input Translation Matrix for Button Mapping in the SPSS";
CM_ SG_ 129 SteWhlCtl_Media_UB "Refer Input Translation Matrix for Button Mapping in the SPSS";
CM_ SG_ 129 SteWhlCtl_Media "Refer Input Translation Matrix for Button Mapping in the SPSS";
CM_ SG_ 855 RCCM_Rr_Rt_TempSetpt "0x0 = Off

Setpoint_C Range 0.5 (0x01) - 40.0 (0x50)

Setpoint_F Range  40.5 (0x51) - 90.0 (0xB4)

Detents Range 1 (0xB5) - 31 (0xD4)";
CM_ SG_ 855 RCCM_Fr_Left_TempSetpt "0x0 = Off Shall never be set

Setpoint_C Range 0.5 (0x01) - 40.0 (0x50)

Setpoint_F Range  40.5 (0x51) - 90.0 (0xB4)

Detents Range 1 (0xB5) - 31 (0xD4)";
CM_ SG_ 855 RCCM_Fr_Rt_TempSetpt "0x0 = Off

Setpoint_C Range 0.5 (0x01) - 40.0 (0x50)

Setpoint_F Range  40.5 (0x51) - 90.0 (0xB4)

Detents Range 1 (0xB5) - 31 (0xD4)";
CM_ SG_ 855 RCCM_Rr_Left_TempSetpt "0x0 = Off

Setpoint_C Range 0.5 (0x01) - 40.0 (0x50)

Setpoint_F Range  40.5 (0x51) - 90.0 (0xB4)

Detents Range 1 (0xB5) - 31 (0xD4)";
BA_DEF_ BO_  "FrameType" INT 0 2;
BA_DEF_ BO_  "TpMessage" ENUM  "No","Yes";
BA_DEF_ BO_  "GenMsgIlSupport" ENUM  "No","Yes";
BA_DEF_ SG_  "GenSigTimeoutTime__delete" INT 0 100000;
BA_DEF_ SG_  "GenSigTimeoutTime_CPM" INT 0 100000;
BA_DEF_ SG_  "GenSigTimeoutTime_DSP" INT 0 100000;
BA_DEF_ SG_  "GenSigTimeoutTime_AHU" INT 0 100000;
BA_DEF_ SG_  "GenSigTimeoutTime_IPC" INT 0 100000;
BA_DEF_ SG_  "GenSigTimeoutTime_MFD" INT 0 100000;
BA_DEF_ BO_  "TpTxIndex" INT 0 10000;
BA_DEF_ BO_  "GenMsgILSupport" ENUM  "No","Yes";
BA_DEF_ BO_  "FrameGatewayNetwork_OLD" ENUM  "None","HS1_CAN","HS2_CAN","HS3_CAN","MS1_CAN";
BA_DEF_ BO_  "FrameGatewayMS1" HEX 0 1407;
BA_DEF_ BO_  "FrameGatewayLC1" HEX 0 1407;
BA_DEF_ BO_  "FrameGatewayHS2" HEX 0 1407;
BA_DEF_ BO_  "FrameGatewayHS1" HEX 0 1407;
BA_DEF_ BO_  "FrameGatewayId" HEX 0 1407;
BA_DEF_ BO_  "NetworkInitialization" ENUM  "No","Yes";
BA_DEF_ BO_  "GenMsgStartDelayTime" INT 0 100000;
BA_DEF_ BO_  "GenMsgNrOfRepetition" INT 0 100;
BA_DEF_ BO_  "GenMsgDelayTime" INT 0 1000;
BA_DEF_ BO_  "GenMsgCycleTimeFast" INT 0 100000;
BA_DEF_ BO_  "GenMsgCycleTime" INT 0 10000;
BA_DEF_ BO_  "GenMsgSendType" ENUM  "FixedPeriodic","Event","EnabledPeriodic","NotUsed","NotUsed","EventPeriodic","NotUsed","NotUsed","NoMsgSendType";
BA_DEF_ BO_  "FrameGateway_nonCGEA" HEX 0 1407;
BA_DEF_ SG_  "WakeupSignal" ENUM  "No","Yes";
BA_DEF_ SG_  "GenSigMissingSourceValue" INT 0 1000000000;
BA_DEF_ SG_  "GenSigSendType" ENUM  "Cyclic","OnWrite","OnWriteWithRepetition","OnChange","OnChangeWithRepetition","IfActive","IfActiveWithRepetition","NoSigSendType";
BA_DEF_ SG_  "EventRateOfChange" INT 10 10000;
BA_DEF_ SG_  "HS3_Category" ENUM  "Standardized","Restricted","Proposed","Prohibited","Duplicated";
BA_DEF_ SG_  "FISI_Comment_Sig" STRING ;
BA_DEF_ SG_  "GenSigEnvVarType" ENUM  "int","float","undef";
BA_DEF_ SG_  "LegacySignalName" STRING ;
BA_DEF_ SG_  "GenSigStartMeaning" STRING ;
BA_DEF_ SG_  "GenSigMissingSourceMeaning" STRING ;
BA_DEF_ SG_  "FMC_SIG_Issue" STRING ;
BA_DEF_ SG_  "FMC_SIG_SSPEC" STRING ;
BA_DEF_ SG_  "VNASignalName" STRING ;
BA_DEF_ SG_  "InvalidHex" STRING ;
BA_DEF_ SG_  "NWM-WakeupAllowed" ENUM  "No","Yes";
BA_DEF_ SG_  "GenSigStartValue" FLOAT 0 100000000000;
BA_DEF_ SG_  "GenSigInactiveValue" INT 0 100000;
BA_DEF_ BO_  "FISI_Comment_Msg" STRING ;
BA_DEF_ BO_  "FMC_MSG_Issue" STRING ;
BA_DEF_ BO_  "CGEA_Message" ENUM  "No","Yes";
BA_DEF_ BO_  "NmAsrMessage" ENUM  "No","Yes";
BA_DEF_ BO_  "VNATransmissionType" ENUM  "periodic","sporadic","immediate";
BA_DEF_ BO_  "NetworkInitializationCommand" ENUM  "No","Yes";
BA_DEF_ BO_  "DiagState" ENUM  "No","Yes";
BA_DEF_ BO_  "DiagRequest" ENUM  "No","Yes";
BA_DEF_ BO_  "DiagResponse" ENUM  "No","Yes";
BA_DEF_ BO_  "NmMessage" ENUM  "No","Yes","vector_leerstring";
BA_DEF_ BU_  "NosPackage" ENUM  "None","I3_1","I3_2","1.0.1","RP","EuCD","Volcano";
BA_DEF_ BU_  "Terminator" ENUM  "No","Yes","vector_leerstring";
BA_DEF_ BU_  "GatewayECU" ENUM  "No","Yes";
BA_DEF_ BU_  "PackageID" STRING ;
BA_DEF_ BU_  "EOL_SB_Flash" ENUM  "Yes","No";
BA_DEF_ BU_  "DiagNode" ENUM  "Yes","No";
BA_DEF_ BU_  "PowerType" ENUM  "Switched","Latched","Sleep","vector_leerstring","vector_leerstring";
BA_DEF_ BU_  "NmAsrNode" ENUM  "No","Yes";
BA_DEF_ BU_  "NmAsrNodeIdentifier" HEX 0 255;
BA_DEF_ BU_  "NodeStartUpTime" INT 0 1000;
BA_DEF_ BU_  "NodeWakeUpTime" INT 0 1000;
BA_DEF_ BU_  "BootloaderEnabled" ENUM  "Yes","No";
BA_DEF_ BU_  "NmCAN" INT 1 3;
BA_DEF_ BU_  "NodeLayerModules" STRING ;
BA_DEF_ BU_  "NetworkInitializationUsed" ENUM  "No","Yes";
BA_DEF_ BU_  "NmNode" ENUM  "No","Yes";
BA_DEF_ BU_  "NmStationAddress" HEX 0 127;
BA_DEF_ BU_  "ILUsed" ENUM  "No","Yes";
BA_DEF_  "StarNetworkGwType" ENUM  "0=NotDefined","1=HS1","2=HS2","3=HS3","4=HS4","5=HS5","6=MS1";
BA_DEF_  "GenEnvVarEndingSnd" STRING ;
BA_DEF_  "GenEnvVarEndingDsp" STRING ;
BA_DEF_  "UseLegacyNames" ENUM  "No","Yes";
BA_DEF_  "CMDB_Version" STRING ;
BA_DEF_  "BusType" STRING ;
BA_DEF_  "ReleaseVersionString" STRING ;
BA_DEF_  "DBName" STRING ;
BA_DEF_  "NmAsrBaseAddress" HEX 1408 1408;
BA_DEF_  "NmAsrMessageCount" INT 128 128;
BA_DEF_  "NetworkSpeed" ENUM  "500kBits/s","125kBit/s";
BA_DEF_  "GenEnvVarPrefix" STRING ;
BA_DEF_  "Manufacturer" STRING ;
BA_DEF_  "VersionNumber" INT 0 10000;
BA_DEF_  "VersionDay" INT 0 31;
BA_DEF_  "VersionMonth" INT 0 12;
BA_DEF_  "VersionYear" INT 0 99;
BA_DEF_  "NmType" STRING ;
BA_DEF_  "NmBaseAddress" HEX 0 2047;
BA_DEF_  "NmMessageCount" INT 0 128;
BA_DEF_ BO_  "SystemMessageLongSymbol" STRING ;
BA_DEF_DEF_  "FrameType" 2;
BA_DEF_DEF_  "TpMessage" "No";
BA_DEF_DEF_  "GenMsgIlSupport" "Yes";
BA_DEF_DEF_  "GenSigTimeoutTime__delete" 5000;
BA_DEF_DEF_  "GenSigTimeoutTime_CPM" 5000;
BA_DEF_DEF_  "GenSigTimeoutTime_DSP" 5000;
BA_DEF_DEF_  "GenSigTimeoutTime_AHU" 5000;
BA_DEF_DEF_  "GenSigTimeoutTime_IPC" 5000;
BA_DEF_DEF_  "GenSigTimeoutTime_MFD" 5000;
BA_DEF_DEF_  "TpTxIndex" 0;
BA_DEF_DEF_  "GenMsgILSupport" "Yes";
BA_DEF_DEF_  "FrameGatewayNetwork_OLD" "None";
BA_DEF_DEF_  "FrameGatewayMS1" 0;
BA_DEF_DEF_  "FrameGatewayLC1" 0;
BA_DEF_DEF_  "FrameGatewayHS2" 0;
BA_DEF_DEF_  "FrameGatewayHS1" 0;
BA_DEF_DEF_  "FrameGatewayId" 0;
BA_DEF_DEF_  "NetworkInitialization" "No";
BA_DEF_DEF_  "GenMsgStartDelayTime" 0;
BA_DEF_DEF_  "GenMsgNrOfRepetition" 1;
BA_DEF_DEF_  "GenMsgDelayTime" 20;
BA_DEF_DEF_  "GenMsgCycleTimeFast" 0;
BA_DEF_DEF_  "GenMsgCycleTime" 0;
BA_DEF_DEF_  "GenMsgSendType" "NoMsgSendType";
BA_DEF_DEF_  "FrameGateway_nonCGEA" 1407;
BA_DEF_DEF_  "WakeupSignal" "No";
BA_DEF_DEF_  "GenSigMissingSourceValue" 0;
BA_DEF_DEF_  "GenSigSendType" "NoSigSendType";
BA_DEF_DEF_  "EventRateOfChange" 10000;
BA_DEF_DEF_  "HS3_Category" "Standardized";
BA_DEF_DEF_  "FISI_Comment_Sig" "";
BA_DEF_DEF_  "GenSigEnvVarType" "undef";
BA_DEF_DEF_  "LegacySignalName" "";
BA_DEF_DEF_  "GenSigStartMeaning" "Unknown";
BA_DEF_DEF_  "GenSigMissingSourceMeaning" "Unknown";
BA_DEF_DEF_  "FMC_SIG_Issue" "Unknown";
BA_DEF_DEF_  "FMC_SIG_SSPEC" "Unknown";
BA_DEF_DEF_  "VNASignalName" "";
BA_DEF_DEF_  "InvalidHex" "";
BA_DEF_DEF_  "NWM-WakeupAllowed" "No";
BA_DEF_DEF_  "GenSigStartValue" 0;
BA_DEF_DEF_  "GenSigInactiveValue" 0;
BA_DEF_DEF_  "FISI_Comment_Msg" "";
BA_DEF_DEF_  "FMC_MSG_Issue" "Unknown";
BA_DEF_DEF_  "CGEA_Message" "No";
BA_DEF_DEF_  "NmAsrMessage" "No";
BA_DEF_DEF_  "VNATransmissionType" "periodic";
BA_DEF_DEF_  "NetworkInitializationCommand" "No";
BA_DEF_DEF_  "DiagState" "No";
BA_DEF_DEF_  "DiagRequest" "No";
BA_DEF_DEF_  "DiagResponse" "No";
BA_DEF_DEF_  "NmMessage" "No";
BA_DEF_DEF_  "NosPackage" "I3_1";
BA_DEF_DEF_  "Terminator" "No";
BA_DEF_DEF_  "GatewayECU" "No";
BA_DEF_DEF_  "PackageID" "08.05.00.";
BA_DEF_DEF_  "EOL_SB_Flash" "Yes";
BA_DEF_DEF_  "DiagNode" "Yes";
BA_DEF_DEF_  "PowerType" "Switched";
BA_DEF_DEF_  "NmAsrNode" "No";
BA_DEF_DEF_  "NmAsrNodeIdentifier" 0;
BA_DEF_DEF_  "NodeStartUpTime" 250;
BA_DEF_DEF_  "NodeWakeUpTime" 10;
BA_DEF_DEF_  "BootloaderEnabled" "No";
BA_DEF_DEF_  "NmCAN" 3;
BA_DEF_DEF_  "NodeLayerModules" "";
BA_DEF_DEF_  "NetworkInitializationUsed" "No";
BA_DEF_DEF_  "NmNode" "No";
BA_DEF_DEF_  "NmStationAddress" 0;
BA_DEF_DEF_  "ILUsed" "Yes";
BA_DEF_DEF_  "StarNetworkGwType" "0=NotDefined";
BA_DEF_DEF_  "GenEnvVarEndingSnd" "_";
BA_DEF_DEF_  "GenEnvVarEndingDsp" "Dsp_";
BA_DEF_DEF_  "UseLegacyNames" "No";
BA_DEF_DEF_  "CMDB_Version" "v10.17";
BA_DEF_DEF_  "BusType" "CAN";
BA_DEF_DEF_  "ReleaseVersionString" "_draft";
BA_DEF_DEF_  "DBName" "";
BA_DEF_DEF_  "NmAsrBaseAddress" 1408;
BA_DEF_DEF_  "NmAsrMessageCount" 128;
BA_DEF_DEF_  "NetworkSpeed" "500kBits/s";
BA_DEF_DEF_  "GenEnvVarPrefix" "IMS";
BA_DEF_DEF_  "Manufacturer" "Ford";
BA_DEF_DEF_  "VersionNumber" 0;
BA_DEF_DEF_  "VersionDay" 0;
BA_DEF_DEF_  "VersionMonth" 0;
BA_DEF_DEF_  "VersionYear" 0;
BA_DEF_DEF_  "NmType" "Ford-OSEK";
BA_DEF_DEF_  "NmBaseAddress" 1280;
BA_DEF_DEF_  "NmMessageCount" 128;
BA_DEF_DEF_  "SystemMessageLongSymbol" "";
BA_ "VersionYear" 14;
BA_ "VersionMonth" 8;
BA_ "VersionDay" 5;
BA_ "VersionNumber" 43;
BA_ "ReleaseVersionString" "_R31j_";
BA_ "CMDB_Version" "v14.10";
BA_ "UseLegacyNames" 1;
BA_ "DBName" "INFOCAN";
BA_ "NmStationAddress" BU_ CPM 98;
BA_ "NodeLayerModules" BU_ CPM "FordAsrNM30.dll";
BA_ "BootloaderEnabled" BU_ CPM 0;
BA_ "NmAsrNodeIdentifier" BU_ CPM 226;
BA_ "NmAsrNode" BU_ CPM 1;
BA_ "PowerType" BU_ CPM 2;
BA_ "NosPackage" BU_ AHU 2;
BA_ "NmStationAddress" BU_ AHU 12;
BA_ "NmNode" BU_ AHU 1;
BA_ "NodeLayerModules" BU_ AHU "fordnm01.dll";
BA_ "BootloaderEnabled" BU_ AHU 0;
BA_ "PowerType" BU_ AHU 2;
BA_ "NmStationAddress" BU_ MFD 91;
BA_ "NodeLayerModules" BU_ MFD "FordAsrNM30.dll";
BA_ "BootloaderEnabled" BU_ MFD 0;
BA_ "NodeWakeUpTime" BU_ MFD 100;
BA_ "NmAsrNodeIdentifier" BU_ MFD 219;
BA_ "NmAsrNode" BU_ MFD 1;
BA_ "PowerType" BU_ MFD 2;
BA_ "NodeWakeUpTime" BU_ IPC 25;
BA_ "NmStationAddress" BU_ IPC 17;
BA_ "NodeLayerModules" BU_ IPC "FordAsrNM30.dll";
BA_ "BootloaderEnabled" BU_ IPC 0;
BA_ "NmAsrNodeIdentifier" BU_ IPC 145;
BA_ "NmAsrNode" BU_ IPC 1;
BA_ "PowerType" BU_ IPC 2;
BA_ "NosPackage" BU_ DSP 2;
BA_ "NmStationAddress" BU_ DSP 70;
BA_ "NodeLayerModules" BU_ DSP "FordAsrNM30.dll";
BA_ "BootloaderEnabled" BU_ DSP 0;
BA_ "NmAsrNodeIdentifier" BU_ DSP 198;
BA_ "NmAsrNode" BU_ DSP 1;
BA_ "PowerType" BU_ DSP 2;
BA_ "TpTxIndex" BO_ 597 46;
BA_ "TpTxIndex" BO_ 576 41;
BA_ "GenMsgSendType" BO_ 561 1;
BA_ "GenMsgSendType" BO_ 560 1;
BA_ "VNATransmissionType" BO_ 1210 2;
BA_ "TpTxIndex" BO_ 1210 40;
BA_ "VNATransmissionType" BO_ 1202 2;
BA_ "TpTxIndex" BO_ 1202 40;
BA_ "GenMsgSendType" BO_ 557 5;
BA_ "GenMsgCycleTime" BO_ 557 1000;
BA_ "GenMsgSendType" BO_ 1234 0;
BA_ "GenMsgCycleTime" BO_ 1234 1000;
BA_ "GenMsgSendType" BO_ 803 5;
BA_ "GenMsgCycleTime" BO_ 803 1000;
BA_ "GenMsgSendType" BO_ 1591 1;
BA_ "VNATransmissionType" BO_ 1499 2;
BA_ "NmAsrMessage" BO_ 1499 1;
BA_ "GenMsgSendType" BO_ 1499 1;
BA_ "GenMsgILSupport" BO_ 1499 0;
BA_ "GenMsgSendType" BO_ 1537 1;
BA_ "GenMsgILSupport" BO_ 1537 0;
BA_ "VNATransmissionType" BO_ 697 2;
BA_ "TpTxIndex" BO_ 697 12;
BA_ "FrameGatewayId" BO_ 995 995;
BA_ "FrameGatewayHS1" BO_ 995 995;
BA_ "FrameGatewayNetwork_OLD" BO_ 995 1;
BA_ "GenMsgSendType" BO_ 906 5;
BA_ "GenMsgCycleTime" BO_ 906 1000;
BA_ "GenMsgSendType" BO_ 991 5;
BA_ "GenMsgCycleTime" BO_ 991 1000;
BA_ "FrameGatewayId" BO_ 991 991;
BA_ "FrameGatewayHS2" BO_ 991 991;
BA_ "FrameGatewayNetwork_OLD" BO_ 991 2;
BA_ "GenMsgSendType" BO_ 845 5;
BA_ "GenMsgCycleTime" BO_ 845 1000;
BA_ "FrameGatewayId" BO_ 845 845;
BA_ "FrameGatewayMS1" BO_ 845 845;
BA_ "FrameGatewayNetwork_OLD" BO_ 845 4;
BA_ "GenMsgSendType" BO_ 844 5;
BA_ "GenMsgCycleTime" BO_ 844 1000;
BA_ "FrameGatewayId" BO_ 844 844;
BA_ "FrameGatewayMS1" BO_ 844 844;
BA_ "FrameGatewayNetwork_OLD" BO_ 844 4;
BA_ "GenMsgSendType" BO_ 850 0;
BA_ "GenMsgCycleTime" BO_ 850 500;
BA_ "FrameGatewayId" BO_ 850 850;
BA_ "FrameGatewayMS1" BO_ 850 850;
BA_ "FrameGatewayNetwork_OLD" BO_ 850 4;
BA_ "GenMsgSendType" BO_ 849 0;
BA_ "GenMsgCycleTime" BO_ 849 500;
BA_ "FrameGatewayId" BO_ 849 849;
BA_ "FrameGatewayMS1" BO_ 849 849;
BA_ "FrameGatewayNetwork_OLD" BO_ 849 4;
BA_ "GenMsgSendType" BO_ 843 0;
BA_ "GenMsgCycleTime" BO_ 843 500;
BA_ "FrameGatewayId" BO_ 843 843;
BA_ "FrameGatewayMS1" BO_ 843 843;
BA_ "FrameGatewayNetwork_OLD" BO_ 843 4;
BA_ "GenMsgSendType" BO_ 842 0;
BA_ "GenMsgCycleTime" BO_ 842 500;
BA_ "FrameGatewayId" BO_ 842 842;
BA_ "FrameGatewayMS1" BO_ 842 842;
BA_ "FrameGatewayNetwork_OLD" BO_ 842 4;
BA_ "GenMsgSendType" BO_ 135 1;
BA_ "GenMsgSendType" BO_ 1242 1;
BA_ "GenMsgSendType" BO_ 538 5;
BA_ "GenMsgCycleTime" BO_ 538 1000;
BA_ "GenMsgSendType" BO_ 801 5;
BA_ "GenMsgCycleTime" BO_ 801 1000;
BA_ "GenMsgSendType" BO_ 422 1;
BA_ "GenMsgSendType" BO_ 419 1;
BA_ "GenMsgSendType" BO_ 410 5;
BA_ "GenMsgCycleTime" BO_ 410 1000;
BA_ "GenMsgSendType" BO_ 802 5;
BA_ "GenMsgCycleTime" BO_ 802 1000;
BA_ "GenMsgSendType" BO_ 417 1;
BA_ "VNATransmissionType" BO_ 793 1;
BA_ "GenMsgSendType" BO_ 793 5;
BA_ "GenMsgCycleTime" BO_ 793 1000;
BA_ "VNATransmissionType" BO_ 753 1;
BA_ "GenMsgSendType" BO_ 753 5;
BA_ "GenMsgCycleTime" BO_ 753 1000;
BA_ "VNATransmissionType" BO_ 752 1;
BA_ "GenMsgSendType" BO_ 752 5;
BA_ "GenMsgCycleTime" BO_ 752 1000;
BA_ "GenMsgSendType" BO_ 359 0;
BA_ "GenMsgCycleTime" BO_ 359 100;
BA_ "FrameGatewayId" BO_ 359 359;
BA_ "FrameGatewayHS1" BO_ 359 359;
BA_ "FrameGatewayNetwork_OLD" BO_ 359 1;
BA_ "GenMsgSendType" BO_ 516 0;
BA_ "GenMsgCycleTime" BO_ 516 10;
BA_ "FrameGatewayId" BO_ 516 516;
BA_ "FrameGatewayHS1" BO_ 516 516;
BA_ "FrameGatewayNetwork_OLD" BO_ 516 1;
BA_ "VNATransmissionType" BO_ 687 2;
BA_ "TpTxIndex" BO_ 687 35;
BA_ "GenMsgSendType" BO_ 754 5;
BA_ "GenMsgCycleTime" BO_ 754 1000;
BA_ "TpTxIndex" BO_ 711 24;
BA_ "GenMsgSendType" BO_ 391 1;
BA_ "GenMsgSendType" BO_ 393 1;
BA_ "GenMsgSendType" BO_ 406 1;
BA_ "GenMsgSendType" BO_ 409 1;
BA_ "VNATransmissionType" BO_ 717 2;
BA_ "TpTxIndex" BO_ 717 39;
BA_ "GenMsgSendType" BO_ 408 1;
BA_ "GenMsgSendType" BO_ 407 1;
BA_ "GenMsgSendType" BO_ 1003 5;
BA_ "GenMsgCycleTime" BO_ 1003 1000;
BA_ "GenMsgSendType" BO_ 675 5;
BA_ "GenMsgCycleTime" BO_ 675 1000;
BA_ "GenMsgSendType" BO_ 263 1;
BA_ "GenMsgSendType" BO_ 262 1;
BA_ "VNATransmissionType" BO_ 534 1;
BA_ "GenMsgSendType" BO_ 534 5;
BA_ "GenMsgCycleTime" BO_ 534 1000;
BA_ "FrameGatewayId" BO_ 534 534;
BA_ "FrameGatewayHS2" BO_ 534 534;
BA_ "FrameGatewayNetwork_OLD" BO_ 534 2;
BA_ "VNATransmissionType" BO_ 656 1;
BA_ "GenMsgSendType" BO_ 656 5;
BA_ "GenMsgCycleTime" BO_ 656 200;
BA_ "VNATransmissionType" BO_ 1008 1;
BA_ "GenMsgSendType" BO_ 1008 5;
BA_ "GenMsgCycleTime" BO_ 1008 1000;
BA_ "VNATransmissionType" BO_ 404 1;
BA_ "GenMsgSendType" BO_ 404 1;
BA_ "VNATransmissionType" BO_ 291 1;
BA_ "GenMsgSendType" BO_ 291 1;
BA_ "VNATransmissionType" BO_ 493 1;
BA_ "GenMsgSendType" BO_ 493 1;
BA_ "VNATransmissionType" BO_ 708 2;
BA_ "TpTxIndex" BO_ 708 33;
BA_ "DiagRequest" BO_ 1959 1;
BA_ "VNATransmissionType" BO_ 1959 2;
BA_ "GenMsgSendType" BO_ 1959 1;
BA_ "GenMsgDelayTime" BO_ 1959 0;
BA_ "GenMsgILSupport" BO_ 1959 0;
BA_ "TpMessage" BO_ 1959 1;
BA_ "GenMsgIlSupport" BO_ 1959 0;
BA_ "VNATransmissionType" BO_ 402 1;
BA_ "GenMsgSendType" BO_ 402 5;
BA_ "GenMsgCycleTime" BO_ 402 1000;
BA_ "GenMsgSendType" BO_ 265 5;
BA_ "GenMsgCycleTime" BO_ 265 1000;
BA_ "GenMsgDelayTime" BO_ 265 100;
BA_ "VNATransmissionType" BO_ 709 2;
BA_ "GenMsgStartDelayTime" BO_ 709 150;
BA_ "TpTxIndex" BO_ 709 25;
BA_ "VNATransmissionType" BO_ 706 2;
BA_ "TpTxIndex" BO_ 706 28;
BA_ "VNATransmissionType" BO_ 713 2;
BA_ "TpTxIndex" BO_ 713 27;
BA_ "VNATransmissionType" BO_ 705 2;
BA_ "TpTxIndex" BO_ 705 27;
BA_ "VNATransmissionType" BO_ 707 2;
BA_ "TpTxIndex" BO_ 707 23;
BA_ "DiagRequest" BO_ 1923 1;
BA_ "VNATransmissionType" BO_ 1923 2;
BA_ "GenMsgSendType" BO_ 1923 1;
BA_ "GenMsgDelayTime" BO_ 1923 0;
BA_ "GenMsgILSupport" BO_ 1923 0;
BA_ "GenMsgIlSupport" BO_ 1923 0;
BA_ "TpMessage" BO_ 1923 1;
BA_ "VNATransmissionType" BO_ 758 1;
BA_ "GenMsgSendType" BO_ 758 5;
BA_ "GenMsgCycleTime" BO_ 758 1000;
BA_ "VNATransmissionType" BO_ 761 1;
BA_ "GenMsgSendType" BO_ 761 5;
BA_ "GenMsgCycleTime" BO_ 761 1000;
BA_ "VNATransmissionType" BO_ 760 1;
BA_ "GenMsgSendType" BO_ 760 5;
BA_ "GenMsgCycleTime" BO_ 760 1000;
BA_ "VNATransmissionType" BO_ 260 1;
BA_ "GenMsgSendType" BO_ 260 1;
BA_ "VNATransmissionType" BO_ 259 1;
BA_ "GenMsgSendType" BO_ 259 1;
BA_ "VNATransmissionType" BO_ 759 1;
BA_ "GenMsgSendType" BO_ 759 5;
BA_ "GenMsgCycleTime" BO_ 759 1000;
BA_ "GenMsgSendType" BO_ 947 5;
BA_ "GenMsgCycleTime" BO_ 947 1000;
BA_ "VNATransmissionType" BO_ 129 1;
BA_ "GenMsgSendType" BO_ 129 5;
BA_ "GenMsgCycleTime" BO_ 129 1000;
BA_ "FrameGatewayId" BO_ 129 129;
BA_ "FrameGatewayHS2" BO_ 129 129;
BA_ "FrameGatewayNetwork_OLD" BO_ 129 2;
BA_ "VNATransmissionType" BO_ 855 1;
BA_ "FrameGateway_nonCGEA" BO_ 855 855;
BA_ "GenMsgSendType" BO_ 855 5;
BA_ "GenMsgCycleTime" BO_ 855 1000;
BA_ "VNATransmissionType" BO_ 856 1;
BA_ "FrameGateway_nonCGEA" BO_ 856 856;
BA_ "GenMsgSendType" BO_ 856 5;
BA_ "GenMsgCycleTime" BO_ 856 1000;
BA_ "VNASignalName" SG_ 597 AUDIO_RSE_WORD_Tx "AUDIO_RDISP_WORD_Tx_I";
BA_ "VNASignalName" SG_ 576 AUDIO_RDISP2_WORD_Tx "AUDIO_RDISP_WORD_Tx_I";
BA_ "GenSigSendType" SG_ 561 Vr_SetCurrTUPreset_Rq 3;
BA_ "GenSigSendType" SG_ 561 Vr_SetCurrTUBand_Rq 3;
BA_ "InvalidHex" SG_ 561 Vr_SetCurrentStatFreq_Rq "$7FF";
BA_ "GenSigSendType" SG_ 561 Vr_SetCurrentStatOp_Rq 3;
BA_ "GenSigStartValue" SG_ 561 Vr_SDARS_DirectTune_Rq 255;
BA_ "GenSigSendType" SG_ 561 Vr_SDARS_DirectTune_Rq 3;
BA_ "InvalidHex" SG_ 560 Vr_SourceSetTrack_Rq "$0000";
BA_ "InvalidHex" SG_ 560 Vr_FolderNumber_Rq "$FFFF";
BA_ "GenSigSendType" SG_ 560 Vr_AudioSourceSel_Rq 3;
BA_ "GenSigSendType" SG_ 560 Vr_SkipTrack_Rq 3;
BA_ "GenSigSendType" SG_ 560 Vr_SetOperationMode_Rq 3;
BA_ "GenSigSendType" SG_ 560 Vr_CDSetShuffle_Rq 3;
BA_ "GenSigSendType" SG_ 560 Vr_CDSetRepeat_Rq 3;
BA_ "GenSigSendType" SG_ 557 Con_MediaSrc16_St 3;
BA_ "GenSigSendType" SG_ 557 Con_MediaSrc15_St 3;
BA_ "GenSigSendType" SG_ 557 Con_MediaSrc14_St 3;
BA_ "GenSigSendType" SG_ 557 Con_MediaSrc13_St 3;
BA_ "GenSigSendType" SG_ 557 Con_MediaSrc12_St 3;
BA_ "GenSigSendType" SG_ 557 Con_MediaSrc11_St 3;
BA_ "GenSigSendType" SG_ 557 Con_MediaSrc10_St 3;
BA_ "GenSigSendType" SG_ 557 Con_MediaSrc9_St 3;
BA_ "GenSigSendType" SG_ 557 Con_MediaSrc8_St 3;
BA_ "GenSigSendType" SG_ 557 Con_MediaSrc7_St 3;
BA_ "GenSigSendType" SG_ 557 Con_MediaSrc6_St 3;
BA_ "GenSigSendType" SG_ 557 Con_MediaSrc5_St 3;
BA_ "GenSigSendType" SG_ 557 Con_MediaSrc4_St 3;
BA_ "GenSigSendType" SG_ 557 Con_MediaSrc3_St 3;
BA_ "GenSigSendType" SG_ 557 Con_MediaSrc2_St 3;
BA_ "GenSigSendType" SG_ 557 Con_MediaSrc1_St 3;
BA_ "FISI_Comment_Sig" SG_ 531 PrkBrkMsgTxt_D_Rq "Do not use the SGW interface in 0x431! Use FGW 0x213 instead!";
BA_ "HS3_Category" SG_ 531 PrkBrkMsgTxt_D_Rq 4;
BA_ "FISI_Comment_Sig" SG_ 531 PrkBrkYwLamp_D_Rq "Do not use the SGW interface in 0x431! Use FGW 0x213 instead!";
BA_ "HS3_Category" SG_ 531 PrkBrkYwLamp_D_Rq 4;
BA_ "FISI_Comment_Sig" SG_ 531 PrkBrkRedLamp_D_Rq "Do not use the SGW interface in 0x431! Use FGW 0x213 instead!";
BA_ "HS3_Category" SG_ 531 PrkBrkRedLamp_D_Rq 4;
BA_ "GenSigStartValue" SG_ 531 VehLongOvrGnd_A_Est 511;
BA_ "GenSigSendType" SG_ 803 CNG_LowFuel_792 3;
BA_ "GenSigSendType" SG_ 803 CNG_Malfunction_793 3;
BA_ "GenSigSendType" SG_ 803 CNG_CNGMode_794 3;
BA_ "GenSigSendType" SG_ 803 CNG_GasMode_795 3;
BA_ "GenSigSendType" SG_ 803 LowOilLevel_254 3;
BA_ "GenSigSendType" SG_ 1591 DevID_IPC_Tx2_i 3;
BA_ "GenSigSendType" SG_ 1499 FCDIM_AutoSar_NetworkMgmt 3;
BA_ "GenSigSendType" SG_ 1537 DevID_IPC_Tx1_i 3;
BA_ "GenSigStartValue" SG_ 995 PersIndexBcm_D_Actl 4;
BA_ "FISI_Comment_Sig" SG_ 906 CcdMsgTxt_D_RqDsply_UB "UB";
BA_ "GenSigSendType" SG_ 906 CcdMsgTxt_D_RqDsply 3;
BA_ "GenSigSendType" SG_ 906 SlMde_D_RqDsply 3;
BA_ "GenSigSendType" SG_ 906 IsaOffst_D_Stat 3;
BA_ "GenSigSendType" SG_ 906 SlMde_D_Stat 3;
BA_ "FISI_Comment_Sig" SG_ 906 SlMde_D_RqDsply_UB "UB";
BA_ "FISI_Comment_Sig" SG_ 906 ApaChime_D_Rq_UB "UB";
BA_ "GenSigSendType" SG_ 906 ApaChime_D_Rq 3;
BA_ "FISI_Comment_Sig" SG_ 906 MemDrvDeny_B_Stat_UB "UB";
BA_ "GenSigSendType" SG_ 906 MemDrvDeny_B_Stat 3;
BA_ "FISI_Comment_Sig" SG_ 906 BrkDrvMde_D_Stat_UB "UB";
BA_ "GenSigSendType" SG_ 906 BrkDrvMde_D_Stat 3;
BA_ "FISI_Comment_Sig" SG_ 906 HeadLghtHiOn_B_StatHcm_UB "UB";
BA_ "GenSigSendType" SG_ 906 HeadLghtHiOn_B_StatHcm 3;
BA_ "GenSigSendType" SG_ 906 Running_Board_Stat 3;
BA_ "GenSigSendType" SG_ 906 PrkLckCtlUnlck_D_Stat 3;
BA_ "GenSigSendType" SG_ 906 PrkLckCtlTow_B_Enbl 3;
BA_ "GenSigSendType" SG_ 906 DrTgateChime2_D_Rq 3;
BA_ "FISI_Comment_Sig" SG_ 906 TurnLghtSwtch_D_Stat_UB "UB";
BA_ "GenSigSendType" SG_ 906 TurnLghtSwtch_D_Stat 3;
BA_ "WakeupSignal" SG_ 906 TurnLghtSwtch_D_Stat 1;
BA_ "FISI_Comment_Sig" SG_ 906 Adaptive_Hdlmp_Fault_UB "UB";
BA_ "FISI_Comment_Sig" SG_ 906 Memory_Feedback_Rqst_UB "UB";
BA_ "FISI_Comment_Sig" SG_ 906 PrkLckCtl_B_Enbl_UB "UB";
BA_ "GenSigSendType" SG_ 906 PrkLckCtl_B_Enbl 3;
BA_ "FISI_Comment_Sig" SG_ 906 PrkLckCtlMsgTxt_D_Rq_UB "UB";
BA_ "GenSigSendType" SG_ 906 PrkLckCtlMsgTxt_D_Rq 3;
BA_ "WakeupSignal" SG_ 906 PrkLckCtlMsgTxt_D_Rq 1;
BA_ "FISI_Comment_Sig" SG_ 906 PrkLckCtlAvail_T_Stat_UB "UB";
BA_ "GenSigSendType" SG_ 906 PrkLckCtlAvail_T_Stat 3;
BA_ "WakeupSignal" SG_ 906 PrkLckCtlAvail_T_Stat 1;
BA_ "FISI_Comment_Sig" SG_ 906 DrTgateChime2_D_Rq_UB "UB";
BA_ "FISI_Comment_Sig" SG_ 906 GearLvrPos_D_Actl_UB "UB";
BA_ "FISI_Comment_Sig" SG_ 906 Power_Liftgate_Mode_Stt_UB "UB";
BA_ "GenSigSendType" SG_ 906 Adaptive_Hdlmp_Fault 3;
BA_ "GenSigSendType" SG_ 906 Power_Liftgate_Mode_Stt 3;
BA_ "GenSigSendType" SG_ 906 Memory_Feedback_Rqst 3;
BA_ "WakeupSignal" SG_ 906 Memory_Feedback_Rqst 1;
BA_ "GenSigSendType" SG_ 906 GearLvrPos_D_Actl 3;
BA_ "GenSigStartValue" SG_ 991 PersIndexVdm_D_Actl 4;
BA_ "GenSigSendType" SG_ 991 PersIndexVdm_D_Actl 3;
BA_ "GenSigSendType" SG_ 991 FeatNoVdmActl 3;
BA_ "GenSigSendType" SG_ 991 FeatConfigVdmActl 3;
BA_ "GenSigSendType" SG_ 845 StmsLmbrPsgr_D_Stat 3;
BA_ "GenSigSendType" SG_ 845 StmsCshnPsgr_D_Stat 3;
BA_ "GenSigSendType" SG_ 845 SeatSwtchPsgr_B_Stat 3;
BA_ "GenSigSendType" SG_ 845 SeatPPsgr_B_Stat 3;
BA_ "GenSigSendType" SG_ 845 SeatFnPsgr_D_Stat 3;
BA_ "GenSigSendType" SG_ 845 PsgrMemFeedback_Rsp 3;
BA_ "GenSigSendType" SG_ 844 StmsLmbrDrv_D_Stat 3;
BA_ "GenSigSendType" SG_ 844 StmsCshnDrv_D_Stat 3;
BA_ "GenSigSendType" SG_ 844 SeatSwtchDrv_B_Stat 3;
BA_ "GenSigSendType" SG_ 844 SeatFnDrv_D_Stat 3;
BA_ "GenSigSendType" SG_ 844 SeatAirAmb_P_Actl 3;
BA_ "GenSigSendType" SG_ 844 SeatPDrv_B_Stat 3;
BA_ "GenSigStartValue" SG_ 850 SeatBlLoPsgr_Pc_Actl2 127;
BA_ "GenSigStartValue" SG_ 850 SeatCshnPsgrRR_Pc_Actl 127;
BA_ "GenSigStartValue" SG_ 850 SeatCshnPsgrRL_Pc_Actl 127;
BA_ "GenSigStartValue" SG_ 850 SeatCshnPsgrFR_Pc_Actl 127;
BA_ "GenSigStartValue" SG_ 850 SeatCshnPsgrFL_Pc_Actl 127;
BA_ "GenSigStartValue" SG_ 849 SeatCshnDrvRR_Pc_Actl 127;
BA_ "GenSigStartValue" SG_ 849 SeatCshnDrvRL_Pc_Actl 127;
BA_ "GenSigStartValue" SG_ 849 SeatCshnDrvFR_Pc_Actl 127;
BA_ "GenSigStartValue" SG_ 849 SeatCshnDrvFL_Pc_Actl 127;
BA_ "GenSigStartValue" SG_ 843 SeatBlUpPsgr_Pc_Actl 127;
BA_ "GenSigStartValue" SG_ 843 SeatBlLoPsgr_Pc_Actl 127;
BA_ "GenSigStartValue" SG_ 842 SeatBlUpDrv_Pc_Actl 127;
BA_ "GenSigStartValue" SG_ 842 SeatBlLoDrv_Pc_Actl 127;
BA_ "WakeupSignal" SG_ 135 McGlblClkDay_No_Rq 1;
BA_ "WakeupSignal" SG_ 135 McGlblClkYr_No_Rq 1;
BA_ "WakeupSignal" SG_ 135 McGlblClkScnd_No_Rq 1;
BA_ "WakeupSignal" SG_ 135 McGlblClkMnte_No_Rq 1;
BA_ "WakeupSignal" SG_ 135 McGlblClkHr_No_Rq 1;
BA_ "GenSigSendType" SG_ 135 McGlblClkAdj_B_Rq 3;
BA_ "WakeupSignal" SG_ 135 McGlblClkAdj_B_Rq 1;
BA_ "GenSigSendType" SG_ 1242 DimmerHMISrcStatus 1;
BA_ "GenSigSendType" SG_ 1242 ALSCfgStatus 1;
BA_ "GenSigSendType" SG_ 538 MK_AudioLimitConfig_St 3;
BA_ "GenSigSendType" SG_ 538 MK_AdminMyKeyCount_St 3;
BA_ "GenSigSendType" SG_ 538 MK_UserMyKeyCount_St 3;
BA_ "GenSigSendType" SG_ 538 MK_SpeedMinderConf_St 3;
BA_ "GenSigSendType" SG_ 538 MK_SpeedLimitConf_St 3;
BA_ "GenSigSendType" SG_ 538 MK_ESCRestrictConf_St 3;
BA_ "GenSigSendType" SG_ 538 MK_ECalRestrictConf_St 3;
BA_ "GenSigSendType" SG_ 538 MK_DNDRestrictConf_St 3;
BA_ "GenSigSendType" SG_ 538 MK_ACSRestrictConf_St 3;
BA_ "GenSigSendType" SG_ 801 SoftWarning 3;
BA_ "GenSigSendType" SG_ 801 InfoWarning 3;
BA_ "GenSigSendType" SG_ 801 HardWarning 3;
BA_ "InvalidHex" SG_ 422 MK_MyKeyDrivenKm_Rsp "$FFFFF";
BA_ "GenSigSendType" SG_ 422 MK_MyKeyDrivenKm_Rsp 3;
BA_ "GenSigSendType" SG_ 422 MK_AdminMyKeyCount_Rsp 3;
BA_ "GenSigSendType" SG_ 422 MK_UserMyKeyCount_Rsp 3;
BA_ "GenSigSendType" SG_ 422 MK_CreateMyKey_Rsp 3;
BA_ "GenSigSendType" SG_ 419 MK_SpeedSetting_Rq 3;
BA_ "GenSigSendType" SG_ 419 MK_ResetAllUserKeys_Rq 3;
BA_ "GenSigSendType" SG_ 419 MK_MyKeySystemInfo_Rq 3;
BA_ "GenSigSendType" SG_ 419 MK_ESCRestrictConf_Rq 3;
BA_ "GenSigSendType" SG_ 419 MK_ECalRestrictConf_Rq 3;
BA_ "GenSigSendType" SG_ 419 MK_DNDRestrictConf_Rq 3;
BA_ "GenSigSendType" SG_ 419 MK_CreateMyKey_Rq 3;
BA_ "GenSigSendType" SG_ 419 MK_AudioLimitConfig_Rq 3;
BA_ "GenSigSendType" SG_ 419 MK_ACSRestrictConf_Rq 3;
BA_ "GenSigSendType" SG_ 410 AugustReport_St 3;
BA_ "GenSigSendType" SG_ 410 AprilReport_St 3;
BA_ "GenSigSendType" SG_ 410 SeptemberReport_St 3;
BA_ "GenSigSendType" SG_ 410 ReportCardOnOff_St 3;
BA_ "GenSigSendType" SG_ 410 OctoberReport_St 3;
BA_ "GenSigSendType" SG_ 410 NovemberReport_St 3;
BA_ "GenSigSendType" SG_ 410 MayReport_St 3;
BA_ "GenSigSendType" SG_ 410 MarchReport_St 3;
BA_ "GenSigSendType" SG_ 410 JuneReport_St 3;
BA_ "GenSigSendType" SG_ 410 JulyReport_St 3;
BA_ "GenSigSendType" SG_ 410 JanuaryReport_St 3;
BA_ "GenSigSendType" SG_ 410 FebruaryReport_St 3;
BA_ "GenSigSendType" SG_ 410 DecemberReport_St 3;
BA_ "GenSigSendType" SG_ 410 ClusterMajorUnits_St 3;
BA_ "GenSigSendType" SG_ 410 MyKey_e911Override_St 3;
BA_ "GenSigSendType" SG_ 410 DoNotDisturbOveride_St 3;
BA_ "GenSigSendType" SG_ 802 DISP_PowerFoldMirrorSt 3;
BA_ "GenSigSendType" SG_ 802 DISP_MPH_KPH 3;
BA_ "GenSigSendType" SG_ 802 DISP_MoodLightSt 3;
BA_ "GenSigSendType" SG_ 802 DISP_LaneChangingInd 3;
BA_ "GenSigSendType" SG_ 802 DISP_ChimesSt 3;
BA_ "GenSigSendType" SG_ 417 SetAlarmAskOnExitSetting_Rq 3;
BA_ "GenSigSendType" SG_ 417 SetAlarmMode_Rq 3;
BA_ "GenSigSendType" SG_ 417 VS_SetLaneChangeInd_Rq 3;
BA_ "GenSigSendType" SG_ 417 VS_SetPowFolMirMode_Rq 3;
BA_ "GenSigSendType" SG_ 417 VS_SetMoodLight_Rq 3;
BA_ "GenSigSendType" SG_ 417 VS_DeflDetSysInit_Rq 3;
BA_ "GenSigSendType" SG_ 417 VS_SetESPMode_Rq 3;
BA_ "GenSigSendType" SG_ 417 VS_HSAMde_D_Rq 3;
BA_ "GenSigSendType" SG_ 417 VS_LowSpeedCMbB_Rq 3;
BA_ "GenSigSendType" SG_ 417 PrkLckCtlEnbl_D_Rq 3;
BA_ "GenSigSendType" SG_ 417 SetRainSensorMode_Rq 3;
BA_ "GenSigSendType" SG_ 417 TirePReset_B_Rq 3;
BA_ "GenSigSendType" SG_ 793 EngineOn_98 3;
BA_ "FISI_Comment_Sig" SG_ 793 Soot_DPFSootLevel2_578 "*";
BA_ "GenSigSendType" SG_ 793 Soot_DPFSootLevel2_578 3;
BA_ "FISI_Comment_Sig" SG_ 793 Soot_DPFRegen_537 "*";
BA_ "GenSigSendType" SG_ 793 Soot_DPFRegen_537 3;
BA_ "FISI_Comment_Sig" SG_ 793 Soot_DPFRegen_536 "*";
BA_ "GenSigSendType" SG_ 793 Soot_DPFRegen_536 3;
BA_ "FISI_Comment_Sig" SG_ 793 TopSpeedInfo_666 "*";
BA_ "GenSigSendType" SG_ 793 TopSpeedInfo_666 3;
BA_ "FISI_Comment_Sig" SG_ 793 Headlamp_Failure_430 "*";
BA_ "GenSigSendType" SG_ 793 Headlamp_Failure_430 3;
BA_ "FISI_Comment_Sig" SG_ 793 ParkBrake_Hard_626 "*";
BA_ "GenSigSendType" SG_ 793 ParkBrake_Hard_626 3;
BA_ "FISI_Comment_Sig" SG_ 793 ParkBrake_Soft_625 "*";
BA_ "GenSigSendType" SG_ 793 ParkBrake_Soft_625 3;
BA_ "FISI_Comment_Sig" SG_ 793 TPMS_NotTraiRepeat_969 "*";
BA_ "GenSigSendType" SG_ 793 TPMS_NotTraiRepeat_969 3;
BA_ "FISI_Comment_Sig" SG_ 793 TPMS_TrainingCompl_968 "*";
BA_ "GenSigSendType" SG_ 793 TPMS_TrainingCompl_968 3;
BA_ "FISI_Comment_Sig" SG_ 793 TPMS_TraiInLeRear_967 "*";
BA_ "GenSigSendType" SG_ 793 TPMS_TraiInLeRear_967 3;
BA_ "FISI_Comment_Sig" SG_ 793 TPMS_TraiOutLeRear_966 "*";
BA_ "GenSigSendType" SG_ 793 TPMS_TraiOutLeRear_966 3;
BA_ "FISI_Comment_Sig" SG_ 793 TPMS_TrainLeftRear_965 "*";
BA_ "GenSigSendType" SG_ 793 TPMS_TrainLeftRear_965 3;
BA_ "FISI_Comment_Sig" SG_ 793 TPMS_TraiInRiRear_964 "*";
BA_ "GenSigSendType" SG_ 793 TPMS_TraiInRiRear_964 3;
BA_ "FISI_Comment_Sig" SG_ 793 TPMS_TraiOutRiRear_963 "*";
BA_ "GenSigSendType" SG_ 793 TPMS_TraiOutRiRear_963 3;
BA_ "FISI_Comment_Sig" SG_ 793 TPMS_TraiRiRear_962 "*";
BA_ "GenSigSendType" SG_ 793 TPMS_TraiRiRear_962 3;
BA_ "FISI_Comment_Sig" SG_ 793 TPMS_TraiRiFront_961 "*";
BA_ "GenSigSendType" SG_ 793 TPMS_TraiRiFront_961 3;
BA_ "FISI_Comment_Sig" SG_ 793 TPMS_TraiLeftFront_960 "*";
BA_ "GenSigSendType" SG_ 793 TPMS_TraiLeftFront_960 3;
BA_ "FISI_Comment_Sig" SG_ 793 TPMS_GlobalWarning_493 "*";
BA_ "GenSigSendType" SG_ 793 TPMS_GlobalWarning_493 3;
BA_ "FISI_Comment_Sig" SG_ 793 TPMS_NoSensors_474 "*";
BA_ "GenSigSendType" SG_ 793 TPMS_NoSensors_474 3;
BA_ "FISI_Comment_Sig" SG_ 793 TPMS_Malfunction_400 "*";
BA_ "GenSigSendType" SG_ 793 TPMS_Malfunction_400 3;
BA_ "FISI_Comment_Sig" SG_ 793 PAHWSwitchOffIn_671 "*";
BA_ "GenSigSendType" SG_ 793 PAHWSwitchOffIn_671 3;
BA_ "FISI_Comment_Sig" SG_ 793 ESCHWSwitchOffIn_676 "*";
BA_ "GenSigSendType" SG_ 793 ESCHWSwitchOffIn_676 3;
BA_ "FISI_Comment_Sig" SG_ 793 SpeedMinder_665 "*";
BA_ "GenSigSendType" SG_ 793 SpeedMinder_665 3;
BA_ "FISI_Comment_Sig" SG_ 793 MyKeyActive_660 "*";
BA_ "GenSigSendType" SG_ 793 MyKeyActive_660 3;
BA_ "FISI_Comment_Sig" SG_ 793 SpeedLimitIndic_661 "*";
BA_ "GenSigSendType" SG_ 793 SpeedLimitIndic_661 3;
BA_ "FISI_Comment_Sig" SG_ 793 SpeedLimitInfo_667 "*";
BA_ "GenSigSendType" SG_ 793 SpeedLimitInfo_667 3;
BA_ "GenSigSendType" SG_ 793 Point_Highspeed 3;
BA_ "GenSigSendType" SG_ 793 Point_Gearshift 3;
BA_ "GenSigSendType" SG_ 793 Point_Anticip 3;
BA_ "GenSigSendType" SG_ 793 I_highspeed 3;
BA_ "GenSigSendType" SG_ 793 I_gearshift 3;
BA_ "GenSigSendType" SG_ 793 I_anticip 3;
BA_ "InvalidHex" SG_ 793 Pcnt_EngineColdTrips "$7F";
BA_ "GenSigSendType" SG_ 793 Pcnt_EngineColdTrips 3;
BA_ "GenSigSendType" SG_ 793 OTIS_PressBAndC_657 3;
BA_ "GenSigSendType" SG_ 793 OTIS_PressBrake_655 3;
BA_ "GenSigSendType" SG_ 793 OTIS_PressClutch_656 3;
BA_ "GenSigSendType" SG_ 793 LSSS_PostIncident_710 3;
BA_ "GenSigSendType" SG_ 793 LSSS_Malfunction_712 3;
BA_ "GenSigSendType" SG_ 793 LSSS_CleanSensor_711 3;
BA_ "GenSigSendType" SG_ 793 DDS_PressureWarning_512 3;
BA_ "GenSigSendType" SG_ 793 DDS_Unavailable_513 3;
BA_ "GenSigSendType" SG_ 793 ECOADVICE4 3;
BA_ "GenSigSendType" SG_ 793 ECOADVICE3 3;
BA_ "GenSigSendType" SG_ 793 ECOADVICE2 3;
BA_ "GenSigSendType" SG_ 793 ECOADVICE1 3;
BA_ "FISI_Comment_Sig" SG_ 793 BTSI_MORShiftNotIP_752 "*";
BA_ "GenSigSendType" SG_ 793 BTSI_MORShiftNotIP_752 3;
BA_ "FISI_Comment_Sig" SG_ 793 BTSI_MORShiftUnloc_751 "*";
BA_ "GenSigSendType" SG_ 793 BTSI_MORShiftUnloc_751 3;
BA_ "FISI_Comment_Sig" SG_ 793 BTSI_MORPreBraToUn_750 "*";
BA_ "GenSigSendType" SG_ 793 BTSI_MORPreBraToUn_750 3;
BA_ "GenSigSendType" SG_ 793 OTIS_StartOvrheat_658 3;
BA_ "GenSigSendType" SG_ 793 ECSS_StartPdgWait_790 3;
BA_ "GenSigSendType" SG_ 793 ECSS_PendingStart_791 3;
BA_ "GenSigSendType" SG_ 753 AlarmPopUp_St 3;
BA_ "GenSigSendType" SG_ 753 AlarmMode_St 3;
BA_ "GenSigSendType" SG_ 753 AlarmAskOnExitSetting_St 3;
BA_ "GenSigSendType" SG_ 753 VS_WiperStalkRotat_St 3;
BA_ "GenSigSendType" SG_ 753 VS_WiperStalkPos_St 3;
BA_ "GenSigSendType" SG_ 753 VS_RainSensorMode_St 3;
BA_ "GenSigSendType" SG_ 753 VS_LaneChangIndMode_St 3;
BA_ "GenSigSendType" SG_ 753 VS_HSAMde_D_Mem_St 3;
BA_ "GenSigSendType" SG_ 753 VS_PowFolMirMode_St 3;
BA_ "GenSigSendType" SG_ 753 VS_LscmbbOnOff_D_St 3;
BA_ "GenSigSendType" SG_ 753 VS_MoodLightMode_St 3;
BA_ "GenSigSendType" SG_ 753 VS_StabilityControl_St 3;
BA_ "GenSigSendType" SG_ 753 StopStartMsg_OnDemand_St 3;
BA_ "FISI_Comment_Sig" SG_ 753 DeflDetSysStatus "*";
BA_ "GenSigSendType" SG_ 753 DeflDetSysStatus 3;
BA_ "GenSigSendType" SG_ 753 VS_ESPLongPress_St 3;
BA_ "GenSigSendType" SG_ 753 PrkLckCtl_B_Enbl_St 3;
BA_ "GenSigSendType" SG_ 753 PrkLckCtl_B_Allow_St 3;
BA_ "FISI_Comment_Sig" SG_ 753 TirePReset_D_Stat "Do not use the SGW interface in 0x2F1! Use FGW 0x3B4 instead!";
BA_ "HS3_Category" SG_ 753 TirePReset_D_Stat 4;
BA_ "GenSigSendType" SG_ 753 TirePReset_D_Stat 3;
BA_ "FISI_Comment_Sig" SG_ 752 TransmDIWarnMsg3 "*";
BA_ "GenSigSendType" SG_ 752 TransmDIWarnMsg3 3;
BA_ "FISI_Comment_Sig" SG_ 752 HillStartAssistOffWOChime_428 "*";
BA_ "GenSigSendType" SG_ 752 HillStartAssistOffWOChime_428 3;
BA_ "FISI_Comment_Sig" SG_ 752 HillStartAssistOffWChime_582 "*";
BA_ "GenSigSendType" SG_ 752 HillStartAssistOffWChime_582 3;
BA_ "FISI_Comment_Sig" SG_ 752 HillStartAssistNotAvailable_429 "*";
BA_ "GenSigSendType" SG_ 752 HillStartAssistNotAvailable_429 3;
BA_ "FISI_Comment_Sig" SG_ 752 HillStartAssistActive_427 "*";
BA_ "GenSigSendType" SG_ 752 HillStartAssistActive_427 3;
BA_ "FISI_Comment_Sig" SG_ 752 PJB_TriggCause_419 "*";
BA_ "GenSigSendType" SG_ 752 PJB_TriggCause_419 3;
BA_ "FISI_Comment_Sig" SG_ 752 AlarmServicerequired_476 "*";
BA_ "GenSigSendType" SG_ 752 AlarmServicerequired_476 3;
BA_ "FISI_Comment_Sig" SG_ 752 PassengerDoorStatus2_214 "*";
BA_ "GenSigSendType" SG_ 752 PassengerDoorStatus2_214 3;
BA_ "FISI_Comment_Sig" SG_ 752 DriverDoorStatus2_212 "*";
BA_ "GenSigSendType" SG_ 752 DriverDoorStatus2_212 3;
BA_ "FISI_Comment_Sig" SG_ 752 EpasFailed_258 "*";
BA_ "GenSigSendType" SG_ 752 EpasFailed_258 3;
BA_ "FISI_Comment_Sig" SG_ 752 ToStartPressBrake_485 "*";
BA_ "GenSigSendType" SG_ 752 ToStartPressBrake_485 3;
BA_ "FISI_Comment_Sig" SG_ 752 ToStartPressNeutral_744 "*";
BA_ "GenSigSendType" SG_ 752 ToStartPressNeutral_744 3;
BA_ "FISI_Comment_Sig" SG_ 752 ToStartPressBrake_749 "*";
BA_ "GenSigSendType" SG_ 752 ToStartPressBrake_749 3;
BA_ "FISI_Comment_Sig" SG_ 752 NotInPark_745 "*";
BA_ "GenSigSendType" SG_ 752 NotInPark_745 3;
BA_ "FISI_Comment_Sig" SG_ 752 DoorOpenNotInPark_488 "*";
BA_ "GenSigSendType" SG_ 752 DoorOpenNotInPark_488 3;
BA_ "FISI_Comment_Sig" SG_ 752 KVM_Service_567 "*";
BA_ "GenSigSendType" SG_ 752 KVM_Service_567 3;
BA_ "FISI_Comment_Sig" SG_ 752 CloseBootUseSpareKey_501 "*";
BA_ "GenSigSendType" SG_ 752 CloseBootUseSpareKey_501 3;
BA_ "FISI_Comment_Sig" SG_ 752 SCLFailureIndTorqued_500 "*";
BA_ "GenSigSendType" SG_ 752 SCLFailureIndTorqued_500 3;
BA_ "FISI_Comment_Sig" SG_ 752 SCLFailureIndStop_495 "*";
BA_ "GenSigSendType" SG_ 752 SCLFailureIndStop_495 3;
BA_ "FISI_Comment_Sig" SG_ 752 SCLFailureIndSERVICE_494 "*";
BA_ "GenSigSendType" SG_ 752 SCLFailureIndSERVICE_494 3;
BA_ "FISI_Comment_Sig" SG_ 752 PKOutOfVehicle_498 "*";
BA_ "GenSigSendType" SG_ 752 PKOutOfVehicle_498 3;
BA_ "FISI_Comment_Sig" SG_ 752 PKNotDetected_496 "*";
BA_ "GenSigSendType" SG_ 752 PKNotDetected_496 3;
BA_ "FISI_Comment_Sig" SG_ 752 HigherPowerMode_497 "*";
BA_ "GenSigSendType" SG_ 752 HigherPowerMode_497 3;
BA_ "FISI_Comment_Sig" SG_ 752 PressClutch_502 "*";
BA_ "GenSigSendType" SG_ 752 PressClutch_502 3;
BA_ "FISI_Comment_Sig" SG_ 752 PressBrake_499 "*";
BA_ "GenSigSendType" SG_ 752 PressBrake_499 3;
BA_ "FISI_Comment_Sig" SG_ 752 ExchangePKBattery_522 "*";
BA_ "GenSigSendType" SG_ 752 ExchangePKBattery_522 3;
BA_ "FISI_Comment_Sig" SG_ 752 DisplayRequest_522 "*";
BA_ "GenSigSendType" SG_ 752 DisplayRequest_522 3;
BA_ "FISI_Comment_Sig" SG_ 752 ISS_StatusDspReq_207 "*";
BA_ "GenSigSendType" SG_ 752 ISS_StatusDspReq_207 3;
BA_ "FISI_Comment_Sig" SG_ 752 AutoLRainSSensorFail_729 "*";
BA_ "GenSigSendType" SG_ 752 AutoLRainSSensorFail_729 3;
BA_ "FISI_Comment_Sig" SG_ 752 LeftDIFailure_703 "*";
BA_ "GenSigSendType" SG_ 752 LeftDIFailure_703 3;
BA_ "FISI_Comment_Sig" SG_ 752 RightDIFailure_704 "*";
BA_ "GenSigSendType" SG_ 752 RightDIFailure_704 3;
BA_ "FISI_Comment_Sig" SG_ 752 BonnetLidStatus2_217 "*";
BA_ "GenSigSendType" SG_ 752 BonnetLidStatus2_217 3;
BA_ "FISI_Comment_Sig" SG_ 752 BootLidStatus_216 "*";
BA_ "GenSigSendType" SG_ 752 BootLidStatus_216 3;
BA_ "FISI_Comment_Sig" SG_ 752 PassengerSideRearDoorStatus2_215 "*";
BA_ "GenSigSendType" SG_ 752 PassengerSideRearDoorStatus2_215 3;
BA_ "FISI_Comment_Sig" SG_ 752 DriverSideRearDoorStatus2_213 "*";
BA_ "GenSigSendType" SG_ 752 DriverSideRearDoorStatus2_213 3;
BA_ "FISI_Comment_Sig" SG_ 752 BootLidStatus_520 "*";
BA_ "GenSigSendType" SG_ 752 BootLidStatus_520 3;
BA_ "FISI_Comment_Sig" SG_ 752 BonnetStatus_521 "*";
BA_ "GenSigSendType" SG_ 752 BonnetStatus_521 3;
BA_ "FISI_Comment_Sig" SG_ 752 PassengerSideRearDoorStatus_519 "*";
BA_ "GenSigSendType" SG_ 752 PassengerSideRearDoorStatus_519 3;
BA_ "FISI_Comment_Sig" SG_ 752 DriverSideRearDoorStatus_518 "*";
BA_ "GenSigSendType" SG_ 752 DriverSideRearDoorStatus_518 3;
BA_ "FISI_Comment_Sig" SG_ 752 DriverDoorStatus_516 "*";
BA_ "GenSigSendType" SG_ 752 DriverDoorStatus_516 3;
BA_ "FISI_Comment_Sig" SG_ 752 BrakeWarningTelltale_746 "*";
BA_ "GenSigSendType" SG_ 752 BrakeWarningTelltale_746 3;
BA_ "FISI_Comment_Sig" SG_ 752 ABS_Telltale_523 "*";
BA_ "GenSigSendType" SG_ 752 ABS_Telltale_523 3;
BA_ "FISI_Comment_Sig" SG_ 752 StabilityControlSt_218b "*";
BA_ "GenSigSendType" SG_ 752 StabilityControlSt_218b 3;
BA_ "FISI_Comment_Sig" SG_ 752 StabilityControlTel_218c "*";
BA_ "GenSigSendType" SG_ 752 StabilityControlTel_218c 3;
BA_ "FISI_Comment_Sig" SG_ 752 TransmDIWarnMsg_484 "*";
BA_ "GenSigSendType" SG_ 752 TransmDIWarnMsg_484 3;
BA_ "FISI_Comment_Sig" SG_ 752 TransmissionFailure_483 "*";
BA_ "GenSigSendType" SG_ 752 TransmissionFailure_483 3;
BA_ "FISI_Comment_Sig" SG_ 752 DPFSootOverload_535 "*";
BA_ "GenSigSendType" SG_ 752 DPFSootOverload_535 3;
BA_ "FISI_Comment_Sig" SG_ 752 ChangeOilNow_469 "*";
BA_ "GenSigSendType" SG_ 752 ChangeOilNow_469 3;
BA_ "FISI_Comment_Sig" SG_ 752 PassengerDoorStatus_517 "*";
BA_ "GenSigSendType" SG_ 752 PassengerDoorStatus_517 3;
BA_ "FISI_Comment_Sig" SG_ 752 RIL_RequestStatus_530 "*";
BA_ "GenSigSendType" SG_ 752 RIL_RequestStatus_530 3;
BA_ "FISI_Comment_Sig" SG_ 752 BrakeFluidLevel_515 "*";
BA_ "GenSigSendType" SG_ 752 BrakeFluidLevel_515 3;
BA_ "FISI_Comment_Sig" SG_ 752 EngineCheck_440 "*";
BA_ "GenSigSendType" SG_ 752 EngineCheck_440 3;
BA_ "FISI_Comment_Sig" SG_ 752 EngOilPressureTelltale_526 "*";
BA_ "GenSigSendType" SG_ 752 EngOilPressureTelltale_526 3;
BA_ "FISI_Comment_Sig" SG_ 752 SS_TurnIgnitionOff_643 "*";
BA_ "GenSigSendType" SG_ 752 SS_TurnIgnitionOff_643 3;
BA_ "FISI_Comment_Sig" SG_ 752 SS_SelectNeutral_644 "*";
BA_ "GenSigSendType" SG_ 752 SS_SelectNeutral_644 3;
BA_ "FISI_Comment_Sig" SG_ 752 SS_PressClutch_641 "*";
BA_ "GenSigSendType" SG_ 752 SS_PressClutch_641 3;
BA_ "FISI_Comment_Sig" SG_ 752 SS_StartEngineManually_642 "*";
BA_ "GenSigSendType" SG_ 752 SS_StartEngineManually_642 3;
BA_ "FISI_Comment_Sig" SG_ 752 SS_EngineStarting_640 "*";
BA_ "GenSigSendType" SG_ 752 SS_EngineStarting_640 3;
BA_ "GenSigStartValue" SG_ 359 PlgActvArb_B_Actl 1;
BA_ "GenSigStartValue" SG_ 516 ApedPosPcActl_D_Qf 1;
BA_ "FISI_Comment_Sig" SG_ 516 EngAout_N_Actl "Do not use the SGW interface in 0x109! Use FGW 0x204 instead!";
BA_ "HS3_Category" SG_ 516 EngAout_N_Actl 4;
BA_ "GenSigSendType" SG_ 516 EngAout_N_Actl 3;
BA_ "GenSigSendType" SG_ 754 ACU_ActChimeType_St 3;
BA_ "LegacySignalName" SG_ 711 MyKeySrvr_MyKeyClient_Word_Tx "MyKeySrvr_MyKeyClient_Word_Tx";
BA_ "GenSigSendType" SG_ 391 ACU_CtrlChimeChan_Rq 3;
BA_ "GenSigSendType" SG_ 393 CPM_Audio_State_RSP 1;
BA_ "GenSigSendType" SG_ 406 Audio_Source_Target_Cmd 1;
BA_ "LegacySignalName" SG_ 406 Primary_Audio_Source_Target "Primary_Audio_Source_Target";
BA_ "GenSigSendType" SG_ 409 Audio_Bus_Request_CPM 1;
BA_ "LegacySignalName" SG_ 408 Display_Priority_CPM_Req "Display_Priority_CPM_Req";
BA_ "LegacySignalName" SG_ 408 Display_Overwrite_CPM_Req "Display_Overwrite_CPM_Req";
BA_ "LegacySignalName" SG_ 408 Display_Start_Position_CPM "Display_Start_Position_CPM";
BA_ "GenSigSendType" SG_ 408 Display_Target_CPM_Req 1;
BA_ "GenSigSendType" SG_ 407 Dsp_MediaSrcAct_Rq 3;
BA_ "GenSigSendType" SG_ 407 Dsp_MediaSrcLst_Rq 3;
BA_ "LegacySignalName" SG_ 407 Display_Requestor_ACM_Status "Display_Requestor_ACM_Status";
BA_ "LegacySignalName" SG_ 407 Display_Grant_ACM_Status "Display_Grant_ACM_Status";
BA_ "GenSigSendType" SG_ 407 Display_Grant_ACM_Status 1;
BA_ "InvalidHex" SG_ 407 Display_Field_ACM_Status "$FF";
BA_ "LegacySignalName" SG_ 407 Display_Field_ACM_Status "Display_Field_ACM_Status";
BA_ "GenSigSendType" SG_ 1003 CPM_Acceleration_St 3;
BA_ "GenSigSendType" SG_ 1003 eCall_Event 3;
BA_ "GenSigSendType" SG_ 1003 CPM_Stereo_PAS_Source 3;
BA_ "LegacySignalName" SG_ 1003 CPM_Signal_Strength_STAT "CPM_Signal_Strength_STAT";
BA_ "GenSigSendType" SG_ 1003 CPM_Signal_Strength_STAT 3;
BA_ "GenSigSendType" SG_ 1003 CPM_Mono_Audio_Output 1;
BA_ "GenSigSendType" SG_ 1003 CPM_Batt_Level_STAT 3;
BA_ "GenSigSendType" SG_ 1003 CPM_TextMsg_AVAL 3;
BA_ "GenSigSendType" SG_ 1003 CPM_Stereo_Audio_Output 1;
BA_ "GenSigSendType" SG_ 1003 CPM_Phone_Roaming_STAT 3;
BA_ "GenSigSendType" SG_ 1003 CPM_Call_Active_STAT 3;
BA_ "GenSigSendType" SG_ 1003 BT_ICON 3;
BA_ "GenSigSendType" SG_ 1003 CPM_VoiceRec_STAT 3;
BA_ "LegacySignalName" SG_ 675 NAV_Active_Screen_Status "NAV_Active_Screen_Status";
BA_ "GenSigSendType" SG_ 675 NAV_Active_Screen_Status 3;
BA_ "GenSigSendType" SG_ 675 Current_Focus_Bar_St 3;
BA_ "GenSigSendType" SG_ 675 Dsp_LangSel_St 3;
BA_ "GenSigSendType" SG_ 675 Multimedia_System 3;
BA_ "GenSigSendType" SG_ 675 ACM_Display_Type 3;
BA_ "GenSigSendType" SG_ 675 Pop_Up_Focus_Bar_St 3;
BA_ "GenSigSendType" SG_ 675 Active_Pop_Up_St 3;
BA_ "LegacySignalName" SG_ 675 Primary_Audio_Source_ACM "Primary_Audio_Source_ACM";
BA_ "GenSigSendType" SG_ 675 Primary_Audio_Source_ACM 3;
BA_ "GenSigSendType" SG_ 263 PrsnlCnnctReset_D_Rq 3;
BA_ "GenSigSendType" SG_ 263 ACM_CPM_VR_CMND 1;
BA_ "LegacySignalName" SG_ 263 ACM_CPM_Stereo_Audio_CMND "ACM_CPM_Stereo_Audio_CMND";
BA_ "GenSigSendType" SG_ 263 ACM_CPM_Stereo_Audio_CMND 1;
BA_ "GenSigSendType" SG_ 263 ACM_CPM_Mono_Audio_CMND 1;
BA_ "GenSigSendType" SG_ 262 Dsp_SetAcceleration_Rq 3;
BA_ "GenSigStartValue" SG_ 262 Dsp_RotAddrBtnEv_St 7;
BA_ "GenSigSendType" SG_ 262 Dsp_RotAddrBtnEv_St 1;
BA_ "GenSigSendType" SG_ 262 ACM_Button_State 1;
BA_ "GenSigSendType" SG_ 534 WhlRotatRr_No_Cnt 3;
BA_ "GenSigSendType" SG_ 534 WhlDirRr_D_Actl 3;
BA_ "GenSigSendType" SG_ 534 WhlDirRl_D_Actl 3;
BA_ "GenSigSendType" SG_ 534 WhlDirFr_D_Actl 3;
BA_ "GenSigSendType" SG_ 534 WhlDirFl_D_Actl 3;
BA_ "GenSigSendType" SG_ 534 WhlRotatRl_No_Cnt 3;
BA_ "GenSigSendType" SG_ 534 WhlRotatFr_No_Cnt 3;
BA_ "GenSigSendType" SG_ 534 WhlRotatFl_No_Cnt 3;
BA_ "GenSigSendType" SG_ 656 Ill_BEZZone_St 3;
BA_ "GenSigSendType" SG_ 1008 CPM_MediaPlayerSrc_St 3;
BA_ "InvalidHex" SG_ 1008 APIM_TrackPlaytime_St "$FFFF";
BA_ "GenSigSendType" SG_ 1008 APIM_TrackPlaytime_St 3;
BA_ "InvalidHex" SG_ 1008 APIM_TotalPlayTime_St "$FFFF";
BA_ "GenSigSendType" SG_ 1008 APIM_TotalPlayTime_St 3;
BA_ "GenSigSendType" SG_ 404 Dsp_LangUpdate_Rsp 3;
BA_ "GenSigSendType" SG_ 291 LangUpdate_Rsp 3;
BA_ "GenSigSendType" SG_ 493 Dsp_AFJump_Rq 3;
BA_ "GenSigSendType" SG_ 493 Dsp_StatLiScanCancel_Rq 3;
BA_ "GenSigSendType" SG_ 493 Dsp_StationList_Rq 3;
BA_ "VNASignalName" SG_ 708 TMCSrvr_TMCClient_WORD_Tx "PHONE_RDSP_WORD_Tx_I";
BA_ "LegacySignalName" SG_ 708 TMCSrvr_TMCClient_WORD_Tx "TMCSrvr_TMCClient_WORD_Tx";
BA_ "VNASignalName" SG_ 1959 TesterPhysicalReqFCIM "ICP_Diag_Rx";
BA_ "GenSigSendType" SG_ 402 ApaMdeStat_D_RqDrv 3;
BA_ "GenSigStartValue" SG_ 402 DistanceBarSetting 1;
BA_ "GenSigSendType" SG_ 402 DistanceBarSetting 3;
BA_ "GenSigSendType" SG_ 402 CamraZoomMan_D_Rq 3;
BA_ "GenSigStartValue" SG_ 402 CamraOvrlStat_D_Rq 1;
BA_ "GenSigSendType" SG_ 402 CamraOvrlStat_D_Rq 3;
BA_ "GenSigStartValue" SG_ 402 CamraOvrlDyn_D_Rq 1;
BA_ "GenSigSendType" SG_ 402 CamraOvrlDyn_D_Rq 3;
BA_ "GenSigSendType" SG_ 402 CamAutoTowbarZoom 3;
BA_ "GenSigStartValue" SG_ 402 CamraOvrlTow_D_Rq 1;
BA_ "GenSigSendType" SG_ 402 CamraOvrlTow_D_Rq 3;
BA_ "GenSigSendType" SG_ 265 PrkAidLamp_D_Rq 3;
BA_ "GenSigSendType" SG_ 265 Light_SW_Position 3;
BA_ "FISI_Comment_Sig" SG_ 265 KeyMykeyTot_No_Cnt "Do not use the SGW interface in 0x109! Use FGW 0x38D instead!";
BA_ "HS3_Category" SG_ 265 KeyMykeyTot_No_Cnt 4;
BA_ "GenSigSendType" SG_ 265 KeyMykeyTot_No_Cnt 3;
BA_ "GenSigStartValue" SG_ 265 IgnKeyType_D_Actl 14;
BA_ "GenSigMissingSourceValue" SG_ 265 IgnKeyType_D_Actl 14;
BA_ "FISI_Comment_Sig" SG_ 265 VehVActlEng_D_Qf "Do not use the SGW interface in 0x109! Use FGW 0x202 instead!";
BA_ "HS3_Category" SG_ 265 VehVActlEng_D_Qf 4;
BA_ "FISI_Comment_Sig" SG_ 265 Veh_V_ActlEng "Do not use the SGW interface in 0x109! Use FGW 0x202 instead!";
BA_ "HS3_Category" SG_ 265 Veh_V_ActlEng 4;
BA_ "GenSigSendType" SG_ 265 Veh_V_ActlEng 3;
BA_ "GenSigSendType" SG_ 265 GearLvrPos_D_Actl 3;
BA_ "FISI_Comment_Sig" SG_ 265 EngAout_N_Actl "Do not use the SGW interface in 0x109! Use FGW 0x204 instead!";
BA_ "HS3_Category" SG_ 265 EngAout_N_Actl 4;
BA_ "GenSigSendType" SG_ 265 EngAout_N_Actl 3;
BA_ "GenSigSendType" SG_ 265 GearRvrseActv_D_Actl 3;
BA_ "FISI_Comment_Sig" SG_ 265 PwPck_D_Stat_UB "UB";
BA_ "GenSigSendType" SG_ 758 SDARS_OpMode_St 3;
BA_ "GenSigSendType" SG_ 758 SDARS_SetCategory_St 3;
BA_ "GenSigSendType" SG_ 758 SDARS_GCI_Update_Prg_St 3;
BA_ "GenSigSendType" SG_ 758 SDARS_Factory_Reset_St 3;
BA_ "GenSigSendType" SG_ 761 SDARS_Seek_Scan_St 3;
BA_ "GenSigSendType" SG_ 761 SDARS_Invalid_Chan_St 3;
BA_ "GenSigSendType" SG_ 761 SDARS_UnSubscrb_Chan_St 3;
BA_ "GenSigSendType" SG_ 761 SDARS_Loss_Ant_St 3;
BA_ "GenSigSendType" SG_ 761 SDARS_UnSubscrb_St 3;
BA_ "GenSigSendType" SG_ 761 SDARS_Subscription_St 3;
BA_ "GenSigSendType" SG_ 761 SDARS_GCI_Update_St 3;
BA_ "LegacySignalName" SG_ 761 SDARS_Firmware_Update_St "SDARS_Firmware_Update_St";
BA_ "GenSigSendType" SG_ 761 SDARS_Firmware_Update_St 3;
BA_ "GenSigSendType" SG_ 761 SDARS_Antenna_Err_St 3;
BA_ "GenSigSendType" SG_ 761 SDARS_Receive_Err_St 3;
BA_ "GenSigSendType" SG_ 761 SDARS_Error_Conf_St 3;
BA_ "GenSigSendType" SG_ 760 SDARS_SID_St 3;
BA_ "GenSigSendType" SG_ 760 SDARS_CurrentChanNum_St 3;
BA_ "GenSigSendType" SG_ 760 SDARS_Buffer_sec_St 3;
BA_ "GenSigSendType" SG_ 760 SDARS_Playback_St 3;
BA_ "GenSigSendType" SG_ 760 SDARS_FillPosition_St 3;
BA_ "GenSigSendType" SG_ 760 SDARS_Alert_Status 3;
BA_ "GenSigSendType" SG_ 760 SDARS_Channel_Lock 3;
BA_ "GenSigStartValue" SG_ 260 SDARS_InfoRefChanNum_Rq 255;
BA_ "GenSigSendType" SG_ 260 SDARS_InfoRefChanNum_Rq 3;
BA_ "GenSigSendType" SG_ 260 SDARS_GetESN_Rq 3;
BA_ "GenSigSendType" SG_ 260 SDARS_FactoryReset_Rq 3;
BA_ "GenSigSendType" SG_ 260 MFD_SDARS_SetOpMode_Rq 3;
BA_ "GenSigSendType" SG_ 260 SDARS_SRReplay_Rq 3;
BA_ "GenSigStartValue" SG_ 260 SDARS_SelectCategory_Rq 255;
BA_ "GenSigSendType" SG_ 260 SDARS_SelectCategory_Rq 3;
BA_ "GenSigStartValue" SG_ 260 MFD_SDARS_DirectTune_Rq 255;
BA_ "GenSigSendType" SG_ 260 MFD_SDARS_DirectTune_Rq 3;
BA_ "LegacySignalName" SG_ 259 SDARS_CurrCATlistSize_Rq "SDARS_CurrCATlistSize_Rq";
BA_ "GenSigSendType" SG_ 259 SDARS_CurrCATlistInd_Rq 3;
BA_ "GenSigSendType" SG_ 259 SDARS_AlertStatus_Rq 3;
BA_ "GenSigSendType" SG_ 759 Avail_HD_Chan_Valid 3;
BA_ "GenSigSendType" SG_ 759 ACM_StationListScanSt 3;
BA_ "GenSigSendType" SG_ 759 ACM_TagMode 3;
BA_ "GenSigSendType" SG_ 759 ACM_RBDSMode 3;
BA_ "LegacySignalName" SG_ 759 NumofHDMulticastChans_St "NumofHDMulticastChans_St";
BA_ "GenSigSendType" SG_ 759 NumofHDMulticastChans_St 3;
BA_ "GenSigSendType" SG_ 759 ACM_HDModeStatus 3;
BA_ "GenSigSendType" SG_ 759 ACM_HDChanStatus 3;
BA_ "GenSigSendType" SG_ 759 ACM_CurrentSSName 3;
BA_ "LegacySignalName" SG_ 759 ACM_CurrentHDMulticast_St "ACM_CurrentHDMulticast_St";
BA_ "GenSigSendType" SG_ 759 ACM_CurrentHDMulticast_St 3;
BA_ "FISI_Comment_Sig" SG_ 947 Outside_Air_Temp_Stat_UB "UB";
BA_ "GenSigStartValue" SG_ 947 Outside_Air_Temp_Stat 254;
BA_ "FISI_Comment_Sig" SG_ 947 Outside_Air_Temp_Stat "Due to misalignment during development, this interface is wrongly deployed to this bit position in 0x3B3. NetCom motivation was to use 0x3B3 on all networks as FGW.";
BA_ "GenSigSendType" SG_ 947 Outside_Air_Temp_Stat 3;
BA_ "GenSigMissingSourceValue" SG_ 947 Outside_Air_Temp_Stat 254;
BA_ "GenSigMissingSourceMeaning" SG_ 947 Ignition_Switch_Stable "Missing_from_Transmitter";
BA_ "GenSigStartMeaning" SG_ 947 Ignition_Switch_Stable "Not_Stable";
BA_ "FISI_Comment_Sig" SG_ 947 Ignition_Switch_Stable "Due to misalignment during development, this interface is wrongly deployed to this bit position in 0x3B3. NetCom motivation was to use 0x3B3 on all networks as FGW.";
BA_ "HS3_Category" SG_ 947 Ignition_Switch_Stable 1;
BA_ "GenSigSendType" SG_ 947 Ignition_Switch_Stable 3;
BA_ "GenSigMissingSourceValue" SG_ 947 Ignition_Switch_Stable 2;
BA_ "VNASignalName" SG_ 947 PrkBrkActv_B_Actl "ParkingBrakeWarning";
BA_ "FISI_Comment_Sig" SG_ 947 PrkBrkActv_B_Actl "Do not use the SGW interface in 0x3B3! Use FGW 0x3B2 instead!";
BA_ "HS3_Category" SG_ 947 PrkBrkActv_B_Actl 4;
BA_ "GenSigSendType" SG_ 947 PrkBrkActv_B_Actl 3;
BA_ "WakeupSignal" SG_ 947 PrkBrkActv_B_Actl 1;
BA_ "FISI_Comment_Sig" SG_ 947 Ignition_Status "Do not use the SGW interface in 0x3B3! Use FGW 0x3B2 instead!";
BA_ "HS3_Category" SG_ 947 Ignition_Status 4;
BA_ "GenSigSendType" SG_ 947 Ignition_Status 3;
BA_ "WakeupSignal" SG_ 947 Ignition_Status 1;
BA_ "GenSigSendType" SG_ 129 SuspDampInc_B_RqDrv 3;
BA_ "GenSigSendType" SG_ 129 SteEffortInc_B_RqDrv 3;
BA_ "GenSigSendType" SG_ 129 SelDrvMdeInc_B_RqDrv 3;
BA_ "GenSigSendType" SG_ 129 SelDrvMdeDec_B_RqDrv 3;
BA_ "WakeupSignal" SG_ 129 SteWhlSwtchUp_B_Stat 1;
BA_ "WakeupSignal" SG_ 129 SteWhlSwtchRght_B_Stat 1;
BA_ "WakeupSignal" SG_ 129 SteWhlSwtchOk_B_Stat 1;
BA_ "WakeupSignal" SG_ 129 SteWhlSwtchLeft_B_Stat 1;
BA_ "WakeupSignal" SG_ 129 SteWhlSwtchDown_B_Stat 1;
BA_ "FISI_Comment_Sig" SG_ 129 SteWhlCtl_Phone_UB "UB";
BA_ "GenSigSendType" SG_ 129 SteWhlCtl_Phone 3;
BA_ "FISI_Comment_Sig" SG_ 129 SteWhlCtl_Mute_UB "UB";
BA_ "GenSigSendType" SG_ 129 SteWhlCtl_Mute 3;
BA_ "FISI_Comment_Sig" SG_ 129 SteWhlCtl_Volume_Up_UB "UB";
BA_ "FISI_Comment_Sig" SG_ 129 SteWhlCtl_Volume_Down_UB "UB";
BA_ "FISI_Comment_Sig" SG_ 129 SteWhlCtl_Voice_PTT_UB "UB";
BA_ "FISI_Comment_Sig" SG_ 129 SteWhlCtl_Seek_Right_UB "UB";
BA_ "FISI_Comment_Sig" SG_ 129 SteWhlCtl_Seek_Left_UB "UB";
BA_ "FISI_Comment_Sig" SG_ 129 SteWhlCtl_RSideCursLeft_UB "UB";
BA_ "FISI_Comment_Sig" SG_ 129 SteWhlCtl_RSideCursDown_UB "UB";
BA_ "FISI_Comment_Sig" SG_ 129 SteWhlCtl_RSide_OK_UB "UB";
BA_ "FISI_Comment_Sig" SG_ 129 SteWhlCtl_RSide_CursUp_UB "UB";
BA_ "FISI_Comment_Sig" SG_ 129 SteWhlCtl_RSide_CursRt_UB "UB";
BA_ "FISI_Comment_Sig" SG_ 129 SteWhlCtl_Mode_UB "UB";
BA_ "FISI_Comment_Sig" SG_ 129 SteWhlCtl_Volume_Up "Legacy interface; not in use on CGEA 1.3";
BA_ "HS3_Category" SG_ 129 SteWhlCtl_Volume_Up 1;
BA_ "GenSigSendType" SG_ 129 SteWhlCtl_Volume_Up 3;
BA_ "GenSigSendType" SG_ 129 SteWhlCtl_Volume_Down 3;
BA_ "GenSigSendType" SG_ 129 SteWhlCtl_Voice_PTT 3;
BA_ "GenSigSendType" SG_ 129 SteWhlCtl_Seek_Right 3;
BA_ "GenSigSendType" SG_ 129 SteWhlCtl_Seek_Left 3;
BA_ "GenSigSendType" SG_ 129 SteWhlCtl_Mode 3;
BA_ "GenSigSendType" SG_ 129 SteWhlCtl_RSide_OK 3;
BA_ "GenSigSendType" SG_ 129 SteWhlCtl_RSide_CursorUp 3;
BA_ "FISI_Comment_Sig" SG_ 129 SteWhlCtl_RSide_CursorRt "Legacy interface; not in use on CGEA 1.3";
BA_ "HS3_Category" SG_ 129 SteWhlCtl_RSide_CursorRt 1;
BA_ "GenSigSendType" SG_ 129 SteWhlCtl_RSide_CursorRt 3;
BA_ "FISI_Comment_Sig" SG_ 129 SteWhlCtl_RSide_CursorLeft "Legacy interface; not in use on CGEA 1.3";
BA_ "HS3_Category" SG_ 129 SteWhlCtl_RSide_CursorLeft 1;
BA_ "GenSigSendType" SG_ 129 SteWhlCtl_RSide_CursorLeft 3;
BA_ "FISI_Comment_Sig" SG_ 129 SteWhlCtl_RSide_CursorDown "Legacy interface; not in use on CGEA 1.3";
BA_ "HS3_Category" SG_ 129 SteWhlCtl_RSide_CursorDown 1;
BA_ "GenSigSendType" SG_ 129 SteWhlCtl_RSide_CursorDown 3;
BA_ "FISI_Comment_Sig" SG_ 129 SteWhlCtl_Media_UB "UB";
BA_ "GenSigSendType" SG_ 129 SteWhlCtl_Media 3;
BA_ "GenSigSendType" SG_ 855 RrDefrost_HtdMirrState 3;
BA_ "GenSigSendType" SG_ 855 RCCM_Rr_Rt_TempSetpt 3;
BA_ "GenSigSendType" SG_ 855 RCCM_Fr_Left_TempSetpt 3;
BA_ "GenSigSendType" SG_ 855 RCCM_Fr_Rr_Blower_Req 3;
BA_ "GenSigSendType" SG_ 855 RCCM_Fr_Rt_TempSetpt 3;
BA_ "GenSigSendType" SG_ 855 RCCM_Rr_Left_TempSetpt 3;
BA_ "GenSigSendType" SG_ 855 Panel_Mode_State 3;
BA_ "GenSigSendType" SG_ 855 RrDefHtdMirrLdShedStat 3;
BA_ "GenSigSendType" SG_ 855 Windshield_Mode_State 3;
BA_ "GenSigSendType" SG_ 855 Recirc_Door_State 3;
BA_ "GenSigSendType" SG_ 855 Rear_System_Mode_State 3;
BA_ "GenSigSendType" SG_ 855 Default_Defrost_State 3;
BA_ "GenSigSendType" SG_ 855 Auto_AC_Indicator_Temp 3;
BA_ "GenSigSendType" SG_ 855 RrBlwrCondStLdShedStat 3;
BA_ "GenSigSendType" SG_ 855 FrBlwrCondStLdShedStat 3;
BA_ "GenSigStartValue" SG_ 856 SlidHtdBkLtInEn_B_Stat 1;
BA_ "GenSigSendType" SG_ 856 SlidHtdBkLtInEn_B_Stat 3;
BA_ "GenSigSendType" SG_ 856 RCCM_PR_Cond_Seat_Lvl 3;
BA_ "GenSigSendType" SG_ 856 RCCM_PR_Cond_Seat_Req 3;
BA_ "GenSigSendType" SG_ 856 RCCM_PF_Cond_Seat_Req 3;
BA_ "GenSigSendType" SG_ 856 RCCM_PF_Cond_Seat_Lvl 3;
BA_ "GenSigSendType" SG_ 856 RCCM_DR_Cond_Seat_Req 3;
BA_ "GenSigSendType" SG_ 856 RCCM_DR_Cond_Seat_Lvl 3;
BA_ "GenSigSendType" SG_ 856 RCCM_DF_Cond_Seat_Req 3;
BA_ "GenSigSendType" SG_ 856 RCCM_DF_Cond_Seat_Lvl 3;
BA_ "GenSigSendType" SG_ 856 PassRrCondStLdShedStat 3;
BA_ "GenSigSendType" SG_ 856 PassFrCondStLdShedStat 3;
BA_ "GenSigSendType" SG_ 856 DrvRrCondStLdShedStat 3;
BA_ "GenSigSendType" SG_ 856 DrvFrCondStLdShedStat 3;
BA_ "GenSigSendType" SG_ 856 CC_HtdStrWhl_Req 3;
BA_ "GenSigSendType" SG_ 856 Active_My_Temp 3;
VAL_ 561 Vr_SetCurrTUBand_Rq 13 "reserved1" 12 "DAB3" 11 "SAT3" 10 "SAT2" 15 "reserved_last" 9 "SAT1" 8 "DAB2" 7 "DAB1" 6 "AmAst" 5 "Am" 4 "FmAst" 3 "Fm3" 2 "Fm2" 1 "Fm1" 0 "Inactive" ;
VAL_ 561 Vr_SetCurrStatMCCh_Rq 7 "MCChannel7" 6 "MCChannel6" 5 "MCChannel5" 4 "MCChannel4" 3 "MCChannel3" 2 "MCChannel2" 1 "MCChannel1" 0 "Inactive" ;
VAL_ 561 Vr_SetCurrentStatOp_Rq 0 "Inactive" 1 "SetCurrentFrequency" 2 "SetCurrentPiCode" 3 "SetCurrentStation" ;
VAL_ 560 Vr_AudioSourceSel_Rq 5 "SDCard" 4 "Reserved" 3 "USB" 2 "BTAudio" 1 "CD" 0 "Inactive" ;
VAL_ 560 Vr_SkipTrack_Rq 2 "Decrement" 1 "Increment" 0 "Inactive" ;
VAL_ 560 Vr_SetOperationMode_Rq 7 "FastRewind20" 6 "FastRewind10" 5 "FastForward20" 4 "FastForward10" 3 "Pause" 2 "Play" 1 "Stop" 0 "Inactive" ;
VAL_ 560 Vr_CDSetShuffle_Rq 0 "Inactive" 1 "On" 2 "Off" 3 "OnFolder" ;
VAL_ 560 Vr_CDSetRepeat_Rq 0 "Inactive" 1 "RepeatOnTrack" 2 "Off" 3 "OnFolder" ;
VAL_ 557 Con_MediaSrc16_St 7 "Status7" 6 "Status6" 5 "Status5" 4 "Status4" 3 "Status3" 2 "Status2" 1 "Status1" 0 "NoDataExists" ;
VAL_ 557 Con_MediaSrc15_St 7 "Status7" 6 "Status6" 5 "Status5" 4 "Status4" 3 "Status3" 2 "Status2" 1 "Status1" 0 "NoDataExists" ;
VAL_ 557 Con_MediaSrc14_St 7 "Status7" 6 "Status6" 5 "Status5" 4 "Status4" 3 "Status3" 2 "Status2" 1 "Status1" 0 "NoDataExists" ;
VAL_ 557 Con_MediaSrc13_St 7 "Status7" 6 "Status6" 5 "Status5" 4 "Status4" 3 "Status3" 2 "Status2" 1 "Status1" 0 "NoDataExists" ;
VAL_ 557 Con_MediaSrc12_St 7 "Status7" 6 "Status6" 5 "Status5" 4 "Status4" 3 "Status3" 2 "Status2" 1 "Status1" 0 "NoDataExists" ;
VAL_ 557 Con_MediaSrc11_St 7 "Status7" 6 "Status6" 5 "Status5" 4 "Status4" 3 "Status3" 2 "Status2" 1 "Status1" 0 "NoDataExists" ;
VAL_ 557 Con_MediaSrc10_St 7 "Status7" 6 "Status6" 5 "Status5" 4 "Status4" 3 "Status3" 2 "Status2" 1 "Status1" 0 "NoDataExists" ;
VAL_ 557 Con_MediaSrc9_St 7 "Status7" 6 "Status6" 5 "Status5" 4 "Status4" 3 "Status3" 2 "Status2" 1 "Status1" 0 "NoDataExists" ;
VAL_ 557 Con_MediaSrc8_St 7 "Status7" 6 "Status6" 5 "Status5" 4 "Status4" 3 "Status3" 2 "Status2" 1 "Status1" 0 "NoDataExists" ;
VAL_ 557 Con_MediaSrc7_St 7 "Status7" 6 "Status6" 5 "Status5" 4 "Status4" 3 "Status3" 2 "Status2" 1 "Status1" 0 "NoDataExists" ;
VAL_ 557 Con_MediaSrc6_St 7 "Status7" 6 "Status6" 5 "Status5" 4 "Status4" 3 "Status3" 2 "Status2" 1 "Status1" 0 "NoDataExists" ;
VAL_ 557 Con_MediaSrc5_St 7 "Status7" 6 "Status6" 5 "Status5" 4 "Status4" 3 "Status3" 2 "Status2" 1 "Status1" 0 "NoDataExists" ;
VAL_ 557 Con_MediaSrc4_St 7 "Status7" 6 "Status6" 5 "Status5" 4 "Status4" 3 "Status3" 2 "Status2" 1 "Status1" 0 "NoDataExists" ;
VAL_ 557 Con_MediaSrc3_St 7 "Status7" 6 "Status6" 5 "Status5" 4 "Status4" 3 "Status3" 2 "Status2" 1 "Status1" 0 "NoDataExists" ;
VAL_ 557 Con_MediaSrc2_St 7 "Status7" 6 "Status6" 5 "Status5" 4 "Status4" 3 "Status3" 2 "Status2" 1 "Status1" 0 "NoDataExists" ;
VAL_ 557 Con_MediaSrc1_St 7 "Status7" 6 "Status6" 5 "Status5" 4 "Status4" 3 "Status3" 2 "Status2" 1 "Status1" 0 "NoDataExists" ;
VAL_ 1234 AHU_LWRadioSup_St 2 "WithoutLW" 1 "WithLW" 0 "NoDataExists" ;
VAL_ 1234 AHU_AMRadioSup_St 2 "WithoutAM" 1 "WithAM" 0 "NoDataExists" ;
VAL_ 1234 AHU_FMRadioSup_St 2 "WithoutFM" 1 "WithFM" 0 "NoDataExists" ;
VAL_ 531 VehStop_D_Stat 3 "Faulty" 2 "NoDataExists" 1 "Yes" 0 "No" ;
VAL_ 531 PrkBrkMsgTxt_D_Rq 15 "Message15" 14 "Message14" 13 "Message13" 12 "Message12" 11 "Message11" 10 "Message10" 9 "Message9" 8 "Message8" 7 "Message7" 6 "Message6" 5 "Message5" 4 "Message4" 3 "Message3" 2 "Message2" 1 "Message1" 0 "No_Message" ;
VAL_ 531 PrkBrkYwLamp_D_Rq 3 "Fast_Flash" 2 "Slow_Flash" 1 "On" 0 "Off" ;
VAL_ 531 PrkBrkStatus 7 "GeneralFault_MaintenceMode" 6 "ECD_by_Brake_ECU_Active" 5 "EPB_Limphome_Active" 4 "Rear_Caliper_Open" 3 "RWU_By_EPB_Active" 2 "Rear_Caliper_Transition" 1 "Rear_Caliper_Closed" 0 "Not_Used" ;
VAL_ 531 PrkBrkRedLamp_D_Rq 3 "Fast_Flash" 2 "Slow_Flash" 1 "On" 0 "Off" ;
VAL_ 531 CmbbBrkDis_B_Actl 1 "Yes" 0 "No" ;
VAL_ 531 CmbbBaSensInc_B_Actl 1 "Yes" 0 "No" ;
VAL_ 531 CmbbBrkDecel_B_Actl 1 "Yes" 0 "No" ;
VAL_ 531 CmbbBrkPrchg_B_Actl 1 "Yes" 0 "No" ;
VAL_ 531 CmbbDeny_B_ActlBrk 1 "Yes" 0 "No" ;
VAL_ 531 AccBrkPrchgActv_B_Actl 1 "Yes" 0 "No" ;
VAL_ 531 AccBrkTotTqMn_B_Actl 1 "Yes" 0 "No" ;
VAL_ 531 AccBrkWarm_B_Actl 1 "Yes" 0 "No" ;
VAL_ 531 VehLongOvrGnd_A_Est 1023 "Fault" 1022 "Unknown" ;
VAL_ 531 AccBrkDeny_B_Actl 1 "Yes" 0 "No" ;
VAL_ 531 AccBrkActv_B_Actl 1 "Yes" 0 "No" ;
VAL_ 531 AccBrkDis_B_Actl 1 "Yes" 0 "No" ;
VAL_ 531 AbsActv_B_Actl 1 "Yes" 0 "No" ;
VAL_ 531 PrplDrgCtlActv_B_Actl 1 "Active" 0 "Inactive" ;
VAL_ 531 CcDis_B_Cmd 1 "Yes" 0 "No" ;
VAL_ 531 AccDis_B_ActlEpb 1 "Yes" 0 "No" ;
VAL_ 531 VehicleStationary 1 "Yes" 0 "No" ;
VAL_ 531 LscmbBrkPrchg_B_Actl 1 "Active" 0 "Inactive" ;
VAL_ 531 LscmbbMntr_B_Err 1 "DisplayMessage" 0 "NoMessage" ;
VAL_ 531 LscmbbDeny_B_ActlBrk 1 "Yes" 0 "No" ;
VAL_ 531 LscmbbBrkDis_B_Actl 1 "Yes" 0 "No" ;
VAL_ 531 LscmbbBrkDecel_B_Actl 1 "Yes" 0 "No" ;
VAL_ 531 LscmbbBaSensInc_B_Actl 1 "Yes" 0 "No" ;
VAL_ 531 AccStopActv_B_ActlBrk 1 "Yes" 0 "No" ;
VAL_ 531 StabCtlBrkActv_B_Actl 1 "Yes" 0 "No" ;
VAL_ 531 TracCtlPtActv_B_Actl 1 "Active" 0 "Inactive" ;
VAL_ 803 CNG_LowFuel_792 1 "Yes" 0 "No" ;
VAL_ 803 CNG_Malfunction_793 1 "Yes" 0 "No" ;
VAL_ 803 CNG_CNGMode_794 1 "Yes" 0 "No" ;
VAL_ 803 CNG_GasMode_795 1 "Yes" 0 "No" ;
VAL_ 803 LowOilLevel_254 1 "Yes" 0 "No" ;
VAL_ 995 FobAssocChime_B_Rq 1 "On" 0 "Off" ;
VAL_ 995 PersIndexBcm_D_Actl 7 "Unused_3" 6 "Unused_2" 5 "Unused_1" 4 "Vehicle" 3 "PERS_4" 2 "PERS_3" 1 "PERS_2" 0 "PERS_1" ;
VAL_ 995 LightAmbIntsty_No_Actl 0 "Off" ;
VAL_ 906 CcdMsgTxt_D_RqDsply_UB 1 "Fresh_data" 0 "Unchanged_data" ;
VAL_ 906 CcdMsgTxt_D_RqDsply 15 "Unused8" 14 "Unused7" 13 "Unused6" 12 "Unused5" 11 "Unused4" 10 "Unused3" 9 "Unused2" 8 "Unused1" 7 "Mode_Change_Unavailable" 6 "CCD_Temporarily_Off" 5 "CCD_Service_Required" 4 "Fault" 3 "Sport" 2 "Normal" 1 "Comfort" 0 "No_Mode_Selected" ;
VAL_ 906 SlMde_D_RqDsply 3 "NotUsed" 2 "ManualSpeed_LimiterSymbol" 1 "AutoSpeed_LimiterSymbol" 0 "NoSpeed_LimiterSymbol" ;
VAL_ 906 IsaOffst_D_Stat 15 "Faulty" 14 "Null" 13 "Thirteen" 12 "Twelve" 11 "Eleven" 10 "Ten" 9 "Nine" 8 "Eight" 7 "Seven" 6 "Six" 5 "Five" 4 "Four" 3 "Three" 2 "Two" 1 "One" 0 "Zero" ;
VAL_ 906 SlMde_D_Stat 3 "IsaNotConfigured" 2 "Manual_Mode" 1 "Auto_Mode" 0 "Null" ;
VAL_ 906 SlMde_D_RqDsply_UB 1 "Fresh_data" 0 "Unchanged_data" ;
VAL_ 906 ApaChime_D_Rq 7 "NotUsed2" 6 "NotUsed1" 5 "Warning_Chime" 4 "Finish_Chime" 3 "Stop_Now_Chime" 2 "Spot_Ready_Chime" 1 "Spot_Found_Chime" 0 "No_Chime" ;
VAL_ 906 MemDrvDeny_B_Stat_UB 1 "Fresh_data" 0 "Unchanged_data" ;
VAL_ 906 MemDrvDeny_B_Stat 1 "Yes" 0 "No" ;
VAL_ 906 BrkDrvMde_D_Stat_UB 1 "Fresh_data" 0 "Unchanged_data" ;
VAL_ 906 BrkDrvMde_D_Stat 7 "Faulty" 6 "NotUsed3" 5 "NotUsed2" 4 "NotUsed1" 3 "Track" 2 "Snow_Wet" 1 "Sport" 0 "Normal" ;
VAL_ 906 HeadLghtHiOn_B_StatHcm_UB 1 "Fresh_data" 0 "Unchanged_data" ;
VAL_ 906 HeadLghtHiOn_B_StatHcm 1 "On" 0 "Off" ;
VAL_ 906 Running_Board_Stat 3 "Unused" 2 "Manually_Deployed" 1 "All_Enabled" 0 "All_Disabled" ;
VAL_ 906 PrkLckCtlUnlck_D_Stat 3 "Trans_And_Steer_Unlckd" 2 "Steering_Unlckd" 1 "Transmission_Unlckd" 0 "Null" ;
VAL_ 906 PrkLckCtlTow_B_Enbl 1 "Enable" 0 "Disable" ;
VAL_ 906 DrTgateChime2_D_Rq 7 "NotUsed3" 6 "NotUsed2" 5 "NotUsed1" 4 "Long_Repeated" 3 "Fast" 2 "Short" 1 "Long" 0 "Off" ;
VAL_ 906 TurnLghtSwtch_D_Stat_UB 1 "Fresh_data" 0 "Unchanged_data" ;
VAL_ 906 TurnLghtSwtch_D_Stat 3 "Unused_Treat_As_Off" 2 "Right" 1 "Left" 0 "Off" ;
VAL_ 906 Adaptive_Hdlmp_Fault_UB 1 "Fresh_data" 0 "Unchanged_data" ;
VAL_ 906 Memory_Feedback_Rqst_UB 1 "Fresh_data" 0 "Unchanged_data" ;
VAL_ 906 PrkLckCtl_B_Enbl_UB 1 "Fresh_data" 0 "Unchanged_data" ;
VAL_ 906 PrkLckCtl_B_Enbl 1 "Enable" 0 "Disable" ;
VAL_ 906 PrkLckCtlMsgTxt_D_Rq_UB 1 "Fresh_data" 0 "Unchanged_data" ;
VAL_ 906 PrkLckCtlMsgTxt_D_Rq 3 "BTSI_DI_3" 2 "BTSI_DI_2" 1 "BTSI_DI_1" 0 "Null_BTSI_DI" ;
VAL_ 906 PrkLckCtlAvail_T_Stat_UB 1 "Fresh_data" 0 "Unchanged_data" ;
VAL_ 906 DrTgateChime2_D_Rq_UB 1 "Fresh_data" 0 "Unchanged_data" ;
VAL_ 906 GearLvrPos_D_Actl_UB 1 "Fresh_data" 0 "Unchanged_data" ;
VAL_ 906 Power_Liftgate_Mode_Stt_UB 1 "Fresh_data" 0 "Unchanged_data" ;
VAL_ 906 Adaptive_Hdlmp_Fault 1 "Yes" 0 "No" ;
VAL_ 906 Power_Liftgate_Mode_Stt 2 "Unused" 3 "Not_Supported" 1 "Enabled" 0 "Disabled" ;
VAL_ 906 Memory_Feedback_Rqst 1 "Yes" 0 "No" ;
VAL_ 906 GearLvrPos_D_Actl 15 "Fault" 14 "Unknown_Position" 13 "Undefined_Treat_as_Fault1" 12 "Undefined_Treat_as_Fault" 11 "sixth" 10 "fifth" 9 "fourth" 8 "third" 7 "second" 6 "first" 5 "Low" 4 "Sport_DriveSport" 3 "Drive" 2 "Neutral" 1 "Reverse" 0 "Park" ;
VAL_ 991 PersIndexVdm_D_Actl 7 "Unused3" 6 "Unused2" 5 "Unused1" 4 "Vehicle" 3 "PERS_4" 2 "PERS_3" 1 "PERS_2" 0 "PERS_1" ;
VAL_ 845 StmsLmbrPsgr_D_Stat 3 "High" 2 "Low" 1 "Off" 0 "Null" ;
VAL_ 845 StmsCshnPsgr_D_Stat 3 "High" 2 "Low" 1 "Off" 0 "Null" ;
VAL_ 845 SeatSwtchPsgr_B_Stat 1 "On" 0 "Off" ;
VAL_ 845 SeatPPsgr_B_Stat 1 "Updating" 0 "NotUpdating" ;
VAL_ 845 SeatFnPsgr_D_Stat 7 "CushionMassage" 6 "LumbarMassage" 5 "UpperBolster" 4 "LowerBolster" 3 "UpperLumbar" 2 "MiddleLumbar" 1 "LowerLumbar" 0 "Null" ;
VAL_ 845 PsgrMemFeedback_Rsp 8 "Recall_4" 7 "Recall_3" 6 "Recall_2" 5 "Recall_1" 4 "Store_4" 3 "Store_3" 2 "Store_2" 1 "Store_1" 0 "Inactive" ;
VAL_ 844 StmsLmbrDrv_D_Stat 3 "High" 2 "Low" 1 "Off" 0 "Null" ;
VAL_ 844 StmsCshnDrv_D_Stat 3 "High" 2 "Low" 1 "Off" 0 "Null" ;
VAL_ 844 SeatSwtchDrv_B_Stat 1 "On" 0 "Off" ;
VAL_ 844 SeatFnDrv_D_Stat 7 "CushionMassage" 6 "LumbarMassage" 5 "UpperBolster" 4 "LowerBolster" 3 "UpperLumbar" 2 "MiddleLumbar" 1 "LowerLumbar" 0 "Null" ;
VAL_ 844 SeatPDrv_B_Stat 1 "Updating" 0 "NotUpdating" ;
VAL_ 850 SeatBlLoPsgr_Pc_Actl2 127 "Null" ;
VAL_ 850 SeatCshnPsgrRR_Pc_Actl 127 "Null" ;
VAL_ 850 SeatCshnPsgrRL_Pc_Actl 127 "Null" ;
VAL_ 850 SeatCshnPsgrFR_Pc_Actl 127 "Null" ;
VAL_ 850 SeatCshnPsgrFL_Pc_Actl 127 "Null" ;
VAL_ 849 SeatCshnDrvRR_Pc_Actl 127 "Null" ;
VAL_ 849 SeatCshnDrvRL_Pc_Actl 127 "Null" ;
VAL_ 849 SeatCshnDrvFR_Pc_Actl 127 "Null" ;
VAL_ 849 SeatCshnDrvFL_Pc_Actl 127 "Null" ;
VAL_ 843 SeatLmbrUpPsgr_Pc_Actl 127 "Null" ;
VAL_ 843 SeatLmbrMidPsgr_Pc_Actl 127 "Null" ;
VAL_ 843 SeatLmbrLoPsgr_Pc_Actl 127 "Null" ;
VAL_ 843 SeatBlUpPsgr_Pc_Actl 127 "Null" ;
VAL_ 843 SeatBlLoPsgr_Pc_Actl 127 "Null" ;
VAL_ 842 SeatLmbrUpDrv_Pc_Actl 127 "Null" ;
VAL_ 842 SeatLmbrMidDrv_Pc_Actl 127 "Null" ;
VAL_ 842 SeatLmbrLoDrv_Pc_Actl 127 "Null" ;
VAL_ 842 SeatBlUpDrv_Pc_Actl 127 "Null" ;
VAL_ 842 SeatBlLoDrv_Pc_Actl 127 "Null" ;
VAL_ 135 McGlblClkAdj_B_Rq 1 "Request" 0 "NoRequest" ;
VAL_ 1242 DimmerHMISrcStatus 3 "soft_HMI_dimmer_present" 2 "PushButton_dimmer_present" 1 "Rotary_dimmer_present" 0 "Dimmer_NOT_present" ;
VAL_ 1242 ALSCfgStatus 3 "reserved" 2 "ALS_present_failed" 1 "ALS_present" 0 "ALS_NOT_present" ;
VAL_ 538 MK_AudioLimitConfig_St 3 "Reserved" 2 "On" 1 "Off" 0 "NoDataExist" ;
VAL_ 538 MK_AdminMyKeyCount_St 15 "NoDataExist" 14 "Unlimited" ;
VAL_ 538 MK_UserMyKeyCount_St 15 "NoDataExist" 14 "Unlimited" ;
VAL_ 538 MK_SpeedMinderConf_St 31 "mph90" 30 "mph85" 29 "mph80" 28 "mph75" 27 "mph70" 26 "mph65" 25 "mph60" 24 "mph55" 23 "mph50" 22 "mph45" 21 "mph40" 20 "Kmh165" 19 "Kmh160" 18 "Kmh155" 17 "Kmh150" 16 "Kmh145" 15 "Kmh140" 14 "Kmh135" 13 "Kmh130" 12 "Kmh125" 11 "Kmh120" 10 "Kmh115" 9 "Kmh110" 8 "Kmh105" 7 "Kmh100" 6 "kmh95" 5 "kmh90" 4 "kmh85" 3 "kmh80" 2 "kmh75" 1 "kmh70" 0 "Off" ;
VAL_ 538 MK_SpeedLimitConf_St 31 "mph90" 30 "mph85" 29 "mph80" 28 "mph75" 27 "mph70" 26 "mph65" 25 "mph60" 24 "mph55" 23 "mph50" 22 "mph45" 21 "mph40" 20 "Kmh165" 19 "Kmh160" 18 "Kmh155" 17 "Kmh150" 16 "Kmh145" 15 "Kmh140" 14 "Kmh135" 13 "Kmh130" 12 "Kmh125" 11 "Kmh120" 10 "Kmh115" 9 "Kmh110" 8 "Kmh105" 7 "Kmh100" 6 "kmh95" 5 "kmh90" 4 "kmh85" 3 "kmh80" 2 "kmh75" 1 "kmh70" 0 "Off" ;
VAL_ 538 MK_ESCRestrictConf_St 3 "Reserved" 2 "On" 1 "Off" 0 "NoDataExist" ;
VAL_ 538 MK_ECalRestrictConf_St 3 "Reserved" 2 "On" 1 "Off" 0 "NoDataExist" ;
VAL_ 538 MK_DNDRestrictConf_St 3 "Reserved" 2 "On" 1 "Off" 0 "NoDataExist" ;
VAL_ 538 MK_ACSRestrictConf_St 3 "Reserved" 2 "On" 1 "Off" 0 "NoDataExist" ;
VAL_ 801 SoftWarning 1 "Chime_On" 0 "Chime_Off" ;
VAL_ 801 InfoWarning 1 "Chime_On" 0 "Chime_Off" ;
VAL_ 801 HardWarning 1 "Chime_On" 0 "Chime_Off" ;
VAL_ 801 Reset_EcoMode 1 "Active" 0 "Inactive" ;
VAL_ 801 Reset_AFE_EcoMode 1 "Active" 0 "Inactive" ;
VAL_ 422 MK_AdminMyKeyCount_Rsp 15 "Inactive" 14 "Unlimited" ;
VAL_ 422 MK_UserMyKeyCount_Rsp 15 "Inactive" 14 "Unlimited" ;
VAL_ 422 MK_CreateMyKey_Rsp 7 "Reserved_3" 6 "Reserved_2" 5 "Reserved_1" 4 "Success" 3 "GenericFailure" 2 "NoKeyInSlot" 1 "KeyInSlotAlreadyMyKey" 0 "Inactive" ;
VAL_ 419 MK_SpeedValue_Rq 31 "mph90" 30 "mph85" 29 "mph80" 28 "mph75" 27 "mph70" 26 "mph65" 25 "mph60" 24 "mph55" 23 "mph50" 22 "mph45" 21 "mph40" 20 "Kmh165" 19 "Kmh160" 18 "Kmh155" 17 "Kmh150" 16 "Kmh145" 15 "Kmh140" 14 "Kmh135" 13 "Kmh130" 12 "Kmh125" 11 "Kmh120" 10 "Kmh115" 9 "Kmh110" 8 "Kmh105" 7 "Kmh100" 6 "kmh95" 5 "kmh90" 4 "kmh85" 3 "kmh80" 2 "kmh75" 1 "kmh70" 0 "Off" ;
VAL_ 419 MK_SpeedSetting_Rq 15 "Reserved_last" 3 "Reserved" 2 "SpeedMinder" 1 "SpeedLimit" 0 "Inactive" ;
VAL_ 419 MK_ResetAllUserKeys_Rq 1 "ResetAllKeys" 0 "Inactive" ;
VAL_ 419 MK_MyKeySystemInfo_Rq 1 "GetData" 0 "Inactive" ;
VAL_ 419 MK_ESCRestrictConf_Rq 2 "On" 1 "Off" 0 "Inactive" ;
VAL_ 419 MK_ECalRestrictConf_Rq 2 "On" 1 "Off" 0 "Inactive" ;
VAL_ 419 MK_DNDRestrictConf_Rq 2 "On" 1 "Off" 0 "Inactive" ;
VAL_ 419 MK_CreateMyKey_Rq 1 "Create" 0 "Inactive" ;
VAL_ 419 MK_AudioLimitConfig_Rq 2 "On" 1 "Off" 0 "Inactive" ;
VAL_ 419 MK_ACSRestrictConf_Rq 2 "On" 1 "Off" 0 "Inactive" ;
VAL_ 410 AugustReport_St 2 "Available" 1 "Unavailable" 0 "No_Data_Exists" ;
VAL_ 410 AprilReport_St 2 "Available" 1 "Unavailable" 0 "No_Data_Exists" ;
VAL_ 410 SeptemberReport_St 2 "Available" 1 "Unavailable" 0 "No_Data_Exists" ;
VAL_ 410 ReportCardOnOff_St 2 "On" 1 "Off" 0 "No_Data_Exists" ;
VAL_ 410 OctoberReport_St 2 "Available" 1 "Unavailable" 0 "No_Data_Exists" ;
VAL_ 410 NovemberReport_St 2 "Available" 1 "Unavailable" 0 "No_Data_Exists" ;
VAL_ 410 MayReport_St 2 "Available" 1 "Unavailable" 0 "No_Data_Exists" ;
VAL_ 410 MarchReport_St 2 "Available" 1 "Unavailable" 0 "No_Data_Exists" ;
VAL_ 410 JuneReport_St 2 "Available" 1 "Unavailable" 0 "No_Data_Exists" ;
VAL_ 410 JulyReport_St 2 "Available" 1 "Unavailable" 0 "No_Data_Exists" ;
VAL_ 410 JanuaryReport_St 2 "Available" 1 "Unavailable" 0 "No_Data_Exists" ;
VAL_ 410 FebruaryReport_St 2 "Available" 1 "Unavailable" 0 "No_Data_Exists" ;
VAL_ 410 DecemberReport_St 2 "Available" 1 "Unavailable" 0 "No_Data_Exists" ;
VAL_ 410 ClusterMajorUnits_St 4 "KilometersPerLiter" 3 "LiterPer100Kilometers" 2 "MilesPerUKGallon" 1 "MilesPerGallon" 0 "No_Data_Exits" ;
VAL_ 410 MyKey_e911Override_St 2 "On" 1 "Off" 0 "No_Data_Exists" ;
VAL_ 410 DoNotDisturbOveride_St 2 "On" 1 "Off" 0 "No_Data_Exists" ;
VAL_ 802 DISP_PowerFoldMirrorSt 1 "On_FoldOnLockUnlock" 0 "Off_NoFoldOnLockUnlock" ;
VAL_ 802 DISP_MPH_KPH 1 "Imperial_mph" 0 "Metric_kph" ;
VAL_ 802 DISP_MoodLightSt 1 "MoodlightEnabled" 0 "MoodlightDisabled" ;
VAL_ 802 DISP_LaneChangingInd 1 "On_3Flashes" 0 "Off_1Flash" ;
VAL_ 802 DISP_ChimesSt 3 "InfoAndWarningOff" 2 "WarningOn" 1 "InfoAndWarningOn" 0 "InfoOn" ;
VAL_ 417 SetAlarmAskOnExitSetting_Rq 2 "On" 1 "Off" 0 "Inactive" ;
VAL_ 417 SetAlarmMode_Rq 2 "ReducedGuard" 1 "FullGuard" 0 "Inactive" ;
VAL_ 417 VS_SetLaneChangeInd_Rq 3 "reserved" 2 "Flash_3" 1 "Flash_1" 0 "Inactive" ;
VAL_ 417 VS_SetPowFolMirMode_Rq 3 "reserved" 2 "On" 1 "Off" 0 "Inactive" ;
VAL_ 417 VS_SetMoodLight_Rq 3 "reserved" 2 "On" 1 "Off" 0 "Inactive" ;
VAL_ 417 VS_DeflDetSysInit_Rq 1 "DDSInit" 0 "DDSNoInit" ;
VAL_ 417 VS_SetESPMode_Rq 3 "ESP_TCS_Off" 2 "ESP_TCS_On" 1 "ESP_Off" 0 "Inactive" ;
VAL_ 417 VS_HSAMde_D_Rq 3 "reserved" 2 "Auto" 1 "Off" 0 "Inactive" ;
VAL_ 417 VS_LowSpeedCMbB_Rq 3 "NotUsed" 2 "On" 1 "Off" 0 "Inactive" ;
VAL_ 417 PrkLckCtlEnbl_D_Rq 3 "reserved" 2 "RQ_Enable" 1 "RQ_Disable" 0 "NULL" ;
VAL_ 417 SetRainSensorMode_Rq 3 "Reserved" 2 "On" 1 "Off" 0 "Inactive" ;
VAL_ 417 TirePReset_B_Rq 1 "Reset" 0 "NULL" ;
VAL_ 793 EngineOn_98 1 "Yes" 0 "No" ;
VAL_ 793 Soot_DPFSootLevel2_578 1 "Yes" 0 "No" ;
VAL_ 793 Soot_DPFRegen_537 1 "Yes" 0 "No" ;
VAL_ 793 Soot_DPFRegen_536 1 "Yes" 0 "No" ;
VAL_ 793 TopSpeedInfo_666 1 "On" 0 "Off" ;
VAL_ 793 Headlamp_Failure_430 1 "Yes" 0 "No" ;
VAL_ 793 ParkBrake_Hard_626 1 "Yes" 0 "No" ;
VAL_ 793 ParkBrake_Soft_625 1 "Yes" 0 "No" ;
VAL_ 793 TPMS_NotTraiRepeat_969 1 "Yes" 0 "No" ;
VAL_ 793 TPMS_TrainingCompl_968 1 "Yes" 0 "No" ;
VAL_ 793 TPMS_TraiInLeRear_967 1 "Yes" 0 "No" ;
VAL_ 793 TPMS_TraiOutLeRear_966 1 "Yes" 0 "No" ;
VAL_ 793 TPMS_TrainLeftRear_965 1 "Yes" 0 "No" ;
VAL_ 793 TPMS_TraiInRiRear_964 1 "Yes" 0 "No" ;
VAL_ 793 TPMS_TraiOutRiRear_963 1 "Yes" 0 "No" ;
VAL_ 793 TPMS_TraiRiRear_962 1 "Yes" 0 "No" ;
VAL_ 793 TPMS_TraiRiFront_961 1 "Yes" 0 "No" ;
VAL_ 793 TPMS_TraiLeftFront_960 1 "Yes" 0 "No" ;
VAL_ 793 TPMS_GlobalWarning_493 1 "Yes" 0 "No" ;
VAL_ 793 TPMS_NoSensors_474 1 "Yes" 0 "No" ;
VAL_ 793 TPMS_Malfunction_400 1 "Yes" 0 "No" ;
VAL_ 793 PAHWSwitchOffIn_671 1 "On" 0 "Off" ;
VAL_ 793 ESCHWSwitchOffIn_676 1 "On" 0 "Off" ;
VAL_ 793 SpeedMinder_665 1 "On" 0 "Off" ;
VAL_ 793 MyKeyActive_660 1 "On" 0 "Off" ;
VAL_ 793 SpeedLimitIndic_661 1 "On" 0 "Off" ;
VAL_ 793 SpeedLimitInfo_667 1 "On" 0 "Off" ;
VAL_ 793 Point_Highspeed 1 "Active" 0 "Inactive" ;
VAL_ 793 Point_Gearshift 1 "Active" 0 "Inactive" ;
VAL_ 793 Point_Anticip 1 "Active" 0 "Inactive" ;
VAL_ 793 I_highspeed 7 "NoDataExist" 6 "NotUsed" 5 "petal_1_to_5" 4 "petal_1_to_4" 3 "petal_1_to_3" 2 "petal_1_to_2" 1 "petal_1" 0 "all_petals_off" ;
VAL_ 793 I_gearshift 7 "NoDataExist" 6 "NotUsed" 5 "petal_1_to_5" 4 "petal_1_to_4" 3 "petal_1_to_3" 2 "petal_1_to_2" 1 "petal_1" 0 "all_petals_off" ;
VAL_ 793 I_anticip 7 "NoDataExist" 6 "NotUsed" 5 "petal_1_to_5" 4 "petal_1_to_4" 3 "petal_1_to_3" 2 "petal_1_to_2" 1 "petal_1" 0 "all_petals_off" ;
VAL_ 793 OTIS_PressBAndC_657 1 "Yes" 0 "No" ;
VAL_ 793 OTIS_PressBrake_655 1 "Yes" 0 "No" ;
VAL_ 793 OTIS_PressClutch_656 1 "Yes" 0 "No" ;
VAL_ 793 LSSS_PostIncident_710 1 "Yes" 0 "No" ;
VAL_ 793 LSSS_Malfunction_712 1 "Yes" 0 "No" ;
VAL_ 793 LSSS_CleanSensor_711 1 "Yes" 0 "No" ;
VAL_ 793 DDS_PressureWarning_512 1 "Yes" 0 "No" ;
VAL_ 793 DDS_Unavailable_513 1 "Yes" 0 "No" ;
VAL_ 793 ECOADVICE4 1 "Active" 0 "Inactive" ;
VAL_ 793 ECOADVICE3 1 "Active" 0 "Inactive" ;
VAL_ 793 ECOADVICE2 1 "Active" 0 "Inactive" ;
VAL_ 793 ECOADVICE1 1 "Active" 0 "Inactive" ;
VAL_ 793 BTSI_MORShiftNotIP_752 1 "Yes" 0 "No" ;
VAL_ 793 BTSI_MORShiftUnloc_751 1 "Yes" 0 "No" ;
VAL_ 793 BTSI_MORPreBraToUn_750 1 "Yes" 0 "No" ;
VAL_ 793 OTIS_StartOvrheat_658 1 "Yes" 0 "No" ;
VAL_ 793 ECSS_StartPdgWait_790 1 "Yes" 0 "No" ;
VAL_ 793 ECSS_PendingStart_791 1 "Yes" 0 "No" ;
VAL_ 753 AlarmPopUp_St 2 "Active" 1 "NotActive" 0 "NoDataExist" ;
VAL_ 753 AlarmMode_St 2 "ReducedGuard" 1 "FullGuard" 0 "NoDataExist" ;
VAL_ 753 AlarmAskOnExitSetting_St 2 "On" 1 "Off" 0 "NoDataExist" ;
VAL_ 753 VS_WiperStalkRotat_St 7 "Reserved" 6 "Step6" 5 "Step5" 4 "Step4" 3 "Step3" 2 "Step2" 1 "Step1" 0 "NoDataExist" ;
VAL_ 753 VS_WiperStalkPos_St 7 "Reserved2" 6 "Reserved1" 5 "HighSpeed" 4 "LowSpeed" 3 "IntermittentWipe" 2 "SingleWipe" 1 "Off" 0 "NoDataExist" ;
VAL_ 753 VS_RainSensorMode_St 3 "Error" 2 "On" 1 "Off" 0 "NoDataExist" ;
VAL_ 753 VS_LaneChangIndMode_St 3 "reserved" 2 "Flash_3" 1 "Flash_1" 0 "NoDataExist" ;
VAL_ 753 VS_HSAMde_D_Mem_St 3 "reserved" 2 "Auto" 1 "Off" 0 "NoDataExist" ;
VAL_ 753 VS_PowFolMirMode_St 3 "reserved" 2 "On" 1 "Off" 0 "NoDataExist" ;
VAL_ 753 VS_LscmbbOnOff_D_St 3 "NotAvailable" 2 "On" 1 "Off" 0 "NoDataExist" ;
VAL_ 753 VS_MoodLightMode_St 3 "reserved" 2 "On" 1 "Off" 0 "NoDataExist" ;
VAL_ 753 VS_StabilityControl_St 3 "NoDataExist" 2 "ESP_off" 1 "ESP_TCS_on" 0 "ESP_TCS_off" ;
VAL_ 753 StopStartMsg_OnDemand_St 15 "Available" 14 "NoDataExist" 13 "NotUsed3" 12 "DriverDoorOpen" 11 "NotUsed2" 10 "NotUsed1" 9 "ClimateControl" 8 "Maneuvering" 7 "ChargingBattery" 6 "EngineManagement" 5 "OutsideAirTemperature" 4 "KeyFreeKeyNotInVehicle" 3 "Malfunction" 2 "ManualStartRequired" 1 "Off" 0 "EngineStopped" ;
VAL_ 753 DeflDetSysStatus 7 "Invalid" 6 "Reserved2" 5 "Reserved1" 4 "DDSInitNotPoss" 3 "DDSInitAck" 2 "TyrePressWarnDDSOk" 1 "DDSSysOkNoWarng" 0 "DDSSysFailOrNotSupprtd" ;
VAL_ 753 VS_ESPLongPress_St 1 "Active" 0 "Inactive" ;
VAL_ 753 PrkLckCtl_B_Enbl_St 1 "Enabled" 0 "Disabled" ;
VAL_ 753 PrkLckCtl_B_Allow_St 1 "Allowed" 0 "Not_Allowed" ;
VAL_ 753 TirePReset_D_Stat 3 "Not_Used" 2 "Nack" 1 "Ack" 0 "Null" ;
VAL_ 752 TransmDIWarnMsg3 15 "Message 15" 14 "Message 14" 13 "Message 13" 12 "Message 12" 11 "Message 11" 10 "Message 10" 9 "Message 9" 8 "Message 8" 7 "Message 7" 6 "Message 6" 5 "Message 5" 4 "Message 4" 3 "Message 3" 2 "Message 2" 1 "Message 1" 0 "No Message" ;
VAL_ 752 HillStartAssistOffWOChime_428 1 "Yes" 0 "No" ;
VAL_ 752 HillStartAssistOffWChime_582 1 "Yes" 0 "No" ;
VAL_ 752 HillStartAssistNotAvailable_429 1 "Yes" 0 "No" ;
VAL_ 752 HillStartAssistActive_427 1 "Yes" 0 "No" ;
VAL_ 752 PJB_TriggCause_419 12 "Heartbeat Sensor" 11 "Start Attempt" 10 "Siren" 9 "Right Rear Door" 0 "No Trig" 1 "Vehicle Power" 2 "Inclination Sensor" 3 "Volumetric Sensor" 4 "Bonnet" 5 "Trunk" 6 "Driver Door" 7 "Passenger Door" 8 "Left Rear Door" 13 "Radio" 14 "Ignore1" 15 "Ignore2" ;
VAL_ 752 AlarmServicerequired_476 1 "Yes" 0 "No" ;
VAL_ 752 PassengerDoorStatus2_214 1 "Yes" 0 "No" ;
VAL_ 752 DriverDoorStatus2_212 1 "Yes" 0 "No" ;
VAL_ 752 EpasFailed_258 1 "Yes" 0 "No" ;
VAL_ 752 ToStartPressBrake_485 1 "Yes" 0 "No" ;
VAL_ 752 ToStartPressNeutral_744 1 "Yes" 0 "No" ;
VAL_ 752 ToStartPressBrake_749 1 "Yes" 0 "No" ;
VAL_ 752 NotInPark_745 1 "Yes" 0 "No" ;
VAL_ 752 DoorOpenNotInPark_488 1 "Yes" 0 "No" ;
VAL_ 752 KVM_Service_567 1 "Yes" 0 "No" ;
VAL_ 752 CloseBootUseSpareKey_501 1 "Yes" 0 "No" ;
VAL_ 752 SCLFailureIndTorqued_500 1 "Yes" 0 "No" ;
VAL_ 752 SCLFailureIndStop_495 1 "Yes" 0 "No" ;
VAL_ 752 SCLFailureIndSERVICE_494 1 "Yes" 0 "No" ;
VAL_ 752 PKOutOfVehicle_498 1 "Yes" 0 "No" ;
VAL_ 752 PKNotDetected_496 1 "Yes" 0 "No" ;
VAL_ 752 HigherPowerMode_497 1 "Yes" 0 "No" ;
VAL_ 752 PressClutch_502 1 "Yes" 0 "No" ;
VAL_ 752 PressBrake_499 1 "Yes" 0 "No" ;
VAL_ 752 ExchangePKBattery_522 1 "Yes" 0 "No" ;
VAL_ 752 DisplayRequest_522 1 "Yes" 0 "No" ;
VAL_ 752 ISS_StatusDspReq_207 1 "Yes" 0 "No" ;
VAL_ 752 AutoLRainSSensorFail_729 1 "Yes" 0 "No" ;
VAL_ 752 LeftDIFailure_703 1 "Yes" 0 "No" ;
VAL_ 752 RightDIFailure_704 1 "Yes" 0 "No" ;
VAL_ 752 BonnetLidStatus2_217 1 "Yes" 0 "No" ;
VAL_ 752 BootLidStatus_216 1 "Yes" 0 "No" ;
VAL_ 752 PassengerSideRearDoorStatus2_215 1 "Yes" 0 "No" ;
VAL_ 752 DriverSideRearDoorStatus2_213 1 "Yes" 0 "No" ;
VAL_ 752 BootLidStatus_520 1 "Yes" 0 "No" ;
VAL_ 752 BonnetStatus_521 1 "Yes" 0 "No" ;
VAL_ 752 PassengerSideRearDoorStatus_519 1 "Yes" 0 "No" ;
VAL_ 752 DriverSideRearDoorStatus_518 1 "Yes" 0 "No" ;
VAL_ 752 DriverDoorStatus_516 1 "Yes" 0 "No" ;
VAL_ 752 BrakeWarningTelltale_746 1 "Yes" 0 "No" ;
VAL_ 752 ABS_Telltale_523 1 "Yes" 0 "No" ;
VAL_ 752 StabilityControlSt_218b 1 "Yes" 0 "No" ;
VAL_ 752 StabilityControlTel_218c 1 "Yes" 0 "No" ;
VAL_ 752 TransmDIWarnMsg_484 1 "Yes" 0 "No" ;
VAL_ 752 TransmissionFailure_483 1 "Yes" 0 "No" ;
VAL_ 752 DPFSootOverload_535 1 "Yes" 0 "No" ;
VAL_ 752 ChangeOilNow_469 1 "Yes" 0 "No" ;
VAL_ 752 PassengerDoorStatus_517 1 "Yes" 0 "No" ;
VAL_ 752 RIL_RequestStatus_530 1 "Yes" 0 "No" ;
VAL_ 752 BrakeFluidLevel_515 1 "Yes" 0 "No" ;
VAL_ 752 EngineCheck_440 1 "Yes" 0 "No" ;
VAL_ 752 EngOilPressureTelltale_526 1 "Yes" 0 "No" ;
VAL_ 752 SS_TurnIgnitionOff_643 1 "Yes" 0 "No" ;
VAL_ 752 SS_SelectNeutral_644 1 "Yes" 0 "No" ;
VAL_ 752 SS_PressClutch_641 1 "Yes" 0 "No" ;
VAL_ 752 SS_StartEngineManually_642 1 "Yes" 0 "No" ;
VAL_ 752 SS_EngineStarting_640 1 "Yes" 0 "No" ;
VAL_ 359 PrplWhlTot2_Tq_Actl 65535 "Fault" 65534 "NoDataExists" ;
VAL_ 359 ElPw_D_StatStrtStop 15 "NotUsed6" 14 "NotUsed5" 13 "NotUsed4" 12 "NotUsed3" 11 "NotUsed2" 10 "NotUsed1" 9 "Supported_Level_4" 8 "Supported_Level_3" 7 "Supported_Level_2" 6 "Supported_Level_1" 5 "Limited_Support" 4 "Fault_Limited" 3 "LV_Event_in_Progress" 2 "Not_Supported_Imminent" 1 "Supported_All" 0 "Not_Supported" ;
VAL_ 359 TrnAinTq_D_Qf 3 "OK" 2 "Not_Within_Specifications" 1 "No_Data_Exists" 0 "Fault" ;
VAL_ 359 PlgActvArb_B_Actl 1 "On" 0 "Off" ;
VAL_ 516 ApedPos_PcRate_ActlArb 255 "Fault" 254 "Unknown" ;
VAL_ 516 ApedPosPcActl_D_Qf 3 "OK" 2 "Not_Within_Specifications" 1 "No_Data_Exists" 0 "Fault" ;
VAL_ 516 EngAout3_N_Actl 65535 "Invalid" ;
VAL_ 754 ACU_ActChimeType_St 7 "Reserved4" 6 "Reserved3" 5 "Reserved2" 4 "Reserved1" 3 "Sample" 2 "Sine" 1 "No_Chime" 0 "Invalid" ;
VAL_ 391 ACU_CtrlChimeChan_Rq 3 "Reserved2" 2 "Reserved1" 1 "Mute" 0 "Inactive" ;
VAL_ 393 CPM_Audio_Source_RSP 2 "Stereo_SNK" 1 "Mono_SNK" 0 "OFF" ;
VAL_ 393 CPM_Audio_State_RSP 1 "Connect" 0 "Disconnect" ;
VAL_ 406 Audio_Source_Target_Cmd 1 "Connect" 0 "Disconnect" ;
VAL_ 406 Primary_Audio_Source_Target 5 "CPM_Stereo" 4 "CPM_Mono" 1 "Tuner_AM" 0 "OFF" ;
VAL_ 409 CPM_Audio_Source_REQ 2 "Stereo_SNK" 1 "Mono_SNK" 0 "OFF" ;
VAL_ 409 Audio_Bus_Request_CPM 1 "Connect" 0 "Disconnect" ;
VAL_ 408 Display_Overwrite_CPM_Req 1 "Clear_Field" 0 "OverWite_Field" ;
VAL_ 408 Display_Start_Position_CPM 1 "default" ;
VAL_ 408 Display_Target_CPM_Req 3 "MFD" 1 "ACM" 0 "NOP" ;
VAL_ 407 Dsp_MediaSrcAct_Rq 16 "SourceID16" 15 "SourceID15" 14 "SourceID14" 13 "SourceID13" 12 "SourceID12" 11 "SourceID11" 10 "SourceID10" 9 "SourceID9" 8 "SourceID8" 7 "SourceID7" 6 "SourceID6" 5 "SourceID5" 4 "SourceID4" 3 "SourceID3" 2 "SourceID2" 1 "SourceID1" 0 "Inactive" ;
VAL_ 407 Dsp_MediaSrcLst_Rq 1 "Request" 0 "Inactive" ;
VAL_ 407 Display_Requestor_ACM_Status 1 "CPM" 0 "NOP" ;
VAL_ 407 Display_Grant_ACM_Status 1 "Granted" 0 "Denied" ;
VAL_ 1003 CPM_Acceleration_St 0 "Invalid" 1 "Off" 2 "On" ;
VAL_ 1003 eCall_Event 3 "NotUsed" 2 "Inactive_Not_Supported" 1 "Active" 0 "Inactive" ;
VAL_ 1003 CPM_Stereo_PAS_Source 6 "MobileApp" 5 "iPOD" 4 "LineIn" 3 "BluetoothStereoBTST" 2 "USB2" 1 "USB" 0 "NoSourceSelected" ;
VAL_ 1003 CPM_Signal_Strength_STAT 7 "Phone_does_not_provide_this_info" 6 "Reserved2" 5 "Reserved1" 4 "Four_Signal_Strength_Bars" 3 "Three_Signal_Strength_Bars" 2 "Two_Signal_Strength_Bars" 1 "One_Signal_Strength_Bar" 0 "Zero_Signal_Strength_Bars" ;
VAL_ 1003 CPM_Mono_Audio_Output 1 "Unmute" 0 "Mute" ;
VAL_ 1003 CPM_Batt_Level_STAT 7 "Phone_does_not_provide_this_info" 6 "Reserved" 5 "Five_Battery_Level_Bars" 4 "Four_Battery_Level_Bars" 3 "Three_Battery_Level_Bars" 2 "Two_Battery_Level_Bars" 1 "One_Battery_Level_Bar" 0 "Zero_Battery_Level_Bars" ;
VAL_ 1003 CPM_TextMsg_AVAL 1 "Yes" 0 "No" ;
VAL_ 1003 CPM_Stereo_Audio_Output 1 "Unmute" 0 "Mute" ;
VAL_ 1003 CPM_Phone_Roaming_STAT 1 "Yes" 0 "No" ;
VAL_ 1003 CPM_Call_Active_STAT 1 "Yes" 0 "No" ;
VAL_ 1003 BT_ICON 1 "On" 0 "Off" ;
VAL_ 1003 CPM_VoiceRec_STAT 1 "On" 0 "Off" ;
VAL_ 675 NAV_Active_Screen_Status 255 "Invalid" 254 "Clock_Screen" 253 "Other_Audio" 252 "Device_Root_Screen" 251 "Top_Level_Menu" 9 "TDI_Menu" 8 "TDI_Base" 7 "Phone_Active_Call" 6 "Phonebook_List" 5 "Device_Settings_List" 4 "Menu_Settings_List" 3 "Media_Base" 2 "Media_Library_List" 1 "Reserved1" 0 "No_Active_Screen" 250 "Media_Device_List" ;
VAL_ 675 Current_Focus_Bar_St 7 "Focus_Bar_NA_on_current_Pop_Up" 6 "Focus_Bar_on_List_Item_6" 5 "Focus_Bar_on_List_Item_5" 4 "Focus_Bar_on_List_Item_4" 3 "Focus_Bar_on_List_Item_3" 2 "Focus_Bar_on_List_Item_2" 1 "Focus_Bar_on_List_Item_1" 0 "No_visible_Focus_Bar" ;
VAL_ 675 Dsp_LangSel_St 30 "Slovak" 29 "Arabic" 28 "Taiwanese" 27 "Mandarin_Chinese" 26 "Korean" 25 "AU_English" 24 "Japanese" 23 "Braz_Portuguese" 22 "EU_Portuguese" 21 "Finish" 20 "Norwegian" 19 "Danish" 18 "Swedish" 17 "Hungarian" 16 "Greek" 15 "Czech" 14 "Polish" 13 "Flemish" 12 "Dutch" 11 "Russian" 10 "Turkish" 9 "Mex_Spanish" 8 "EU_Spanish" 7 "Cana_French" 6 "EU_French" 5 "Italian" 4 "German" 3 "NA_English" 2 "UK_English" 1 "Unknown" 0 "Invalid" ;
VAL_ 675 Multimedia_System 1 "On" 0 "Off" ;
VAL_ 675 ACM_Display_Type 8 "MFD_NAV" 7 "MFD" 0 "Non_writable" ;
VAL_ 675 Pop_Up_Focus_Bar_St 7 "Focus_Bar_NA_on_current_Pop_Up" 6 "Focus_Bar_on_List_Item_6" 5 "Focus_Bar_on_List_Item_5" 4 "Focus_Bar_on_List_Item_4" 3 "Focus_Bar_on_List_Item_3" 2 "Focus_Bar_on_List_Item_2" 1 "Focus_Bar_on_List_Item_1" 0 "No_visible_Focus_Bar" ;
VAL_ 675 Active_Pop_Up_St 12 "Text_Reader" 11 "Phone_Dialing" 10 "TDI_TBT" 255 "Invalid" 254 "MFD_internal" 9 "VR_Commands" 8 "VR_Candidates" 7 "Call_Handling" 6 "Triple_Line_Active" 5 "Triple_Line_Passive" 4 "Double_Line_Active" 3 "Double_Line_Passive" 2 "Single_Line_Active" 1 "Single_Line_Passive" 0 "No_Pop_Up_Active" 14 "TDI_Options" 13 "TDI_List" ;
VAL_ 675 Primary_Audio_Source_ACM 5 "CPM_Stereo" 4 "CPM_Mono" 1 "Tuner_AM" 0 "OFF" ;
VAL_ 263 PrsnlCnnctReset_D_Rq 3 "ResetRequested" 2 "StartReset" 1 "EndReset" 0 "Null" ;
VAL_ 263 ACM_CPM_VR_CMND 1 "On" 0 "Off" ;
VAL_ 263 ACM_CPM_Stereo_Audio_CMND 1 "Unmute" 0 "Mute" ;
VAL_ 263 ACM_CPM_Mono_Audio_CMND 1 "Unmute" 0 "Mute" ;
VAL_ 262 Dsp_SetAcceleration_Rq 2 "On" 1 "Off" 0 "Inactive" ;
VAL_ 262 Dsp_RotAddrlAccLvl_St 7 "AccelerationLvl_7" 6 "AccelerationLvl_6" 5 "AccelerationLvl_5" 4 "AccelerationLvl_4" 3 "AccelerationLvl_3" 2 "AccelerationLvl_2" 1 "AccelerationLvl_1" 0 "AccelerationLvl_0" ;
VAL_ 262 Dsp_RotAddrBtnEv_St 7 "Inactive" ;
VAL_ 262 ACM_Target_ID 1 "CPM" 0 "NOP" ;
VAL_ 262 ACM_Button_State 2 "Button_Pressed" 1 "Button_Released" 0 "NOP" ;
VAL_ 534 WhlDirRr_D_Actl 3 "Failed" 2 "Unknown" 1 "Backward" 0 "Forward" ;
VAL_ 534 WhlDirRl_D_Actl 3 "Failed" 2 "Unknown" 1 "Backward" 0 "Forward" ;
VAL_ 534 WhlDirFr_D_Actl 3 "Failed" 2 "Unknown" 1 "Backward" 0 "Forward" ;
VAL_ 534 WhlDirFl_D_Actl 3 "Failed" 2 "Unknown" 1 "Backward" 0 "Forward" ;
VAL_ 656 HMI_DimmingLevelStatus 31 "NoDataExist" 30 "NotUsed10" 29 "NotUsed9" 28 "NotUsed8" 27 "NotUsed7" 26 "NotUsed6" 25 "NotUsed5" 24 "NotUsed4" 23 "NotUsed3" 22 "NotUsed2" 21 "NotUsed1" 20 "MaxBrightnessLevel" 19 "DimmerStep19" 18 "DimmerStep18" 17 "DimmerStep17" 16 "DimmerStep16" 15 "DimmerStep15" 14 "DimmerStep14" 13 "DimmerStep13" 12 "DimmerStep12" 11 "DimmerStep11" 10 "DimmerStep10" 9 "DimmerStep9" 8 "DimmerStep8" 7 "DimmerStep7" 6 "DimmerStep6" 5 "DimmerStep5" 4 "DimmerStep4" 3 "DimmerStep3" 2 "DimmerStep2" 1 "DimmerStep1" 0 "BarelyDiscernibleLevel" ;
VAL_ 656 HMI_DimmingModeStatus 3 "DisplayMaxBright" 2 "AutoDimmingMode" 1 "ManualDimmingMode" 0 "NoDataExist" ;
VAL_ 1008 CPM_MediaPlayerSrc_St 31 "Empty" 30 "Reserved14" 29 "Reserved13" 28 "Reserved12" 27 "Reserved11" 26 "Reserved10" 25 "Reserved9" 24 "Reserved8" 23 "Reserved7" 22 "Reserved6" 21 "Reserved5" 20 "Reserved4" 19 "Reserved3" 18 "Reserved2" 17 "Reserved1" 16 "SourceID16" 15 "SourceID15" 14 "SourceID14" 13 "SourceID13" 12 "SourceID12" 11 "SourceID11" 10 "SourceID10" 9 "SourceID9" 8 "SourceID8" 7 "SourceID7" 6 "SourceID6" 5 "SourceID5" 4 "SourceID4" 3 "SourceID3" 2 "SourceID2" 1 "SourceID1" 0 "NoDataExists" ;
VAL_ 404 Dsp_LangUpdate_Rsp 2 "Language_Not_Supported" 1 "Language_Updated" 0 "Inactive" ;
VAL_ 291 LangUpdate_Rsp 2 "Language_Not_Supported" 1 "Language_Updated" 0 "Inactive" ;
VAL_ 493 Dsp_AFJump_Rq 2 "Enable" 1 "Inhibit" 0 "Inactive" ;
VAL_ 493 Dsp_RefreshFlag 1 "True" 0 "False" ;
VAL_ 493 Dsp_StatLiScanCancel_Rq 1 "Cancel" 0 "Inactive" ;
VAL_ 493 Dsp_StationList_Rq 15 "reserved_last" 8 "reserved" 7 "DAB_Service_List" 6 "DAB_Ensemble_Service_List" 5 "Analog_FM_PTY_List" 4 "Analog_and_HD_FM_List" 3 "HD_FM_List" 2 "Analog_FM_List" 1 "Analog_AM_List" 0 "Inactive" ;
VAL_ 402 ApaMdeStat_D_RqDrv 7 "Faulty" 6 "Off" 5 "NotUsed2" 4 "NotUsed1" 3 "POA" 2 "PPA" 1 "SAPP" 0 "Inactive" ;
VAL_ 402 DistanceBarSetting 1 "On" 0 "Off" ;
VAL_ 402 CamraZoomMan_D_Rq 7 "Unknown" 6 "Invalid" 5 "Zoom_Level_V" 4 "Zoom_Level_IV" 3 "Zoom_Level_III" 2 "Zoom_Level_II" 1 "Zoom_Level_I" 0 "Off" ;
VAL_ 402 CamraOvrlStat_D_Rq 1 "On" 0 "Off" ;
VAL_ 402 CamraOvrlDyn_D_Rq 1 "On" 0 "Off" ;
VAL_ 402 CamAutoTowbarZoom 1 "On" 0 "Off" ;
VAL_ 402 CamraOvrlTow_D_Rq 1 "On" 0 "Off" ;
VAL_ 265 PrkAidLamp_D_Rq_UB 1 "Fresh_data" 0 "Unchanged_data" ;
VAL_ 265 PrkAidLamp_D_Rq 3 "Not_Used" 2 "Flash" 1 "On" 0 "Off" ;
VAL_ 265 EngineSpeedQF 3 "OK" 2 "Not_Within_Specifications" 1 "No_Data_Exists" 0 "Faulty" ;
VAL_ 265 Light_SW_Position 31 "Invalid" 30 "NotUsed9" 29 "NotUsed8" 28 "NotUsed7" 27 "NotUsed6" 26 "NotUsed5" 25 "NotUsed4" 24 "NotUsed3" 23 "NotUsed2" 22 "NotUsed1" 21 "NoDimmerSwitchPresent" 20 "MaxBrightnessLevel" 19 "DimmingStep19" 18 "DimmingStep18" 17 "DimmingStep17" 16 "DimmingStep16" 15 "DimmingStep15" 14 "DimmingStep14" 13 "DimmingStep13" 12 "DimmingStep12" 11 "DimmingStep11" 10 "DimmingStep10" 9 "DimmingStep9" 8 "DimmingStep8" 7 "DimmingStep7" 6 "DimmingStep6" 5 "DimmingStep5" 4 "DimmingStep4" 3 "DimmingStep3" 2 "DimmingStep2" 1 "DimmingStep1" 0 "BarelyDiscernibleLevel" ;
VAL_ 265 KeyMykeyTot_No_Cnt 13 "Thirteen" 12 "Twelve" 11 "Eleven" 10 "Ten" 9 "Nine" 8 "Eight" 7 "Seven" 6 "Six" 5 "Five" 4 "Four" 3 "Three" 2 "Two" 1 "One" 0 "Zero" 15 "Invalid" 14 "Unlimited" ;
VAL_ 265 IgnKeyType_D_Actl 15 "Invalid" 14 "Unknown" 3 "Key_Not_Prgrm_Read_Failure" 2 "Key_In_Ign_My_Key" 1 "Key_In_Ign_Standard_Key" 0 "Key_Read_In_Progress" ;
VAL_ 265 VehVActlEng_D_Qf 3 "OK" 2 "Not_Within_Specifications" 1 "No_Data_Exists" 0 "Faulty" ;
VAL_ 265 GearLvrPos_D_Actl 15 "Fault" 14 "Unknown_Position" 13 "Undefined_Treat_as_Fault1" 12 "Undefined_Treat_as_Fault" 11 "sixth" 10 "fifth" 9 "fourth" 8 "third" 7 "second" 6 "first" 5 "Low" 4 "Sport_DriveSport" 3 "Drive" 2 "Neutral" 1 "Reverse" 0 "Park" ;
VAL_ 265 GearRvrseActv_D_Actl 3 "Fault" 2 "Unknown" 1 "Active" 0 "Inactive" ;
VAL_ 265 Fuel_Level_State 3 "Invalid" 2 "Unknown" 1 "Low" 0 "OK" ;
VAL_ 265 PwPck_D_Stat_UB 1 "Fresh_data" 0 "Unchanged_data" ;
VAL_ 265 PwPck_D_Stat 3 "PreStarting" 2 "Ready" 1 "Awake" 0 "Init" 15 "Undefined" 14 "Undefined" 13 "Undefined" 12 "Undefined" 11 "Undefined" 10 "Undefined" 9 "AfterRun" 8 "Running_RemoteStarted" 7 "Running_StartingInProgress" 6 "Running_Standby" 5 "Running_Running" 4 "StartingInProgress" ;
VAL_ 758 SDARS_OpMode_St 7 "FastRewindSpeed2" 6 "FastRewindSpeed1" 5 "FastForwardSpeed2" 4 "FastForwardSpeed1" 3 "Pause" 2 "Play" 1 "Stop" 0 "Invalid" ;
VAL_ 758 SDARS_Factory_Reset_St 1 "FactorySettingsRestored" 0 "Invalid" ;
VAL_ 761 SDARS_Seek_Scan_St 1 "NoChannelsAvailable" 0 "Invalid" ;
VAL_ 761 SDARS_Invalid_Chan_St 0 "Invalid" 2 "Active" 1 "Inactive" ;
VAL_ 761 SDARS_UnSubscrb_Chan_St 0 "Invalid" 2 "Active" 1 "Inactive" ;
VAL_ 761 SDARS_Loss_Ant_St 0 "Invalid" 2 "Active" 1 "Inactive" ;
VAL_ 761 SDARS_UnSubscrb_St 0 "Invalid" 2 "Active" 1 "Inactive" ;
VAL_ 761 SDARS_Subscription_St 0 "Invalid" 2 "Active" 1 "Inactive" ;
VAL_ 761 SDARS_GCI_Update_St 0 "Invalid" 2 "Active" 1 "Inactive" ;
VAL_ 761 SDARS_Firmware_Update_St 0 "Invalid" 2 "Active" 1 "Inactive" ;
VAL_ 761 SDARS_Antenna_Err_St 0 "Invalid" 2 "Active" 1 "Inactive" ;
VAL_ 761 SDARS_Receive_Err_St 0 "Invalid" 2 "Active" 1 "Inactive" ;
VAL_ 761 SDARS_Error_Conf_St 0 "Invalid" 2 "SDARS_OFF" 1 "SDARS_ON" ;
VAL_ 760 SDARS_Alert_Status 0 "Invalid" 2 "Disabled" 1 "Enabled" ;
VAL_ 760 SDARS_Channel_Lock 0 "Invalid" 2 "Unlocked" 1 "Locked" ;
VAL_ 260 SDARS_GetESN_Rq 1 "RequestESN" 0 "Invalid" ;
VAL_ 260 SDARS_FactoryReset_Rq 1 "ResetFactoryDefaults" 0 "Invalid" ;
VAL_ 260 MFD_SDARS_SetOpMode_Rq 7 "FastRewindSpeed2" 6 "FastRewindSpeed1" 5 "FastForwardSpeed2" 4 "FastForwardSpeed1" 3 "Pause" 2 "Play" 1 "Stop" 0 "Invalid" ;
VAL_ 260 SDARS_SRReplay_Rq 2 "Disable" 1 "Enable" 0 "Inactive" ;
VAL_ 259 SDARS_AlertStatus_Rq 2 "Disable" 1 "Enable" 0 "Inactive" ;
VAL_ 759 Avail_HD_Chan_Valid 1 "Valid" 0 "Invalid" ;
VAL_ 759 Avail_HD_Chan_St_7 1 "Available" 0 "Not_Available" ;
VAL_ 759 Avail_HD_Chan_St_6 1 "Available" 0 "Not_Available" ;
VAL_ 759 Avail_HD_Chan_St_5 1 "Available" 0 "Not_Available" ;
VAL_ 759 Avail_HD_Chan_St_4 1 "Available" 0 "Not_Available" ;
VAL_ 759 Avail_HD_Chan_St_3 1 "Available" 0 "Not_Available" ;
VAL_ 759 Avail_HD_Chan_St_2 1 "Available" 0 "Not_Available" ;
VAL_ 759 Avail_HD_Chan_St_1 1 "Available" 0 "Not_Available" ;
VAL_ 759 ACM_StationListScanSt 1 "Scan_Cancelled" ;
VAL_ 759 ACM_TagMode 2 "On" 1 "Off" 0 "Inactive" ;
VAL_ 759 ACM_RBDSMode 2 "On" 1 "Off" 0 "Inactive" ;
VAL_ 759 NumofHDMulticastChans_St 7 "7_Multicast_Available" 6 "6_Multicast_Available" 5 "5_Multicast_Available" 4 "4_Multicast_Available" 3 "3_Multicast_Available" 2 "2_Multicast_Available" 1 "1_Multicast_Available" 0 "0" ;
VAL_ 759 ACM_HDModeStatus 2 "On" 1 "Off" 0 "Inactive" ;
VAL_ 759 ACM_HDChanStatus 4 "Not_Found" 3 "Not_Multicast" 2 "Acquired" 1 "Acquiring" ;
VAL_ 759 ACM_CurrentHDMulticast_St 7 "7" 6 "6" 5 "5" 4 "4" 3 "3" 2 "2" 1 "1" 0 "0" ;
VAL_ 947 Outside_Air_Temp_Stat_UB 1 "Fresh_data" 0 "Unchanged_data" ;
VAL_ 947 Outside_Air_Temp_Stat 254 "Unknown" 255 "Invalid" ;
VAL_ 947 Ignition_Switch_Stable 2 "Missing_From_Transmitter" 1 "Ignition_Switch_Stable" 0 "Ignition_Switch_Not_Stable" ;
VAL_ 947 PrkBrkActv_B_Actl 1 "Active" 0 "Inactive" ;
VAL_ 947 Ignition_Status 15 "Invalid" 8 "Start" 4 "Run" 2 "Accessory" 1 "Off" 0 "Unknown" ;
VAL_ 129 SuspDampInc_B_RqDrv 1 "Pressed" 0 "Not_Pressed" ;
VAL_ 129 SteEffortInc_B_RqDrv 1 "Pressed" 0 "Not_Pressed" ;
VAL_ 129 SelDrvMdeInc_B_RqDrv 1 "Pressed" 0 "Not_Pressed" ;
VAL_ 129 SelDrvMdeDec_B_RqDrv 1 "Pressed" 0 "Not_Pressed" ;
VAL_ 129 SteWhlSwtchUp_B_Stat 1 "Pressed" 0 "Not_Pressed" ;
VAL_ 129 SteWhlSwtchRght_B_Stat 1 "Pressed" 0 "Not_Pressed" ;
VAL_ 129 SteWhlSwtchOk_B_Stat 1 "Pressed" 0 "Not_Pressed" ;
VAL_ 129 SteWhlSwtchLeft_B_Stat 1 "Pressed" 0 "Not_Pressed" ;
VAL_ 129 SteWhlSwtchDown_B_Stat 1 "Pressed" 0 "Not_Pressed" ;
VAL_ 129 SteWhlCtl_Phone_UB 1 "Fresh_data" 0 "Unchanged_data" ;
VAL_ 129 SteWhlCtl_Phone 1 "Button_Pressed" 0 "Button_Not_Pressed" ;
VAL_ 129 SteWhlCtl_Mute_UB 1 "Fresh_data" 0 "Unchanged_data" ;
VAL_ 129 SteWhlCtl_Mute 1 "Button_Pressed" 0 "Button_Not_Pressed" ;
VAL_ 129 SteWhlCtl_Volume_Up_UB 1 "Fresh_data" 0 "Unchanged_data" ;
VAL_ 129 SteWhlCtl_Volume_Down_UB 1 "Fresh_data" 0 "Unchanged_data" ;
VAL_ 129 SteWhlCtl_Voice_PTT_UB 1 "Fresh_data" 0 "Unchanged_data" ;
VAL_ 129 SteWhlCtl_Seek_Right_UB 1 "Fresh_data" 0 "Unchanged_data" ;
VAL_ 129 SteWhlCtl_Seek_Left_UB 1 "Fresh_data" 0 "Unchanged_data" ;
VAL_ 129 SteWhlCtl_RSideCursLeft_UB 1 "Fresh_data" 0 "Unchanged_data" ;
VAL_ 129 SteWhlCtl_RSideCursDown_UB 1 "Fresh_data" 0 "Unchanged_data" ;
VAL_ 129 SteWhlCtl_RSide_OK_UB 1 "Fresh_data" 0 "Unchanged_data" ;
VAL_ 129 SteWhlCtl_RSide_CursUp_UB 1 "Fresh_data" 0 "Unchanged_data" ;
VAL_ 129 SteWhlCtl_RSide_CursRt_UB 1 "Fresh_data" 0 "Unchanged_data" ;
VAL_ 129 SteWhlCtl_Mode_UB 1 "Fresh_data" 0 "Unchanged_data" ;
VAL_ 129 SteWhlCtl_Volume_Up 1 "Button_Pressed" 0 "Button_Not_Pressed" ;
VAL_ 129 SteWhlCtl_Volume_Down 1 "Button_Pressed" 0 "Button_Not_Pressed" ;
VAL_ 129 SteWhlCtl_Voice_PTT 1 "Button_Pressed" 0 "Button_Not_Pressed" ;
VAL_ 129 SteWhlCtl_Seek_Right 1 "Button_Pressed" 0 "Button_Not_Pressed" ;
VAL_ 129 SteWhlCtl_Seek_Left 1 "Button_Pressed" 0 "Button_Not_Pressed" ;
VAL_ 129 SteWhlCtl_Mode 1 "Button_Pressed" 0 "Button_Not_Pressed" ;
VAL_ 129 SteWhlCtl_RSide_OK 1 "Button_Pressed" 0 "Button_Not_Pressed" ;
VAL_ 129 SteWhlCtl_RSide_CursorUp 1 "Button_Pressed" 0 "Button_Not_Pressed" ;
VAL_ 129 SteWhlCtl_RSide_CursorRt 1 "Button_Pressed" 0 "Button_Not_Pressed" ;
VAL_ 129 SteWhlCtl_RSide_CursorLeft 1 "Button_Pressed" 0 "Button_Not_Pressed" ;
VAL_ 129 SteWhlCtl_RSide_CursorDown 1 "Button_Pressed" 0 "Button_Not_Pressed" ;
VAL_ 129 SteWhlCtl_Media_UB 1 "Fresh_data" 0 "Unchanged_data" ;
VAL_ 129 SteWhlCtl_Media 1 "Button_Pressed" 0 "Button_Not_Pressed" ;
VAL_ 855 RrDefrost_HtdMirrState 1 "On" 0 "Off" ;
VAL_ 855 RrDefHtdMirrLdShedStat 3 "Automatic_Override" 2 "Shed2_Cont_Override" 1 "Shed2_Trans_Override" 0 "No_Shed" ;
VAL_ 855 Recirc_Door_State 3 "Fault" 2 "In_Forced_Outside_Position" 1 "In_Forced_Recirc_Position" 0 "User_Selected" ;
VAL_ 855 Rear_System_Mode_State 4 "Enabled_or_Auto" 3 "Floor" 2 "Panel_Floor" 1 "Panel" 0 "Off" ;
VAL_ 855 Default_Defrost_State 1 "Yes" 0 "No" ;
VAL_ 855 Auto_AC_Indicator_Temp 1 "High" 0 "Low" ;
VAL_ 855 RrBlwrCondStLdShedStat 3 "Automatic_Override" 2 "HMI_Override" 1 "No_HMI_Override" 0 "No_Shed" ;
VAL_ 855 FrBlwrCondStLdShedStat 3 "Automatic_Override" 2 "HMI_Override" 1 "No_HMI_Override" 0 "No_Shed" ;
VAL_ 856 SlidHtdBkLtInEn_B_Stat 1 "Enable" 0 "Disable" ;
VAL_ 856 RCCM_PR_Cond_Seat_Lvl 6 "Fault" 5 "Level_5_Most_Conditioning" 4 "Level_4" 3 "Level_3" 2 "Level_2" 1 "Level_1_Least_Conditioning" 0 "Off" ;
VAL_ 856 RCCM_PR_Cond_Seat_Req 3 "RCCM_Is_Master" 2 "Heating_Requested" 1 "Cooling_Requested" 0 "Off" ;
VAL_ 856 RCCM_PF_Cond_Seat_Req 3 "RCCM_Is_Master" 2 "Heating_Requested" 1 "Cooling_Requested" 0 "Off" ;
VAL_ 856 RCCM_PF_Cond_Seat_Lvl 6 "Fault" 5 "Level_5_Most_Conditioning" 4 "Level_4" 3 "Level_3" 2 "Level_2" 1 "Level_1_Least_Conditioning" 0 "Off" ;
VAL_ 856 RCCM_DR_Cond_Seat_Req 3 "RCCM_Is_Master" 2 "Heating_Requested" 1 "Cooling_Requested" 0 "Off" ;
VAL_ 856 RCCM_DR_Cond_Seat_Lvl 6 "Fault" 5 "Level_5_Most_Conditioning" 4 "Level_4" 3 "Level_3" 2 "Level_2" 1 "Level_1_Least_Conditioning" 0 "Off" ;
VAL_ 856 RCCM_DF_Cond_Seat_Req 3 "RCCM_Is_Master" 2 "Heating_Requested" 1 "Cooling_Requested" 0 "Off" ;
VAL_ 856 RCCM_DF_Cond_Seat_Lvl 6 "Fault" 5 "Level_5_Most_Conditioning" 4 "Level_4" 3 "Level_3" 2 "Level_2" 1 "Level_1_Least_Conditioning" 0 "Off" ;
VAL_ 856 PassRrCondStLdShedStat 3 "Automatic_Override" 2 "HMI_Override" 1 "No_HMI_Override" 0 "No_Shed" ;
VAL_ 856 PassFrCondStLdShedStat 3 "Automatic_Override" 2 "HMI_Override" 1 "No_HMI_Override" 0 "No_Shed" ;
VAL_ 856 DrvRrCondStLdShedStat 3 "Automatic_Override" 2 "HMI_Override" 1 "No_HMI_Override" 0 "No_Shed" ;
VAL_ 856 DrvFrCondStLdShedStat 3 "Automatic_Override" 2 "HMI_Override" 1 "No_HMI_Override" 0 "No_Shed" ;
VAL_ 856 CC_HtdStrWhl_Req 1 "Request_On" 0 "No_Request" ;
VAL_ 856 Active_My_Temp 1 "On" 0 "Off" ;
